VERSION "eCMP INFO-DIV vehicle review 2026-11-03; 125000 bit/s; PSA-RE 67f7581e7622410efdbb29c7eda3b86982b9b450; Apache-2.0"

NS_ :

BS_:

BU_: AAS AMPLI AVP BCM BGP BSG BSI BTA BTEL BTT CDC CMB CRT DIAG_TOOL EDP_C EMF FMUX IC ICSV IDVR IVC_D MATT MDS OVIP PDS_C RAD RBG SDCM VTH WLC

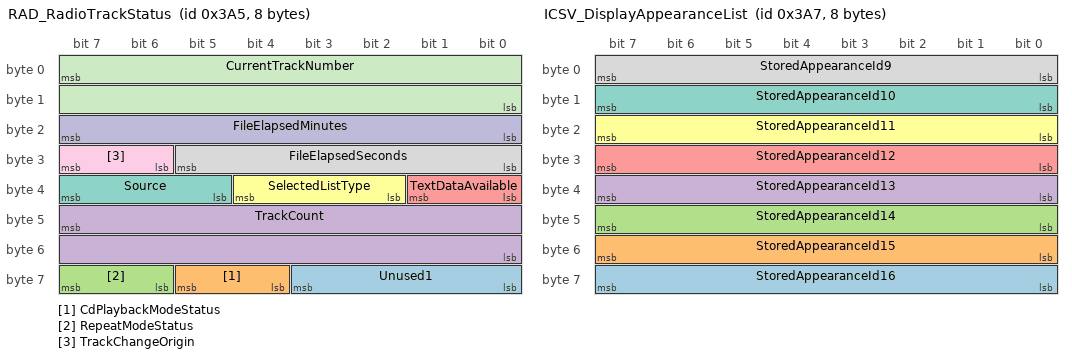
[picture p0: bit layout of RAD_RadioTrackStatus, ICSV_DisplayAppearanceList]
BO_ 933 RAD_RadioTrackStatus: 8 RAD
 SG_ Unused1 : 59|4@0+ (1,0) [0|15] ""  CRT,FMUX,EMF
 SG_ CdPlaybackModeStatus : 61|2@0+ (1,0) [0|3] ""  CRT,FMUX,EMF
 SG_ RepeatModeStatus : 63|2@0+ (1,0) [0|3] ""  CRT,FMUX,EMF
 SG_ TrackCount : 47|16@0+ (1,0) [0|65533] ""  CRT,FMUX,EMF
 SG_ TextDataAvailable : 33|2@0+ (1,0) [0|3] ""  CRT,FMUX,EMF
 SG_ SelectedListType : 36|3@0+ (1,0) [0|7] ""  CRT,FMUX,EMF
 SG_ Source : 39|3@0+ (1,0) [0|7] ""  CRT,FMUX,EMF
 SG_ FileElapsedSeconds : 29|6@0+ (1,0) [0|59] "s"  CRT,FMUX,EMF
 SG_ TrackChangeOrigin : 31|2@0+ (1,0) [0|3] ""  CRT,FMUX,EMF
 SG_ FileElapsedMinutes : 23|8@0+ (1,0) [0|253] "min"  CRT,FMUX,EMF
 SG_ CurrentTrackNumber : 7|16@0+ (1,0) [1|65533] ""  CRT,FMUX,EMF

BO_ 935 ICSV_DisplayAppearanceList: 8 ICSV
 SG_ StoredAppearanceId16 : 63|8@0+ (1,0) [0|255] ""  BTEL,OVIP
 SG_ StoredAppearanceId15 : 55|8@0+ (1,0) [0|255] ""  BTEL,OVIP
 SG_ StoredAppearanceId14 : 47|8@0+ (1,0) [0|255] ""  BTEL,OVIP
 SG_ StoredAppearanceId13 : 39|8@0+ (1,0) [0|255] ""  BTEL,OVIP
 SG_ StoredAppearanceId12 : 31|8@0+ (1,0) [0|255] ""  BTEL,OVIP
 SG_ StoredAppearanceId11 : 23|8@0+ (1,0) [0|255] ""  BTEL,OVIP
 SG_ StoredAppearanceId10 : 15|8@0+ (1,0) [0|255] ""  BTEL,OVIP
 SG_ StoredAppearanceId9 : 7|8@0+ (1,0) [0|255] ""  BTEL,OVIP

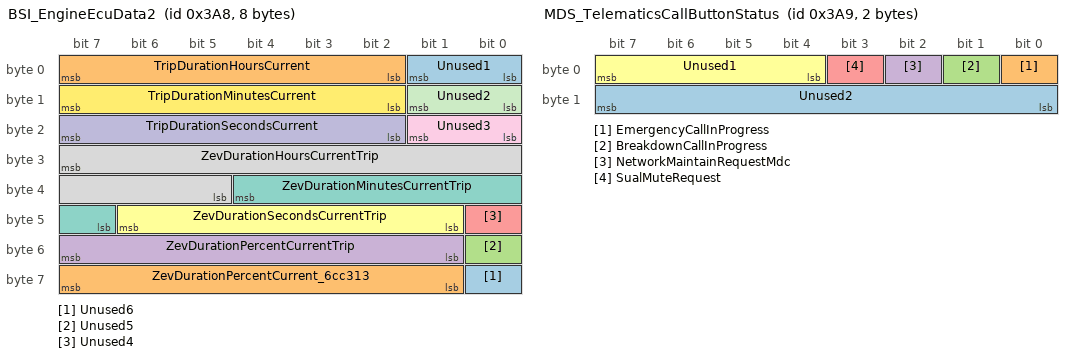
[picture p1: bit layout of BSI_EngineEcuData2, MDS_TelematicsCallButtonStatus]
BO_ 936 BSI_EngineEcuData2: 8 BSI
 SG_ Unused6 : 56|1@0+ (1,0) [0|1] ""  OVIP,RAD
 SG_ ZevDurationPercentCurrent_6cc313 : 63|7@0+ (1,0) [0|100] "%"  OVIP,RAD
 SG_ Unused5 : 48|1@0+ (1,0) [0|1] ""  OVIP,RAD
 SG_ ZevDurationPercentCurrentTrip : 55|7@0+ (1,0) [0|100] "%"  OVIP,RAD
 SG_ Unused4 : 40|1@0+ (1,0) [0|1] ""  OVIP,RAD
 SG_ ZevDurationSecondsCurrentTrip : 46|6@0+ (1,0) [0|59] "s"  OVIP,RAD
 SG_ ZevDurationMinutesCurrentTrip : 36|6@0+ (1,0) [0|59] "min"  OVIP,RAD
 SG_ ZevDurationHoursCurrentTrip : 31|11@0+ (1,0) [0|2000] "h"  OVIP,RAD
 SG_ Unused3 : 17|2@0+ (1,0) [0|3] ""  OVIP,RAD
 SG_ TripDurationSecondsCurrent : 23|6@0+ (1,0) [0|59] "s"  OVIP,RAD
 SG_ Unused2 : 9|2@0+ (1,0) [0|3] ""  OVIP,RAD
 SG_ TripDurationMinutesCurrent : 15|6@0+ (1,0) [0|59] "min"  OVIP,RAD
 SG_ Unused1 : 1|2@0+ (1,0) [0|3] ""  OVIP,RAD
 SG_ TripDurationHoursCurrent : 7|6@0+ (1,0) [0|62] "h"  OVIP,RAD

BO_ 937 MDS_TelematicsCallButtonStatus: 2 MDS
 SG_ Unused2 : 15|8@0+ (1,0) [0|255] ""  OVIP,BTEL,BSI,RAD
 SG_ EmergencyCallInProgress : 0|1@0+ (1,0) [0|1] ""  OVIP,BTEL,BSI,RAD
 SG_ BreakdownCallInProgress : 1|1@0+ (1,0) [0|1] ""  OVIP,BTEL,BSI,RAD
 SG_ NetworkMaintainRequestMdc : 2|1@0+ (1,0) [0|1] ""  OVIP,BTEL,BSI,RAD
 SG_ SualMuteRequest : 3|1@0+ (1,0) [0|1] ""  OVIP,BTEL,BSI,RAD
 SG_ Unused1 : 7|4@0+ (1,0) [0|15] ""  OVIP,BTEL,BSI,RAD

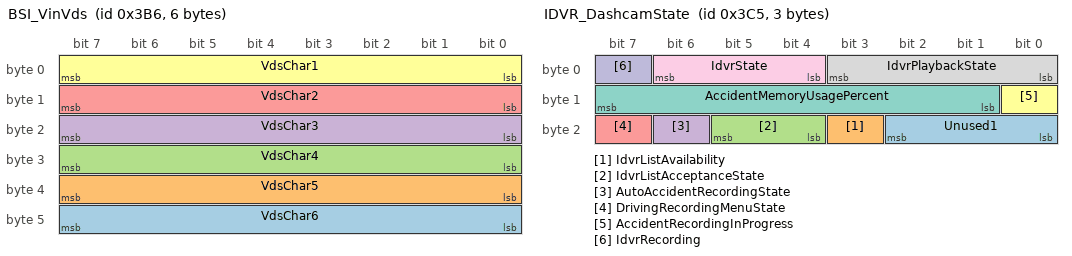
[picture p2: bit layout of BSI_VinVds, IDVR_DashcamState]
BO_ 950 BSI_VinVds: 6 BSI
 SG_ VdsChar6 : 47|8@0+ (1,0) [0|255] "raw"  OVIP,EMF,CDC,RAD,MDS,BGP,BTEL
 SG_ VdsChar5 : 39|8@0+ (1,0) [0|255] "raw"  OVIP,EMF,CDC,RAD,MDS,BGP,BTEL
 SG_ VdsChar4 : 31|8@0+ (1,0) [0|255] "raw"  OVIP,EMF,CDC,RAD,MDS,BGP,BTEL
 SG_ VdsChar3 : 23|8@0+ (1,0) [0|255] "raw"  OVIP,EMF,CDC,RAD,MDS,BGP,BTEL
 SG_ VdsChar2 : 15|8@0+ (1,0) [0|255] "raw"  OVIP,EMF,CDC,RAD,MDS,BGP,BTEL
 SG_ VdsChar1 : 7|8@0+ (1,0) [0|255] "raw"  OVIP,EMF,CDC,RAD,MDS,BGP,BTEL

BO_ 961 SDCM_WirelessChargerRxFlo_ebe318: 8 SDCM
 SG_ FlowPadding5 m3 : 63|8@0+ (1,0) [0|255] "raw"  WLC
 SG_ FirstData6 m1 : 63|8@0+ (1,0) [0|255] "raw"  WLC
 SG_ UnknownData7 m4 : 63|8@0+ (1,0) [0|255] "raw"  WLC
 SG_ ConsecutiveData7 m2 : 63|8@0+ (1,0) [0|255] "raw"  WLC
 SG_ SingleData7 m0 : 63|8@0+ (1,0) [0|255] "raw"  WLC
 SG_ FlowPadding4 m3 : 55|8@0+ (1,0) [0|255] "raw"  WLC
 SG_ FirstData5 m1 : 55|8@0+ (1,0) [0|255] "raw"  WLC
 SG_ UnknownData6 m4 : 55|8@0+ (1,0) [0|255] "raw"  WLC
 SG_ ConsecutiveData6 m2 : 55|8@0+ (1,0) [0|255] "raw"  WLC
 SG_ SingleData6 m0 : 55|8@0+ (1,0) [0|255] "raw"  WLC
 SG_ FlowPadding3 m3 : 47|8@0+ (1,0) [0|255] "raw"  WLC
 SG_ FirstData4 m1 : 47|8@0+ (1,0) [0|255] "raw"  WLC
 SG_ UnknownData5 m4 : 47|8@0+ (1,0) [0|255] "raw"  WLC
 SG_ ConsecutiveData5 m2 : 47|8@0+ (1,0) [0|255] "raw"  WLC
 SG_ SingleData5 m0 : 47|8@0+ (1,0) [0|255] "raw"  WLC
 SG_ FlowPadding2 m3 : 39|8@0+ (1,0) [0|255] "raw"  WLC
 SG_ FirstData3 m1 : 39|8@0+ (1,0) [0|255] "raw"  WLC
 SG_ UnknownData4 m4 : 39|8@0+ (1,0) [0|255] "raw"  WLC
 SG_ ConsecutiveData4 m2 : 39|8@0+ (1,0) [0|255] "raw"  WLC
 SG_ SingleData4 m0 : 39|8@0+ (1,0) [0|255] "raw"  WLC
 SG_ FlowPadding1 m3 : 31|8@0+ (1,0) [0|255] "raw"  WLC
 SG_ FirstData2 m1 : 31|8@0+ (1,0) [0|255] "raw"  WLC
 SG_ UnknownData3 m4 : 31|8@0+ (1,0) [0|255] "raw"  WLC
 SG_ ConsecutiveData3 m2 : 31|8@0+ (1,0) [0|255] "raw"  WLC
 SG_ SingleData3 m0 : 31|8@0+ (1,0) [0|255] "raw"  WLC
 SG_ FirstData1 m1 : 23|8@0+ (1,0) [0|255] "raw"  WLC
 SG_ UnknownData2 m4 : 23|8@0+ (1,0) [0|255] "raw"  WLC
 SG_ ConsecutiveData2 m2 : 23|8@0+ (1,0) [0|255] "raw"  WLC
 SG_ SingleData2 m0 : 23|8@0+ (1,0) [0|255] "raw"  WLC
 SG_ SeparationTimeRaw m3 : 23|8@0+ (1,0) [0|255] "raw"  WLC
 SG_ UnknownData1 m4 : 15|8@0+ (1,0) [0|255] "raw"  WLC
 SG_ ConsecutiveData1 m2 : 15|8@0+ (1,0) [0|255] "raw"  WLC
 SG_ SingleData1 m0 : 15|8@0+ (1,0) [0|255] "raw"  WLC
 SG_ BlockSize m3 : 15|8@0+ (1,0) [0|255] "raw"  WLC
 SG_ UnknownPciLow m4 : 3|4@0+ (1,0) [0|15] "raw"  WLC
 SG_ FlowStatus m3 : 3|4@0+ (1,0) [0|15] "raw"  WLC
 SG_ ConsecutiveSequence m2 : 3|4@0+ (1,0) [0|15] "raw"  WLC
 SG_ FirstFrameLength m1 : 3|12@0+ (1,0) [0|4095] "raw"  WLC
 SG_ SingleFrameLength m0 : 3|4@0+ (1,0) [0|15] "raw"  WLC
 SG_ IsoTpFrameType M : 7|4@0+ (1,0) [0|15] ""  WLC

BO_ 965 IDVR_DashcamState: 3 IDVR
 SG_ Unused1 : 18|3@0+ (1,0) [0|7] ""  BTEL,OVIP
 SG_ IdvrListAvailability : 19|1@0+ (1,0) [0|1] ""  BTEL,OVIP
 SG_ IdvrListAcceptanceState : 21|2@0+ (1,0) [0|3] ""  BTEL,OVIP
 SG_ AutoAccidentRecordingState : 22|1@0+ (1,0) [0|1] ""  BTEL,OVIP
 SG_ DrivingRecordingMenuState : 23|1@0+ (1,0) [0|1] ""  BTEL,OVIP
 SG_ AccidentRecordingInProgress : 8|1@0+ (1,0) [0|1] ""  BTEL,OVIP
 SG_ AccidentMemoryUsagePercent : 15|7@0+ (1,0) [0|100] "%"  BTEL,OVIP
 SG_ IdvrPlaybackState : 3|4@0+ (1,0) [0|15] ""  BTEL,OVIP
 SG_ IdvrState : 6|3@0+ (1,0) [0|7] ""  BTEL,OVIP
 SG_ IdvrRecording : 7|1@0+ (1,0) [0|1] ""  BTEL,OVIP

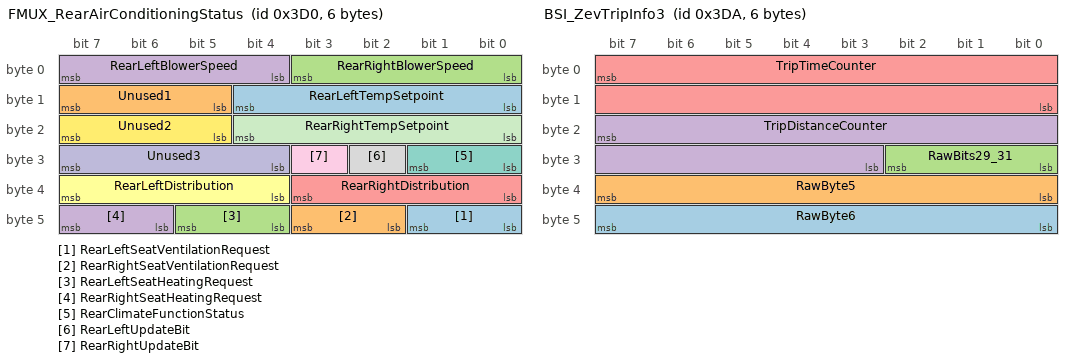
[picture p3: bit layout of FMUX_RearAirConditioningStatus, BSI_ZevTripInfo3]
BO_ 976 FMUX_RearAirConditioningStatus: 6 FMUX
 SG_ RearLeftSeatVentilationRequest : 41|2@0+ (1,0) [0|3] ""  ICSV,BTEL,CMB,BSI,OVIP,RAD
 SG_ RearRightSeatVentilationRequest : 43|2@0+ (1,0) [0|3] ""  ICSV,BTEL,CMB,BSI,OVIP,RAD
 SG_ RearLeftSeatHeatingRequest : 45|2@0+ (1,0) [0|3] ""  ICSV,BTEL,CMB,BSI,OVIP,RAD
 SG_ RearRightSeatHeatingRequest : 47|2@0+ (1,0) [0|3] ""  ICSV,BTEL,CMB,BSI,OVIP,RAD
 SG_ RearRightDistribution : 35|4@0+ (1,0) [0|15] ""  ICSV,BTEL,CMB,BSI,OVIP,RAD
 SG_ RearLeftDistribution : 39|4@0+ (1,0) [0|15] ""  ICSV,BTEL,CMB,BSI,OVIP,RAD
 SG_ RearClimateFunctionStatus : 25|2@0+ (1,0) [0|3] ""  ICSV,BTEL,CMB,BSI,OVIP,RAD
 SG_ RearLeftUpdateBit : 26|1@0+ (1,0) [0|1] ""  ICSV,BTEL,CMB,BSI,OVIP,RAD
 SG_ RearRightUpdateBit : 27|1@0+ (1,0) [0|1] ""  ICSV,BTEL,CMB,BSI,OVIP,RAD
 SG_ Unused3 : 31|4@0+ (1,0) [0|15] ""  ICSV,BTEL,CMB,BSI,OVIP,RAD
 SG_ RearRightTempSetpoint : 20|5@0+ (1,0) [0|31] ""  ICSV,BTEL,CMB,BSI,OVIP,RAD
 SG_ Unused2 : 23|3@0+ (1,0) [0|7] ""  ICSV,BTEL,CMB,BSI,OVIP,RAD
 SG_ RearLeftTempSetpoint : 12|5@0+ (1,0) [0|31] ""  ICSV,BTEL,CMB,BSI,OVIP,RAD
 SG_ Unused1 : 15|3@0+ (1,0) [0|7] ""  ICSV,BTEL,CMB,BSI,OVIP,RAD
 SG_ RearRightBlowerSpeed : 3|4@0+ (1,0) [0|15] ""  ICSV,BTEL,CMB,BSI,OVIP,RAD
 SG_ RearLeftBlowerSpeed : 7|4@0+ (1,0) [0|15] ""  ICSV,BTEL,CMB,BSI,OVIP,RAD

BO_ 982 MDS_TelediagnosisRequest: 1 MDS
 SG_ Unused1 : 5|6@0+ (1,0) [0|63] ""  BSI
 SG_ TldiagFunctionRequest : 7|2@0+ (1,0) [0|3] ""  BSI

BO_ 986 BSI_ZevTripInfo3: 6 BSI
 SG_ RawByte6 : 47|8@0+ (1,0) [0|255] "raw" Vector__XXX
 SG_ RawByte5 : 39|8@0+ (1,0) [0|255] "raw" Vector__XXX
 SG_ RawBits29_31 : 26|3@0+ (1,0) [0|7] "raw" Vector__XXX
 SG_ TripDistanceCounter : 23|13@0+ (1,0) [0|5000] "km"  BTEL,CMB,MDS,OVIP
 SG_ TripTimeCounter : 7|16@0+ (1,0) [0|65535] "s"  BTEL,CMB,MDS,OVIP

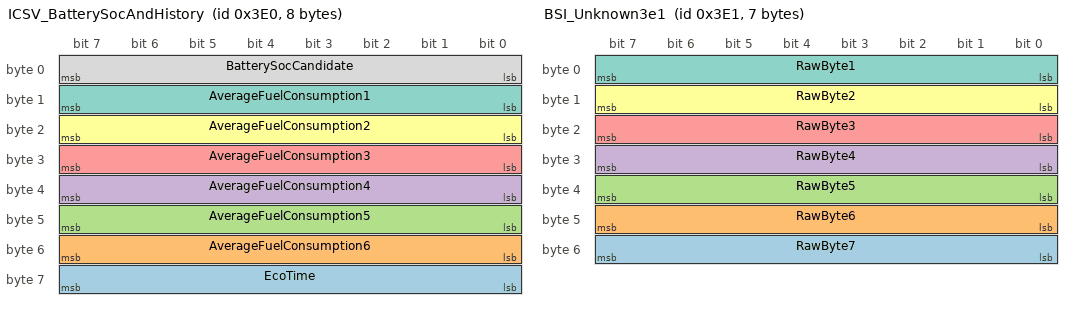
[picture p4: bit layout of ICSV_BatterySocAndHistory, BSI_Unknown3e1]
BO_ 992 ICSV_BatterySocAndHistory: 8 ICSV
 SG_ EcoTime : 63|8@0+ (1,0) [0|100] "%"  CMB,MATT,BTEL,OVIP,RAD
 SG_ AverageFuelConsumption6 : 55|8@0+ (0.1,0) [0|25] "L/100km"  CMB,MATT,BTEL,OVIP,RAD
 SG_ AverageFuelConsumption5 : 47|8@0+ (0.1,0) [0|25] "L/100km"  CMB,MATT,BTEL,OVIP,RAD
 SG_ AverageFuelConsumption4 : 39|8@0+ (0.1,0) [0|25] "L/100km"  CMB,MATT,BTEL,OVIP,RAD
 SG_ AverageFuelConsumption3 : 31|8@0+ (0.1,0) [0|25] "L/100km"  CMB,MATT,BTEL,OVIP,RAD
 SG_ AverageFuelConsumption2 : 23|8@0+ (0.1,0) [0|25] "L/100km"  CMB,MATT,BTEL,OVIP,RAD
 SG_ AverageFuelConsumption1 : 15|8@0+ (0.1,0) [0|25] "L/100km"  CMB,MATT,BTEL,OVIP,RAD
 SG_ BatterySocCandidate : 7|8@0+ (1,0) [0|100] "%"  CMB,MATT,BTEL,OVIP,RAD

BO_ 993 BSI_Unknown3e1: 7 BSI
 SG_ RawByte7 : 55|8@0+ (1,0) [0|255] "raw" Vector__XXX
 SG_ RawByte6 : 47|8@0+ (1,0) [0|255] "raw" Vector__XXX
 SG_ RawByte5 : 39|8@0+ (1,0) [0|255] "raw" Vector__XXX
 SG_ RawByte4 : 31|8@0+ (1,0) [0|255] "raw" Vector__XXX
 SG_ RawByte3 : 23|8@0+ (1,0) [0|255] "raw" Vector__XXX
 SG_ RawByte2 : 15|8@0+ (1,0) [0|255] "raw" Vector__XXX
 SG_ RawByte1 : 7|8@0+ (1,0) [0|255] "raw" Vector__XXX

BO_ 994 AMPLI_AmplifierStatus: 2 AMPLI
 SG_ Unused1 : 5|14@0+ (1,0) [0|16383] ""  OVIP,BSI,RAD
 SG_ AudioDynamicModeStatus : 7|2@0+ (1,0) [0|3] ""  OVIP,BSI,RAD

BO_ 995 RAD_PhoneStatusAck: 1 RAD
 SG_ SegmentationAckStream : 7|8@0+ (1,0) [0|255] ""  EMF

BO_ 996 RAD_UsbUpdateStatus: 8 RAD
 SG_ FlowPadding5 m3 : 63|8@0+ (1,0) [0|255] "raw"  CRT,FMUX,EMF
 SG_ FirstData6 m1 : 63|8@0+ (1,0) [0|255] "raw"  CRT,FMUX,EMF
 SG_ UnknownData7 m4 : 63|8@0+ (1,0) [0|255] "raw"  CRT,FMUX,EMF
 SG_ ConsecutiveData7 m2 : 63|8@0+ (1,0) [0|255] "raw"  CRT,FMUX,EMF
 SG_ SingleData7 m0 : 63|8@0+ (1,0) [0|255] "raw"  CRT,FMUX,EMF
 SG_ FlowPadding4 m3 : 55|8@0+ (1,0) [0|255] "raw"  CRT,FMUX,EMF
 SG_ FirstData5 m1 : 55|8@0+ (1,0) [0|255] "raw"  CRT,FMUX,EMF
 SG_ UnknownData6 m4 : 55|8@0+ (1,0) [0|255] "raw"  CRT,FMUX,EMF
 SG_ ConsecutiveData6 m2 : 55|8@0+ (1,0) [0|255] "raw"  CRT,FMUX,EMF
 SG_ SingleData6 m0 : 55|8@0+ (1,0) [0|255] "raw"  CRT,FMUX,EMF
 SG_ FlowPadding3 m3 : 47|8@0+ (1,0) [0|255] "raw"  CRT,FMUX,EMF
 SG_ FirstData4 m1 : 47|8@0+ (1,0) [0|255] "raw"  CRT,FMUX,EMF
 SG_ UnknownData5 m4 : 47|8@0+ (1,0) [0|255] "raw"  CRT,FMUX,EMF
 SG_ ConsecutiveData5 m2 : 47|8@0+ (1,0) [0|255] "raw"  CRT,FMUX,EMF
 SG_ SingleData5 m0 : 47|8@0+ (1,0) [0|255] "raw"  CRT,FMUX,EMF
 SG_ FlowPadding2 m3 : 39|8@0+ (1,0) [0|255] "raw"  CRT,FMUX,EMF
 SG_ FirstData3 m1 : 39|8@0+ (1,0) [0|255] "raw"  CRT,FMUX,EMF
 SG_ UnknownData4 m4 : 39|8@0+ (1,0) [0|255] "raw"  CRT,FMUX,EMF
 SG_ ConsecutiveData4 m2 : 39|8@0+ (1,0) [0|255] "raw"  CRT,FMUX,EMF
 SG_ SingleData4 m0 : 39|8@0+ (1,0) [0|255] "raw"  CRT,FMUX,EMF
 SG_ FlowPadding1 m3 : 31|8@0+ (1,0) [0|255] "raw"  CRT,FMUX,EMF
 SG_ FirstData2 m1 : 31|8@0+ (1,0) [0|255] "raw"  CRT,FMUX,EMF
 SG_ UnknownData3 m4 : 31|8@0+ (1,0) [0|255] "raw"  CRT,FMUX,EMF
 SG_ ConsecutiveData3 m2 : 31|8@0+ (1,0) [0|255] "raw"  CRT,FMUX,EMF
 SG_ SingleData3 m0 : 31|8@0+ (1,0) [0|255] "raw"  CRT,FMUX,EMF
 SG_ FirstData1 m1 : 23|8@0+ (1,0) [0|255] "raw"  CRT,FMUX,EMF
 SG_ UnknownData2 m4 : 23|8@0+ (1,0) [0|255] "raw"  CRT,FMUX,EMF
 SG_ ConsecutiveData2 m2 : 23|8@0+ (1,0) [0|255] "raw"  CRT,FMUX,EMF
 SG_ SingleData2 m0 : 23|8@0+ (1,0) [0|255] "raw"  CRT,FMUX,EMF
 SG_ SeparationTimeRaw m3 : 23|8@0+ (1,0) [0|255] "raw"  CRT,FMUX,EMF
 SG_ UnknownData1 m4 : 15|8@0+ (1,0) [0|255] "raw"  CRT,FMUX,EMF
 SG_ ConsecutiveData1 m2 : 15|8@0+ (1,0) [0|255] "raw"  CRT,FMUX,EMF
 SG_ SingleData1 m0 : 15|8@0+ (1,0) [0|255] "raw"  CRT,FMUX,EMF
 SG_ BlockSize m3 : 15|8@0+ (1,0) [0|255] "raw"  CRT,FMUX,EMF
 SG_ UnknownPciLow m4 : 3|4@0+ (1,0) [0|15] "raw"  CRT,FMUX,EMF
 SG_ FlowStatus m3 : 3|4@0+ (1,0) [0|15] "raw"  CRT,FMUX,EMF
 SG_ ConsecutiveSequence m2 : 3|4@0+ (1,0) [0|15] "raw"  CRT,FMUX,EMF
 SG_ FirstFrameLength m1 : 3|12@0+ (1,0) [0|4095] "raw"  CRT,FMUX,EMF
 SG_ SingleFrameLength m0 : 3|4@0+ (1,0) [0|15] "raw"  CRT,FMUX,EMF
 SG_ IsoTpFrameType M : 7|4@0+ (1,0) [0|15] ""  CRT,FMUX,EMF

BO_ 997 ICSV_RadioStatusPanel: 3 ICSV
 SG_ Knob2StepCounter : 23|8@0+ (1,0) [0|255] ""  EMF
 SG_ Knob2SyncRequest : 8|1@0+ (1,0) [0|1] ""  EMF
 SG_ Unused1 : 9|1@0+ (1,0) [0|1] ""  EMF
 SG_ ListOpenRequest : 10|1@0+ (1,0) [0|1] ""  EMF
 SG_ List : 11|1@0+ (1,0) [0|1] ""  EMF
 SG_ Dark : 12|1@0+ (1,0) [0|1] ""  EMF
 SG_ PhoneMenuOpenRequest : 13|1@0+ (1,0) [0|1] ""  EMF
 SG_ Escape : 14|1@0+ (1,0) [0|1] ""  EMF
 SG_ Ok : 15|1@0+ (1,0) [0|1] ""  EMF
 SG_ Left : 0|1@0+ (1,0) [0|1] ""  EMF
 SG_ Right : 1|1@0+ (1,0) [0|1] ""  EMF
 SG_ Down : 2|1@0+ (1,0) [0|1] ""  EMF
 SG_ Up : 3|1@0+ (1,0) [0|1] ""  EMF
 SG_ ModeDark : 4|1@0+ (1,0) [0|1] ""  EMF
 SG_ Mode : 5|1@0+ (1,0) [0|1] ""  EMF
 SG_ Menu : 6|1@0+ (1,0) [0|1] ""  EMF
 SG_ NewsMenuOpenRequest : 7|1@0+ (1,0) [0|1] ""  EMF

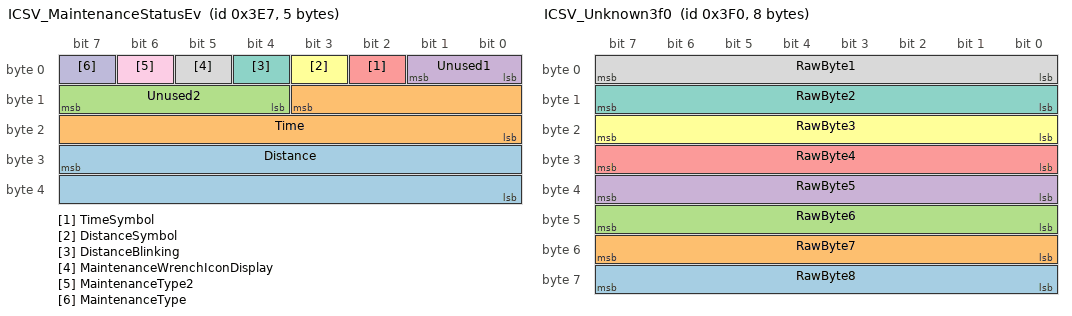
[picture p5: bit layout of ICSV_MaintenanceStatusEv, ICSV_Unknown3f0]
BO_ 999 ICSV_MaintenanceStatusEv: 5 ICSV
 SG_ Distance : 31|16@0+ (20,0) [0|140000] "km"  CMB,MATT,BGP,MDS,BTEL,OVIP,RAD
 SG_ Time : 11|12@0+ (1,0) [0|730] "day"  CMB,MATT,BGP,MDS,BTEL,OVIP,RAD
 SG_ Unused2 : 15|4@0+ (1,0) [0|15] ""  CMB,MATT,BGP,MDS,BTEL,OVIP,RAD
 SG_ Unused1 : 1|2@0+ (1,0) [0|3] ""  CMB,MATT,BGP,MDS,BTEL,OVIP,RAD
 SG_ TimeSymbol : 2|1@0+ (1,0) [0|1] ""  CMB,MATT,BGP,MDS,BTEL,OVIP,RAD
 SG_ DistanceSymbol : 3|1@0+ (1,0) [0|1] ""  CMB,MATT,BGP,MDS,BTEL,OVIP,RAD
 SG_ DistanceBlinking : 4|1@0+ (1,0) [0|1] ""  CMB,MATT,BGP,MDS,BTEL,OVIP,RAD
 SG_ MaintenanceWrenchIconDisplay : 5|1@0+ (1,0) [0|1] ""  CMB,MATT,BGP,MDS,BTEL,OVIP,RAD
 SG_ MaintenanceType2 : 6|1@0+ (1,0) [0|1] ""  CMB,MATT,BGP,MDS,BTEL,OVIP,RAD
 SG_ MaintenanceType : 7|1@0+ (1,0) [0|1] ""  CMB,MATT,BGP,MDS,BTEL,OVIP,RAD

BO_ 1000 BSI_EngineAdinControl3: 8 BSI
 SG_ ZevDistanceTrip2 : 55|16@0+ (1,0) [0|50000] "km"  BTEL,OVIP,RAD
 SG_ ZevDistanceTrip1 : 39|16@0+ (1,0) [0|50000] "km"  BTEL,OVIP,RAD
 SG_ ZevDistanceCurrentTrip : 23|16@0+ (0.1,0) [0|5000] "km"  BTEL,OVIP,RAD
 SG_ TripDistanceCurrent : 7|16@0+ (0.1,0) [0|5000] "km"  BTEL,OVIP,RAD

BO_ 1001 CMB_GearboxData: 1 CMB
 SG_ SegmentationAckStream : 7|8@0+ (1,0) [0|255] ""  BTEL,OVIP

BO_ 1008 ICSV_Unknown3f0: 8 ICSV
 SG_ RawByte8 : 63|8@0+ (1,0) [0|255] "raw" Vector__XXX
 SG_ RawByte7 : 55|8@0+ (1,0) [0|255] "raw" Vector__XXX
 SG_ RawByte6 : 47|8@0+ (1,0) [0|255] "raw" Vector__XXX
 SG_ RawByte5 : 39|8@0+ (1,0) [0|255] "raw" Vector__XXX
 SG_ RawByte4 : 31|8@0+ (1,0) [0|255] "raw" Vector__XXX
 SG_ RawByte3 : 23|8@0+ (1,0) [0|255] "raw" Vector__XXX
 SG_ RawByte2 : 15|8@0+ (1,0) [0|255] "raw" Vector__XXX
 SG_ RawByte1 : 7|8@0+ (1,0) [0|255] "raw" Vector__XXX

BO_ 1009 ICSV_CdChangerStatusAck: 1 ICSV
 SG_ SegmentationAckStream : 7|8@0+ (1,0) [0|255] ""  CDC

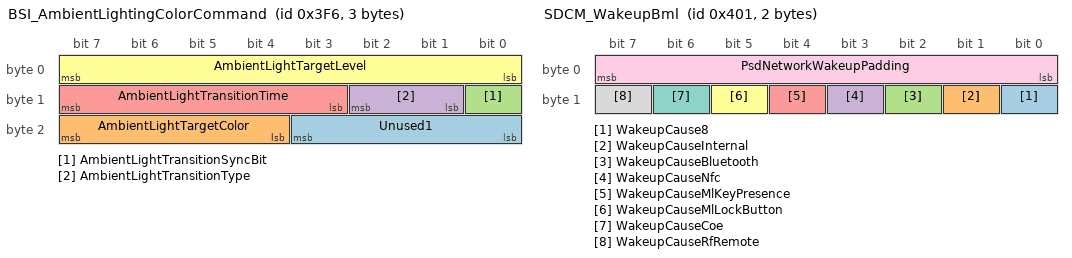
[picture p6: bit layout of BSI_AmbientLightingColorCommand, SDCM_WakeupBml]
BO_ 1014 BSI_AmbientLightingColorCommand: 3 BSI
 SG_ Unused1 : 19|4@0+ (1,0) [0|15] ""  CMB
 SG_ AmbientLightTargetColor : 23|4@0+ (1,0) [0|15] ""  CMB
 SG_ AmbientLightTransitionSyncBit : 8|1@0+ (1,0) [0|1] ""  CMB
 SG_ AmbientLightTransitionType : 10|2@0+ (1,0) [0|3] ""  CMB
 SG_ AmbientLightTransitionTime : 15|5@0+ (1,0) [0|31] ""  CMB
 SG_ AmbientLightTargetLevel : 7|8@0+ (1,0) [0|255] ""  CMB

BO_ 1025 SDCM_WakeupBml: 2 SDCM
 SG_ WakeupCause8 : 8|1@0+ (1,0) [0|1] ""  BSI
 SG_ WakeupCauseInternal : 9|1@0+ (1,0) [0|1] ""  BSI
 SG_ WakeupCauseBluetooth : 10|1@0+ (1,0) [0|1] ""  BSI
 SG_ WakeupCauseNfc : 11|1@0+ (1,0) [0|1] ""  BSI
 SG_ WakeupCauseMlKeyPresence : 12|1@0+ (1,0) [0|1] ""  BSI
 SG_ WakeupCauseMlLockButton : 13|1@0+ (1,0) [0|1] ""  BSI
 SG_ WakeupCauseCoe : 14|1@0+ (1,0) [0|1] ""  BSI
 SG_ WakeupCauseRfRemote : 15|1@0+ (1,0) [0|1] ""  BSI
 SG_ PsdNetworkWakeupPadding : 7|8@0+ (1,0) [0|255] ""  BSI

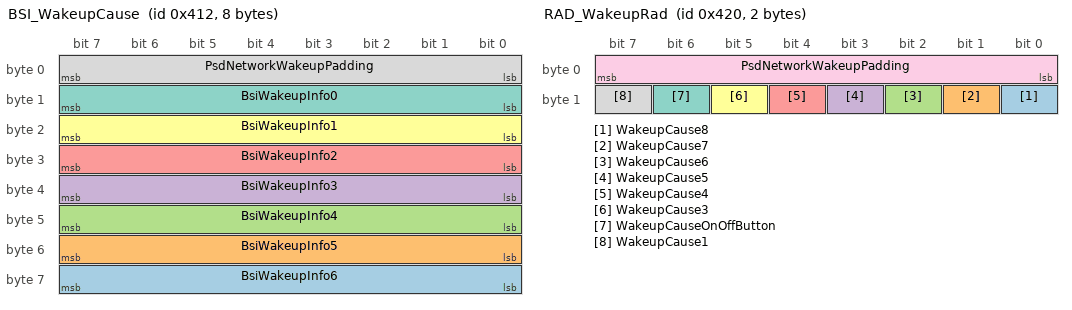
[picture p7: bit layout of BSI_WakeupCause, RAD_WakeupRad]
BO_ 1042 BSI_WakeupCause: 8 BSI
 SG_ BsiWakeupInfo6 : 63|8@0+ (1,0) [0|255] "" Vector__XXX
 SG_ BsiWakeupInfo5 : 55|8@0+ (1,0) [0|255] "" Vector__XXX
 SG_ BsiWakeupInfo4 : 47|8@0+ (1,0) [0|255] "" Vector__XXX
 SG_ BsiWakeupInfo3 : 39|8@0+ (1,0) [0|255] "" Vector__XXX
 SG_ BsiWakeupInfo2 : 31|8@0+ (1,0) [0|255] "" Vector__XXX
 SG_ BsiWakeupInfo1 : 23|8@0+ (1,0) [0|255] "" Vector__XXX
 SG_ BsiWakeupInfo0 : 15|8@0+ (1,0) [0|255] "" Vector__XXX
 SG_ PsdNetworkWakeupPadding : 7|8@0+ (1,0) [0|255] "" Vector__XXX

BO_ 1056 RAD_WakeupRad: 2 RAD
 SG_ WakeupCause8 : 8|1@0+ (1,0) [0|1] ""  BSI
 SG_ WakeupCause7 : 9|1@0+ (1,0) [0|1] ""  BSI
 SG_ WakeupCause6 : 10|1@0+ (1,0) [0|1] ""  BSI
 SG_ WakeupCause5 : 11|1@0+ (1,0) [0|1] ""  BSI
 SG_ WakeupCause4 : 12|1@0+ (1,0) [0|1] ""  BSI
 SG_ WakeupCause3 : 13|1@0+ (1,0) [0|1] ""  BSI
 SG_ WakeupCauseOnOffButton : 14|1@0+ (1,0) [0|1] ""  BSI
 SG_ WakeupCause1 : 15|1@0+ (1,0) [0|1] ""  BSI
 SG_ PsdNetworkWakeupPadding : 7|8@0+ (1,0) [0|255] ""  BSI

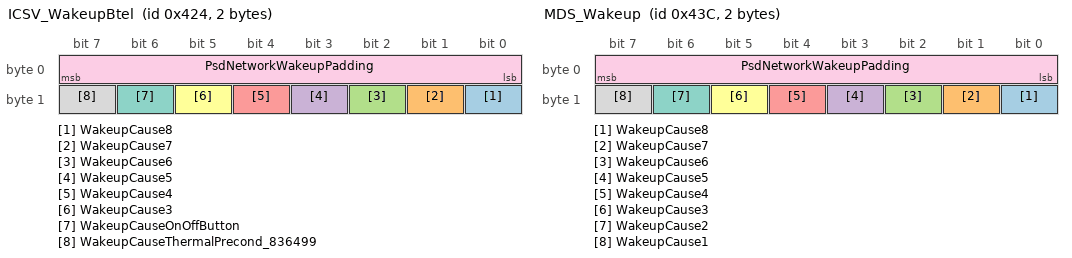
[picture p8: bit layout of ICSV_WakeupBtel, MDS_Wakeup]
BO_ 1060 ICSV_WakeupBtel: 2 ICSV
 SG_ WakeupCause8 : 8|1@0+ (1,0) [0|1] ""  BSI
 SG_ WakeupCause7 : 9|1@0+ (1,0) [0|1] ""  BSI
 SG_ WakeupCause6 : 10|1@0+ (1,0) [0|1] ""  BSI
 SG_ WakeupCause5 : 11|1@0+ (1,0) [0|1] ""  BSI
 SG_ WakeupCause4 : 12|1@0+ (1,0) [0|1] ""  BSI
 SG_ WakeupCause3 : 13|1@0+ (1,0) [0|1] ""  BSI
 SG_ WakeupCauseOnOffButton : 14|1@0+ (1,0) [0|1] ""  BSI
 SG_ WakeupCauseThermalPrecond_836499 : 15|1@0+ (1,0) [0|1] ""  BSI
 SG_ PsdNetworkWakeupPadding : 7|8@0+ (1,0) [0|255] ""  BSI

BO_ 1084 MDS_Wakeup: 2 MDS
 SG_ WakeupCause8 : 8|1@0+ (1,0) [0|1] ""  BSI
 SG_ WakeupCause7 : 9|1@0+ (1,0) [0|1] ""  BSI
 SG_ WakeupCause6 : 10|1@0+ (1,0) [0|1] ""  BSI
 SG_ WakeupCause5 : 11|1@0+ (1,0) [0|1] ""  BSI
 SG_ WakeupCause4 : 12|1@0+ (1,0) [0|1] ""  BSI
 SG_ WakeupCause3 : 13|1@0+ (1,0) [0|1] ""  BSI
 SG_ WakeupCause2 : 14|1@0+ (1,0) [0|1] ""  BSI
 SG_ WakeupCause1 : 15|1@0+ (1,0) [0|1] ""  BSI
 SG_ PsdNetworkWakeupPadding : 7|8@0+ (1,0) [0|255] ""  BSI

BO_ 1142 BSI_EventAck: 1 BSI
 SG_ UceDiagnosticResponse : 7|8@0+ (1,0) [0|255] ""  CRT,OVIP,CDC,CMB,FMUX,RAD,VTH,MATT,EMF,AAS,AVP,BTEL,SDCM,IVC_D

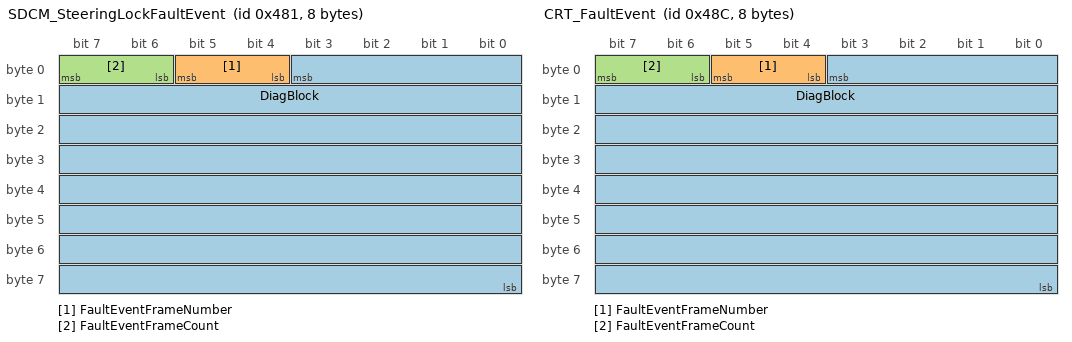
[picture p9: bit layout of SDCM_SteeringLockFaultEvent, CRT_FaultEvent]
BO_ 1153 SDCM_SteeringLockFaultEvent: 8 SDCM
 SG_ DiagBlock : 3|60@0+ (1,0) [0|1152921504606846975] ""  BSI
 SG_ FaultEventFrameNumber : 5|2@0+ (1,0) [0|3] ""  BSI
 SG_ FaultEventFrameCount : 7|2@0+ (1,0) [0|3] ""  BSI

BO_ 1164 CRT_FaultEvent: 8 CRT
 SG_ DiagBlock : 3|60@0+ (1,0) [0|1152921504606846975] ""  BSI
 SG_ FaultEventFrameNumber : 5|2@0+ (1,0) [0|3] ""  BSI
 SG_ FaultEventFrameCount : 7|2@0+ (1,0) [0|3] ""  BSI

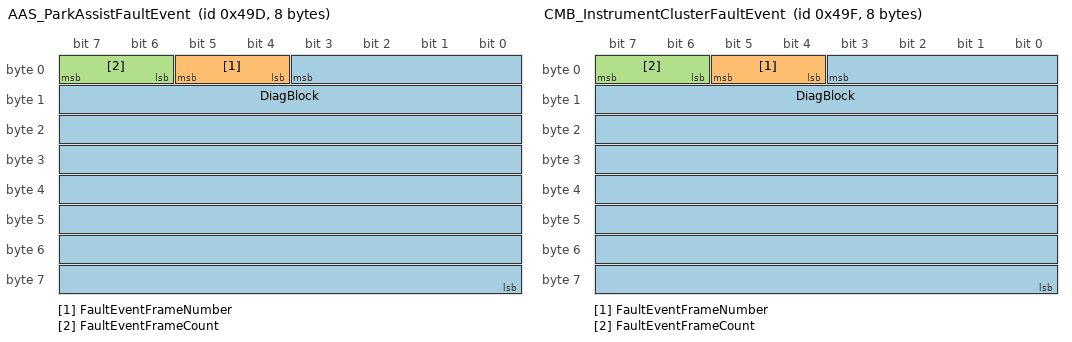
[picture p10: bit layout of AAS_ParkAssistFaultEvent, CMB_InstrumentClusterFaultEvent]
BO_ 1181 AAS_ParkAssistFaultEvent: 8 AAS
 SG_ DiagBlock : 3|60@0+ (1,0) [0|1152921504606846975] ""  BSI
 SG_ FaultEventFrameNumber : 5|2@0+ (1,0) [0|3] ""  BSI
 SG_ FaultEventFrameCount : 7|2@0+ (1,0) [0|3] ""  BSI

BO_ 1183 CMB_InstrumentClusterFaultEvent: 8 CMB
 SG_ DiagBlock : 3|60@0+ (1,0) [0|1152921504606846975] ""  BSI
 SG_ FaultEventFrameNumber : 5|2@0+ (1,0) [0|3] ""  BSI
 SG_ FaultEventFrameCount : 7|2@0+ (1,0) [0|3] ""  BSI

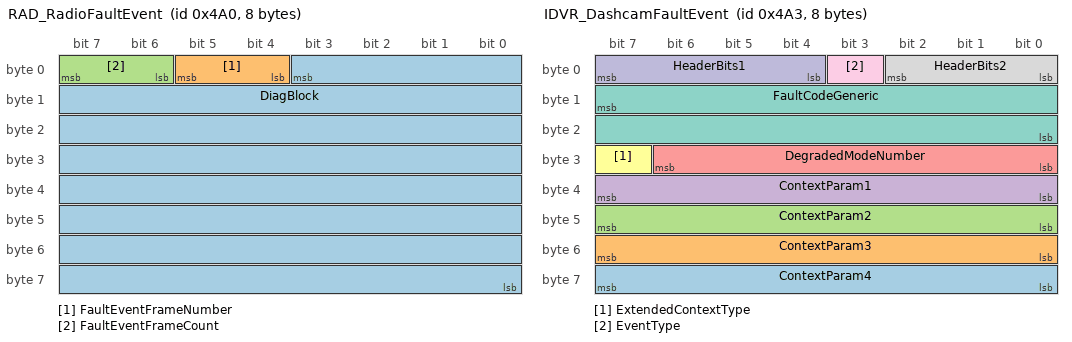
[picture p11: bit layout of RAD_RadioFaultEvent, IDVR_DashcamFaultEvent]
BO_ 1184 RAD_RadioFaultEvent: 8 RAD
 SG_ DiagBlock : 3|60@0+ (1,0) [0|1152921504606846975] ""  BSI
 SG_ FaultEventFrameNumber : 5|2@0+ (1,0) [0|3] ""  BSI
 SG_ FaultEventFrameCount : 7|2@0+ (1,0) [0|3] ""  BSI

BO_ 1187 IDVR_DashcamFaultEvent: 8 IDVR
 SG_ ContextParam4 : 63|8@0+ (1,0) [0|255] ""  BSI
 SG_ ContextParam3 : 55|8@0+ (1,0) [0|255] ""  BSI
 SG_ ContextParam2 : 47|8@0+ (1,0) [0|255] ""  BSI
 SG_ ContextParam1 : 39|8@0+ (1,0) [0|255] ""  BSI
 SG_ DegradedModeNumber : 30|7@0+ (1,0) [0|126] ""  BSI
 SG_ ExtendedContextType : 31|1@0+ (1,0) [0|1] ""  BSI
 SG_ FaultCodeGeneric : 15|16@0+ (1,0) [0|65535] ""  BSI
 SG_ HeaderBits2 : 2|3@0+ (1,0) [0|7] ""  BSI
 SG_ EventType : 3|1@0+ (1,0) [0|1] ""  BSI
 SG_ HeaderBits1 : 7|4@0+ (1,0) [0|15] ""  BSI

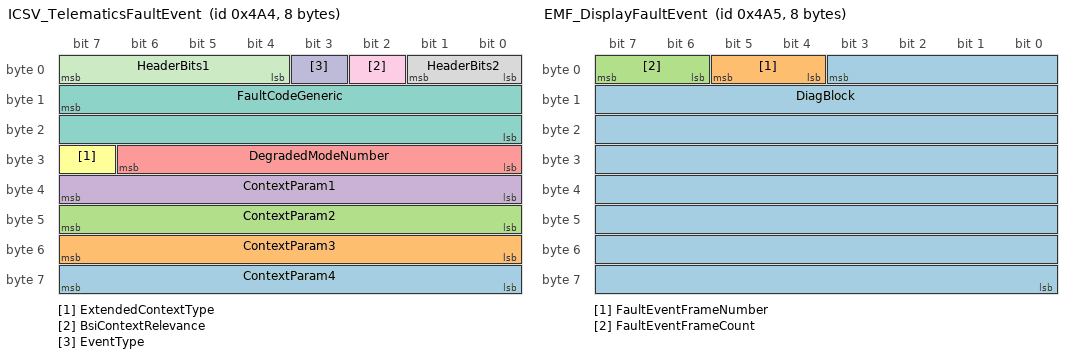
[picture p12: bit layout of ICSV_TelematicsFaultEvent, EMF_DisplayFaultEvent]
BO_ 1188 ICSV_TelematicsFaultEvent: 8 ICSV
 SG_ ContextParam4 : 63|8@0+ (1,0) [0|255] ""  BSI
 SG_ ContextParam3 : 55|8@0+ (1,0) [0|255] ""  BSI
 SG_ ContextParam2 : 47|8@0+ (1,0) [0|255] ""  BSI
 SG_ ContextParam1 : 39|8@0+ (1,0) [0|255] ""  BSI
 SG_ DegradedModeNumber : 30|7@0+ (1,0) [0|126] ""  BSI
 SG_ ExtendedContextType : 31|1@0+ (1,0) [0|1] ""  BSI
 SG_ FaultCodeGeneric : 15|16@0+ (1,0) [0|65535] ""  BSI
 SG_ HeaderBits2 : 1|2@0+ (1,0) [0|3] ""  BSI
 SG_ BsiContextRelevance : 2|1@0+ (1,0) [0|1] ""  BSI
 SG_ EventType : 3|1@0+ (1,0) [0|1] ""  BSI
 SG_ HeaderBits1 : 7|4@0+ (1,0) [0|15] ""  BSI

BO_ 1189 EMF_DisplayFaultEvent: 8 EMF
 SG_ DiagBlock : 3|60@0+ (1,0) [0|1152921504606846975] ""  BSI
 SG_ FaultEventFrameNumber : 5|2@0+ (1,0) [0|3] ""  BSI
 SG_ FaultEventFrameCount : 7|2@0+ (1,0) [0|3] ""  BSI

BO_ 1190 WLC_WirelessChargerFaultEvent: 8 WLC
 SG_ DiagBlock : 3|60@0+ (1,0) [0|1152921504606846975] ""  BSI
 SG_ FaultEventFrameNumber : 5|2@0+ (1,0) [0|3] ""  BSI
 SG_ FaultEventFrameCount : 7|2@0+ (1,0) [0|3] ""  BSI

BO_ 1200 VTH_FaultEvent: 8 VTH
 SG_ DiagBlock : 3|60@0+ (1,0) [0|1152921504606846975] ""  BSI
 SG_ FaultEventFrameNumber : 5|2@0+ (1,0) [0|3] ""  BSI
 SG_ FaultEventFrameCount : 7|2@0+ (1,0) [0|3] ""  BSI

BO_ 1201 CDC_FaultEventCdc: 8 CDC
 SG_ DiagBlock : 3|60@0+ (1,0) [0|1152921504606846975] ""  BSI
 SG_ FaultEventFrameNumber : 5|2@0+ (1,0) [0|3] ""  BSI
 SG_ FaultEventFrameCount : 7|2@0+ (1,0) [0|3] ""  BSI

BO_ 1202 MATT_VinVisData: 8 MATT
 SG_ DiagBlock : 3|60@0+ (1,0) [0|1152921504606846975] ""  BSI
 SG_ FaultEventFrameNumber : 5|2@0+ (1,0) [0|3] ""  BSI
 SG_ FaultEventFrameCount : 7|2@0+ (1,0) [0|3] ""  BSI

BO_ 1203 AVP_FrontParkSensorFaultEvent: 8 AVP
 SG_ DiagBlock : 3|60@0+ (1,0) [0|1152921504606846975] ""  BSI
 SG_ FaultEventFrameNumber : 5|2@0+ (1,0) [0|3] ""  BSI
 SG_ FaultEventFrameCount : 7|2@0+ (1,0) [0|3] ""  BSI

BO_ 1206 BSG_BttFaultEvent: 8 BSG
 SG_ DiagBlock : 3|60@0+ (1,0) [0|1152921504606846975] ""  BSI
 SG_ FaultEventFrameNumber : 5|2@0+ (1,0) [0|3] ""  BSI
 SG_ FaultEventFrameCount : 7|2@0+ (1,0) [0|3] ""  BSI

BO_ 1211 FMUX_MultiplexerFaultEvent: 8 FMUX
 SG_ DiagBlock : 3|60@0+ (1,0) [0|1152921504606846975] ""  BSI
 SG_ FaultEventFrameNumber : 5|2@0+ (1,0) [0|3] ""  BSI
 SG_ FaultEventFrameCount : 7|2@0+ (1,0) [0|3] ""  BSI

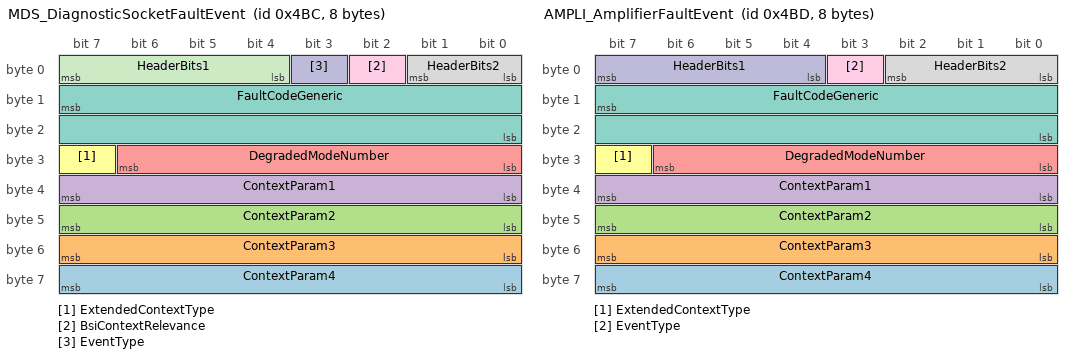
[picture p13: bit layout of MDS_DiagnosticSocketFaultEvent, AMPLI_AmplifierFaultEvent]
BO_ 1212 MDS_DiagnosticSocketFaultEvent: 8 MDS
 SG_ ContextParam4 : 63|8@0+ (1,0) [0|255] ""  BSI
 SG_ ContextParam3 : 55|8@0+ (1,0) [0|255] ""  BSI
 SG_ ContextParam2 : 47|8@0+ (1,0) [0|255] ""  BSI
 SG_ ContextParam1 : 39|8@0+ (1,0) [0|255] ""  BSI
 SG_ DegradedModeNumber : 30|7@0+ (1,0) [0|126] ""  BSI
 SG_ ExtendedContextType : 31|1@0+ (1,0) [0|1] ""  BSI
 SG_ FaultCodeGeneric : 15|16@0+ (1,0) [0|65535] ""  BSI
 SG_ HeaderBits2 : 1|2@0+ (1,0) [0|3] ""  BSI
 SG_ BsiContextRelevance : 2|1@0+ (1,0) [0|1] ""  BSI
 SG_ EventType : 3|1@0+ (1,0) [0|1] ""  BSI
 SG_ HeaderBits1 : 7|4@0+ (1,0) [0|15] ""  BSI

BO_ 1213 AMPLI_AmplifierFaultEvent: 8 AMPLI
 SG_ ContextParam4 : 63|8@0+ (1,0) [0|255] ""  BSI
 SG_ ContextParam3 : 55|8@0+ (1,0) [0|255] ""  BSI
 SG_ ContextParam2 : 47|8@0+ (1,0) [0|255] ""  BSI
 SG_ ContextParam1 : 39|8@0+ (1,0) [0|255] ""  BSI
 SG_ DegradedModeNumber : 30|7@0+ (1,0) [0|126] ""  BSI
 SG_ ExtendedContextType : 31|1@0+ (1,0) [0|1] ""  BSI
 SG_ FaultCodeGeneric : 15|16@0+ (1,0) [0|65535] ""  BSI
 SG_ HeaderBits2 : 2|3@0+ (1,0) [0|7] ""  BSI
 SG_ EventType : 3|1@0+ (1,0) [0|1] ""  BSI
 SG_ HeaderBits1 : 7|4@0+ (1,0) [0|15] ""  BSI

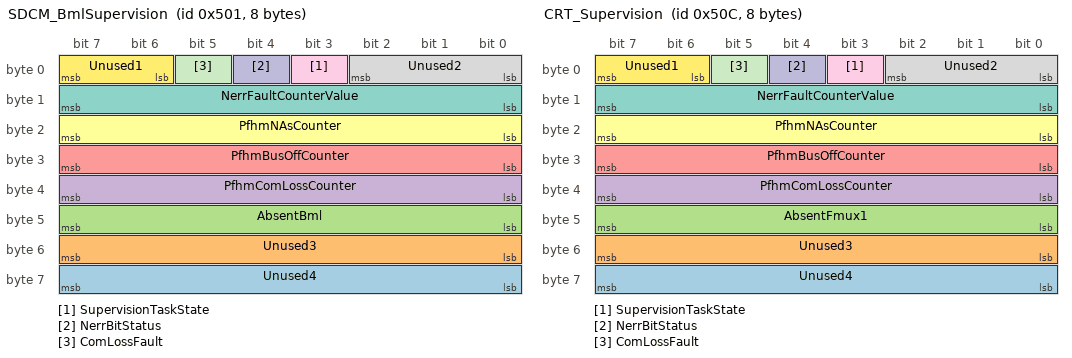
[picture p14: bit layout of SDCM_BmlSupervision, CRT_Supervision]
BO_ 1281 SDCM_BmlSupervision: 8 SDCM
 SG_ Unused4 : 63|8@0+ (1,0) [0|255] "" Vector__XXX
 SG_ Unused3 : 55|8@0+ (1,0) [0|255] "" Vector__XXX
 SG_ AbsentBml : 47|8@0+ (1,0) [0|255] "" Vector__XXX
 SG_ PfhmComLossCounter : 39|8@0+ (1,0) [0|255] "" Vector__XXX
 SG_ PfhmBusOffCounter : 31|8@0+ (1,0) [0|255] "" Vector__XXX
 SG_ PfhmNAsCounter : 23|8@0+ (1,0) [0|255] "" Vector__XXX
 SG_ NerrFaultCounterValue : 15|8@0+ (1,0) [0|255] "" Vector__XXX
 SG_ Unused2 : 2|3@0+ (1,0) [0|7] "" Vector__XXX
 SG_ SupervisionTaskState : 3|1@0+ (1,0) [0|1] "" Vector__XXX
 SG_ NerrBitStatus : 4|1@0+ (1,0) [0|1] "" Vector__XXX
 SG_ ComLossFault : 5|1@0+ (1,0) [0|1] "" Vector__XXX
 SG_ Unused1 : 7|2@0+ (1,0) [0|3] "" Vector__XXX

BO_ 1292 CRT_Supervision: 8 CRT
 SG_ Unused4 : 63|8@0+ (1,0) [0|255] "" Vector__XXX
 SG_ Unused3 : 55|8@0+ (1,0) [0|255] "" Vector__XXX
 SG_ AbsentFmux1 : 47|8@0+ (1,0) [0|255] "" Vector__XXX
 SG_ PfhmComLossCounter : 39|8@0+ (1,0) [0|255] "" Vector__XXX
 SG_ PfhmBusOffCounter : 31|8@0+ (1,0) [0|255] "" Vector__XXX
 SG_ PfhmNAsCounter : 23|8@0+ (1,0) [0|255] "" Vector__XXX
 SG_ NerrFaultCounterValue : 15|8@0+ (1,0) [0|255] "" Vector__XXX
 SG_ Unused2 : 2|3@0+ (1,0) [0|7] "" Vector__XXX
 SG_ SupervisionTaskState : 3|1@0+ (1,0) [0|1] "" Vector__XXX
 SG_ NerrBitStatus : 4|1@0+ (1,0) [0|1] "" Vector__XXX
 SG_ ComLossFault : 5|1@0+ (1,0) [0|1] "" Vector__XXX
 SG_ Unused1 : 7|2@0+ (1,0) [0|3] "" Vector__XXX

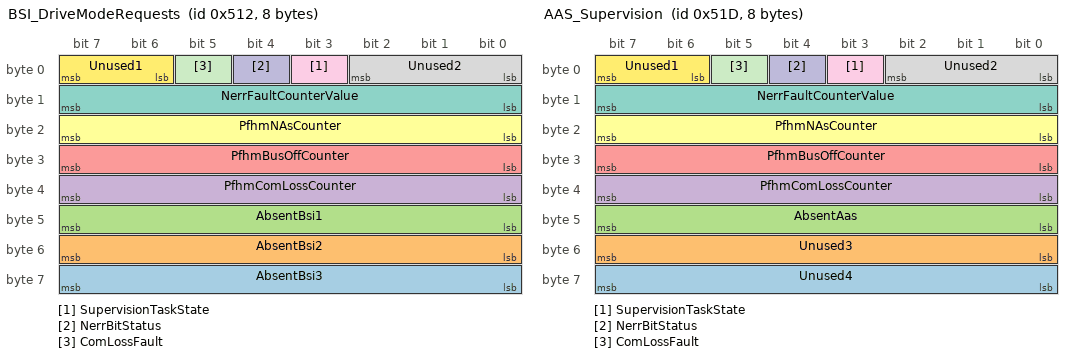
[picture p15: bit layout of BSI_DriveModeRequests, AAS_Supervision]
BO_ 1298 BSI_DriveModeRequests: 8 BSI
 SG_ AbsentBsi3 : 63|8@0+ (1,0) [0|255] "" Vector__XXX
 SG_ AbsentBsi2 : 55|8@0+ (1,0) [0|255] "" Vector__XXX
 SG_ AbsentBsi1 : 47|8@0+ (1,0) [0|255] "" Vector__XXX
 SG_ PfhmComLossCounter : 39|8@0+ (1,0) [0|255] "" Vector__XXX
 SG_ PfhmBusOffCounter : 31|8@0+ (1,0) [0|255] "" Vector__XXX
 SG_ PfhmNAsCounter : 23|8@0+ (1,0) [0|255] "" Vector__XXX
 SG_ NerrFaultCounterValue : 15|8@0+ (1,0) [0|255] "" Vector__XXX
 SG_ Unused2 : 2|3@0+ (1,0) [0|7] "" Vector__XXX
 SG_ SupervisionTaskState : 3|1@0+ (1,0) [0|1] "" Vector__XXX
 SG_ NerrBitStatus : 4|1@0+ (1,0) [0|1] "" Vector__XXX
 SG_ ComLossFault : 5|1@0+ (1,0) [0|1] "" Vector__XXX
 SG_ Unused1 : 7|2@0+ (1,0) [0|3] "" Vector__XXX

BO_ 1309 AAS_Supervision: 8 AAS
 SG_ Unused4 : 63|8@0+ (1,0) [0|255] "" Vector__XXX
 SG_ Unused3 : 55|8@0+ (1,0) [0|255] "" Vector__XXX
 SG_ AbsentAas : 47|8@0+ (1,0) [0|255] "" Vector__XXX
 SG_ PfhmComLossCounter : 39|8@0+ (1,0) [0|255] "" Vector__XXX
 SG_ PfhmBusOffCounter : 31|8@0+ (1,0) [0|255] "" Vector__XXX
 SG_ PfhmNAsCounter : 23|8@0+ (1,0) [0|255] "" Vector__XXX
 SG_ NerrFaultCounterValue : 15|8@0+ (1,0) [0|255] "" Vector__XXX
 SG_ Unused2 : 2|3@0+ (1,0) [0|7] "" Vector__XXX
 SG_ SupervisionTaskState : 3|1@0+ (1,0) [0|1] "" Vector__XXX
 SG_ NerrBitStatus : 4|1@0+ (1,0) [0|1] "" Vector__XXX
 SG_ ComLossFault : 5|1@0+ (1,0) [0|1] "" Vector__XXX
 SG_ Unused1 : 7|2@0+ (1,0) [0|3] "" Vector__XXX

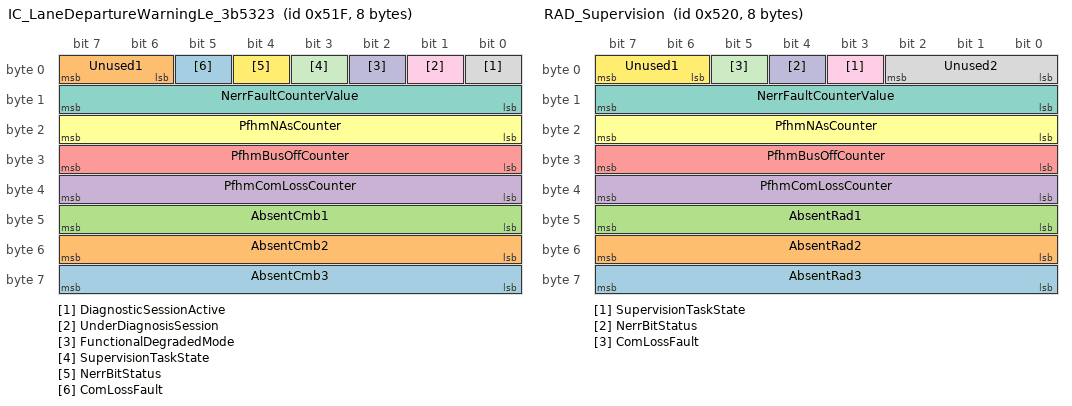
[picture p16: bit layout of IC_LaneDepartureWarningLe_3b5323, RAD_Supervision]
BO_ 1311 IC_LaneDepartureWarningLe_3b5323: 8 IC
 SG_ AbsentCmb3 : 63|8@0+ (1,0) [0|255] "" Vector__XXX
 SG_ AbsentCmb2 : 55|8@0+ (1,0) [0|255] "" Vector__XXX
 SG_ AbsentCmb1 : 47|8@0+ (1,0) [0|255] "" Vector__XXX
 SG_ PfhmComLossCounter : 39|8@0+ (1,0) [0|255] "" Vector__XXX
 SG_ PfhmBusOffCounter : 31|8@0+ (1,0) [0|255] "" Vector__XXX
 SG_ PfhmNAsCounter : 23|8@0+ (1,0) [0|255] "" Vector__XXX
 SG_ NerrFaultCounterValue : 15|8@0+ (1,0) [0|255] "" Vector__XXX
 SG_ DiagnosticSessionActive : 0|1@0+ (1,0) [0|1] "" Vector__XXX
 SG_ UnderDiagnosisSession : 1|1@0+ (1,0) [0|1] "" Vector__XXX
 SG_ FunctionalDegradedMode : 2|1@0+ (1,0) [0|1] "" Vector__XXX
 SG_ SupervisionTaskState : 3|1@0+ (1,0) [0|1] "" Vector__XXX
 SG_ NerrBitStatus : 4|1@0+ (1,0) [0|1] "" Vector__XXX
 SG_ ComLossFault : 5|1@0+ (1,0) [0|1] "" Vector__XXX
 SG_ Unused1 : 7|2@0+ (1,0) [0|3] "" Vector__XXX

BO_ 1312 RAD_Supervision: 8 RAD
 SG_ AbsentRad3 : 63|8@0+ (1,0) [0|255] "" Vector__XXX
 SG_ AbsentRad2 : 55|8@0+ (1,0) [0|255] "" Vector__XXX
 SG_ AbsentRad1 : 47|8@0+ (1,0) [0|255] "" Vector__XXX
 SG_ PfhmComLossCounter : 39|8@0+ (1,0) [0|255] "" Vector__XXX
 SG_ PfhmBusOffCounter : 31|8@0+ (1,0) [0|255] "" Vector__XXX
 SG_ PfhmNAsCounter : 23|8@0+ (1,0) [0|255] "" Vector__XXX
 SG_ NerrFaultCounterValue : 15|8@0+ (1,0) [0|255] "" Vector__XXX
 SG_ Unused2 : 2|3@0+ (1,0) [0|7] "" Vector__XXX
 SG_ SupervisionTaskState : 3|1@0+ (1,0) [0|1] "" Vector__XXX
 SG_ NerrBitStatus : 4|1@0+ (1,0) [0|1] "" Vector__XXX
 SG_ ComLossFault : 5|1@0+ (1,0) [0|1] "" Vector__XXX
 SG_ Unused1 : 7|2@0+ (1,0) [0|3] "" Vector__XXX

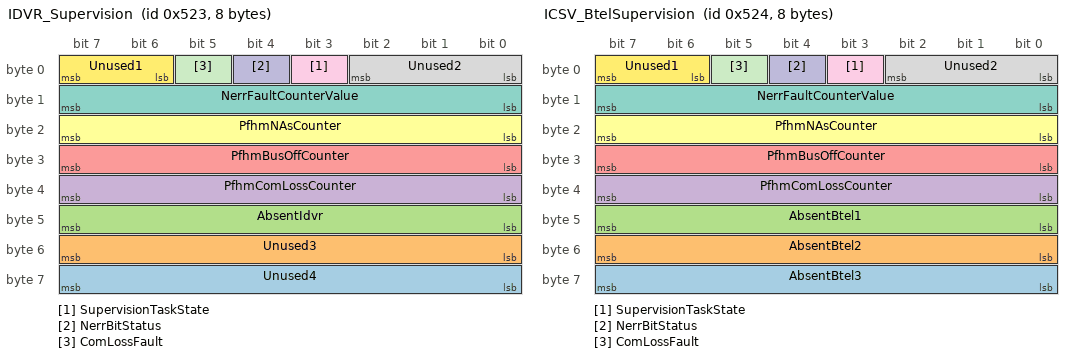
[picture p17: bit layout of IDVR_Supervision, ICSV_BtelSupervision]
BO_ 1315 IDVR_Supervision: 8 IDVR
 SG_ Unused4 : 63|8@0+ (1,0) [0|255] "" Vector__XXX
 SG_ Unused3 : 55|8@0+ (1,0) [0|255] "" Vector__XXX
 SG_ AbsentIdvr : 47|8@0+ (1,0) [0|255] "" Vector__XXX
 SG_ PfhmComLossCounter : 39|8@0+ (1,0) [0|255] "" Vector__XXX
 SG_ PfhmBusOffCounter : 31|8@0+ (1,0) [0|255] "" Vector__XXX
 SG_ PfhmNAsCounter : 23|8@0+ (1,0) [0|255] "" Vector__XXX
 SG_ NerrFaultCounterValue : 15|8@0+ (1,0) [0|255] "" Vector__XXX
 SG_ Unused2 : 2|3@0+ (1,0) [0|7] "" Vector__XXX
 SG_ SupervisionTaskState : 3|1@0+ (1,0) [0|1] "" Vector__XXX
 SG_ NerrBitStatus : 4|1@0+ (1,0) [0|1] "" Vector__XXX
 SG_ ComLossFault : 5|1@0+ (1,0) [0|1] "" Vector__XXX
 SG_ Unused1 : 7|2@0+ (1,0) [0|3] "" Vector__XXX

BO_ 1316 ICSV_BtelSupervision: 8 ICSV
 SG_ AbsentBtel3 : 63|8@0+ (1,0) [0|255] ""  BSI
 SG_ AbsentBtel2 : 55|8@0+ (1,0) [0|255] ""  BSI
 SG_ AbsentBtel1 : 47|8@0+ (1,0) [0|255] ""  BSI
 SG_ PfhmComLossCounter : 39|8@0+ (1,0) [0|255] ""  BSI
 SG_ PfhmBusOffCounter : 31|8@0+ (1,0) [0|255] ""  BSI
 SG_ PfhmNAsCounter : 23|8@0+ (1,0) [0|255] ""  BSI
 SG_ NerrFaultCounterValue : 15|8@0+ (1,0) [0|255] ""  BSI
 SG_ Unused2 : 2|3@0+ (1,0) [0|7] ""  BSI
 SG_ SupervisionTaskState : 3|1@0+ (1,0) [0|1] ""  BSI
 SG_ NerrBitStatus : 4|1@0+ (1,0) [0|1] ""  BSI
 SG_ ComLossFault : 5|1@0+ (1,0) [0|1] ""  BSI
 SG_ Unused1 : 7|2@0+ (1,0) [0|3] ""  BSI

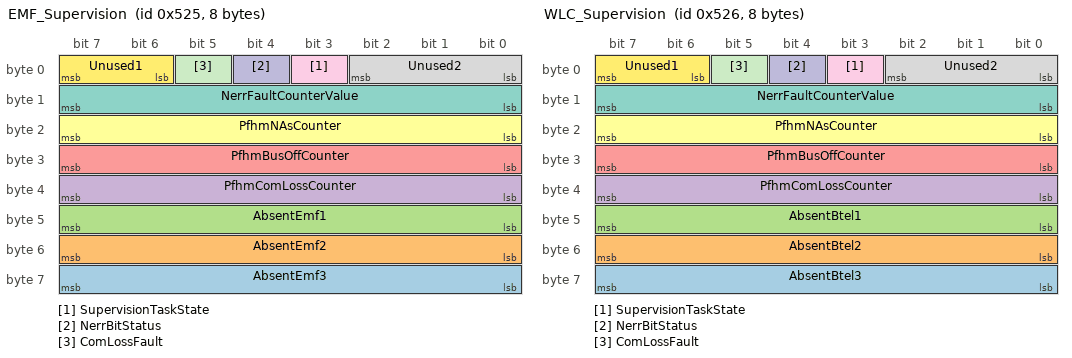
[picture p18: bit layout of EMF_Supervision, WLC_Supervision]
BO_ 1317 EMF_Supervision: 8 EMF
 SG_ AbsentEmf3 : 63|8@0+ (1,0) [0|255] "" Vector__XXX
 SG_ AbsentEmf2 : 55|8@0+ (1,0) [0|255] "" Vector__XXX
 SG_ AbsentEmf1 : 47|8@0+ (1,0) [0|255] "" Vector__XXX
 SG_ PfhmComLossCounter : 39|8@0+ (1,0) [0|255] "" Vector__XXX
 SG_ PfhmBusOffCounter : 31|8@0+ (1,0) [0|255] "" Vector__XXX
 SG_ PfhmNAsCounter : 23|8@0+ (1,0) [0|255] "" Vector__XXX
 SG_ NerrFaultCounterValue : 15|8@0+ (1,0) [0|255] "" Vector__XXX
 SG_ Unused2 : 2|3@0+ (1,0) [0|7] "" Vector__XXX
 SG_ SupervisionTaskState : 3|1@0+ (1,0) [0|1] "" Vector__XXX
 SG_ NerrBitStatus : 4|1@0+ (1,0) [0|1] "" Vector__XXX
 SG_ ComLossFault : 5|1@0+ (1,0) [0|1] "" Vector__XXX
 SG_ Unused1 : 7|2@0+ (1,0) [0|3] "" Vector__XXX

BO_ 1318 WLC_Supervision: 8 WLC
 SG_ AbsentBtel3 : 63|8@0+ (1,0) [0|255] "" Vector__XXX
 SG_ AbsentBtel2 : 55|8@0+ (1,0) [0|255] "" Vector__XXX
 SG_ AbsentBtel1 : 47|8@0+ (1,0) [0|255] "" Vector__XXX
 SG_ PfhmComLossCounter : 39|8@0+ (1,0) [0|255] "" Vector__XXX
 SG_ PfhmBusOffCounter : 31|8@0+ (1,0) [0|255] "" Vector__XXX
 SG_ PfhmNAsCounter : 23|8@0+ (1,0) [0|255] "" Vector__XXX
 SG_ NerrFaultCounterValue : 15|8@0+ (1,0) [0|255] "" Vector__XXX
 SG_ Unused2 : 2|3@0+ (1,0) [0|7] "" Vector__XXX
 SG_ SupervisionTaskState : 3|1@0+ (1,0) [0|1] "" Vector__XXX
 SG_ NerrBitStatus : 4|1@0+ (1,0) [0|1] "" Vector__XXX
 SG_ ComLossFault : 5|1@0+ (1,0) [0|1] "" Vector__XXX
 SG_ Unused1 : 7|2@0+ (1,0) [0|3] "" Vector__XXX

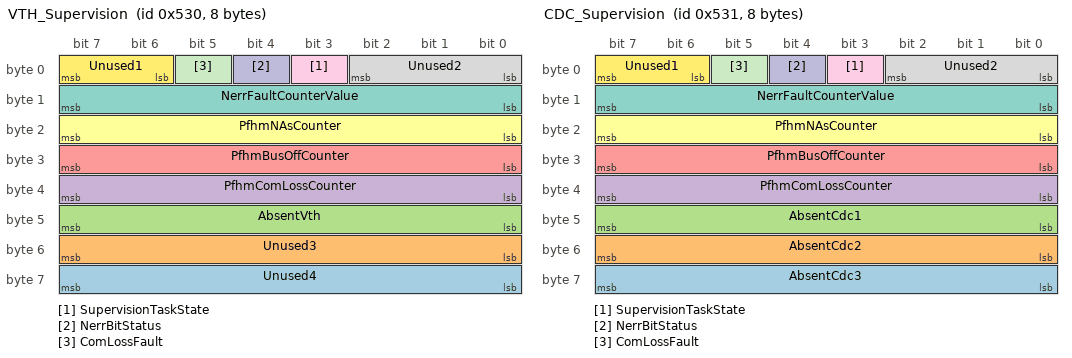
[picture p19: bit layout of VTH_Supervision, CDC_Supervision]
BO_ 1328 VTH_Supervision: 8 VTH
 SG_ Unused4 : 63|8@0+ (1,0) [0|255] "" Vector__XXX
 SG_ Unused3 : 55|8@0+ (1,0) [0|255] "" Vector__XXX
 SG_ AbsentVth : 47|8@0+ (1,0) [0|255] "" Vector__XXX
 SG_ PfhmComLossCounter : 39|8@0+ (1,0) [0|255] "" Vector__XXX
 SG_ PfhmBusOffCounter : 31|8@0+ (1,0) [0|255] "" Vector__XXX
 SG_ PfhmNAsCounter : 23|8@0+ (1,0) [0|255] "" Vector__XXX
 SG_ NerrFaultCounterValue : 15|8@0+ (1,0) [0|255] "" Vector__XXX
 SG_ Unused2 : 2|3@0+ (1,0) [0|7] "" Vector__XXX
 SG_ SupervisionTaskState : 3|1@0+ (1,0) [0|1] "" Vector__XXX
 SG_ NerrBitStatus : 4|1@0+ (1,0) [0|1] "" Vector__XXX
 SG_ ComLossFault : 5|1@0+ (1,0) [0|1] "" Vector__XXX
 SG_ Unused1 : 7|2@0+ (1,0) [0|3] "" Vector__XXX

BO_ 1329 CDC_Supervision: 8 CDC
 SG_ AbsentCdc3 : 63|8@0+ (1,0) [0|255] "" Vector__XXX
 SG_ AbsentCdc2 : 55|8@0+ (1,0) [0|255] "" Vector__XXX
 SG_ AbsentCdc1 : 47|8@0+ (1,0) [0|255] "" Vector__XXX
 SG_ PfhmComLossCounter : 39|8@0+ (1,0) [0|255] "" Vector__XXX
 SG_ PfhmBusOffCounter : 31|8@0+ (1,0) [0|255] "" Vector__XXX
 SG_ PfhmNAsCounter : 23|8@0+ (1,0) [0|255] "" Vector__XXX
 SG_ NerrFaultCounterValue : 15|8@0+ (1,0) [0|255] "" Vector__XXX
 SG_ Unused2 : 2|3@0+ (1,0) [0|7] "" Vector__XXX
 SG_ SupervisionTaskState : 3|1@0+ (1,0) [0|1] "" Vector__XXX
 SG_ NerrBitStatus : 4|1@0+ (1,0) [0|1] "" Vector__XXX
 SG_ ComLossFault : 5|1@0+ (1,0) [0|1] "" Vector__XXX
 SG_ Unused1 : 7|2@0+ (1,0) [0|3] "" Vector__XXX

BO_TX_BU_ 933 : RAD,ICSV;
BO_TX_BU_ 935 : ICSV,CMB;
BO_TX_BU_ 937 : MDS,ICSV;
BO_TX_BU_ 950 : BSI,ICSV;
BO_TX_BU_ 992 : ICSV,BSI;
BO_TX_BU_ 995 : RAD,ICSV;
BO_TX_BU_ 996 : RAD,ICSV;
BO_TX_BU_ 997 : ICSV,RAD;
BO_TX_BU_ 999 : ICSV,BSI;
BO_TX_BU_ 1001 : CMB,ICSV,MATT;
BO_TX_BU_ 1008 : ICSV,BSI;
BO_TX_BU_ 1009 : ICSV,BTEL,OVIP;
BO_TX_BU_ 1056 : RAD,ICSV;
BO_TX_BU_ 1060 : ICSV,BTEL,OVIP;
BO_TX_BU_ 1142 : BSI,ICSV;
BO_TX_BU_ 1184 : RAD,ICSV,BTEL;
BO_TX_BU_ 1188 : ICSV,BTEL,OVIP,CMB;
BO_TX_BU_ 1312 : RAD,ICSV,BTEL;
BO_TX_BU_ 1316 : ICSV,BTEL,OVIP;
CM_ BO_ 933 "DATABASE_CANDIDATE: physical interpretation unverified; capture/layout evidence reported separately. INFO-DIV CAN, 125000 bit/s; CAN ID 0x3A5. PSA-RE title: RADIO_TRACK_STATUS. Radio current track status: shuffle and repeat modes, text data availability, elapsed time, track number/total, change origin and source. Source: https://github.com/prototux/PSA-RE/blob/67f7581e7622410efdbb29c7eda3b86982b9b450/buses/AEE2010.full/LS.INFO-DIV/3A5.yml. Source sender alternatives: RAD,ICSV; physical TX/gateway forwarding not verified. ";
CM_ SG_ 933 Unused1 "DATABASE_CANDIDATE: physical interpretation unverified; capture/layout evidence reported separately. PSA-RE bits 8.3-8.0. ";
CM_ SG_ 933 CdPlaybackModeStatus "DATABASE_CANDIDATE: physical interpretation unverified; capture/layout evidence reported separately. PSA-RE bits 8.5-8.4. State of the mode of reading of CD (car radio) Upstream default raw=0 (not necessarily valid data).";
CM_ SG_ 933 RepeatModeStatus "DATABASE_CANDIDATE: physical interpretation unverified; capture/layout evidence reported separately. PSA-RE bits 8.7-8.6. Repetition soundtrack / compact disk (car audio) state Upstream default raw=0 (not necessarily valid data).";
CM_ SG_ 933 TrackCount "DATABASE_CANDIDATE: physical interpretation unverified; capture/layout evidence reported separately. PSA-RE bits 6.7-7.0. Number of tracks Raw invalid=65535; numeric DBC decoders may still scale it: check raw before use. Upstream default raw=65535 (not necessarily valid data).";
CM_ SG_ 933 TextDataAvailable "DATABASE_CANDIDATE: physical interpretation unverified; capture/layout evidence reported separately. PSA-RE bits 5.1-5.0. Text data available Upstream default raw=0 (not necessarily valid data).";
CM_ SG_ 933 SelectedListType "DATABASE_CANDIDATE: physical interpretation unverified; capture/layout evidence reported separately. PSA-RE bits 5.4-5.2. Type of the list currently played Upstream default raw=7 (not necessarily valid data).";
CM_ SG_ 933 Source "DATABASE_CANDIDATE: physical interpretation unverified; capture/layout evidence reported separately. PSA-RE bits 5.7-5.5. Source Upstream default raw=0 (not necessarily valid data).";
CM_ SG_ 933 FileElapsedSeconds "DATABASE_CANDIDATE: physical interpretation unverified; capture/layout evidence reported separately. PSA-RE bits 4.5-4.0. Seconds elapsed since the start of the file Raw invalid=63; numeric DBC decoders may still scale it: check raw before use. Upstream default raw=63 (not necessarily valid data).";
CM_ SG_ 933 TrackChangeOrigin "DATABASE_CANDIDATE: physical interpretation unverified; capture/layout evidence reported separately. PSA-RE bits 4.7-4.6. Origin of the change of track on audio CD Upstream default raw=0 (not necessarily valid data).";
CM_ SG_ 933 FileElapsedMinutes "DATABASE_CANDIDATE: physical interpretation unverified; capture/layout evidence reported separately. PSA-RE bits 3.7-3.0. Minutes elapsed since the start of the file Raw invalid=255; numeric DBC decoders may still scale it: check raw before use. Upstream default raw=255 (not necessarily valid data).";
CM_ SG_ 933 CurrentTrackNumber "DATABASE_CANDIDATE: physical interpretation unverified; capture/layout evidence reported separately. PSA-RE bits 1.7-2.0. Number of the track listened Raw invalid=65535; numeric DBC decoders may still scale it: check raw before use. Upstream default raw=65535 (not necessarily valid data).";
CM_ BO_ 935 "DATABASE_CANDIDATE: physical interpretation unverified; capture/layout evidence reported separately. INFO-DIV CAN, 125000 bit/s; CAN ID 0x3A7. PSA-RE title: DISPLAY_APPEARANCE_LIST. Display appearance/skin list data (part 2), relayed between the infotainment sources and the instrument cluster. Source: https://github.com/prototux/PSA-RE/blob/67f7581e7622410efdbb29c7eda3b86982b9b450/buses/AEE2010.full/LS.INFO-DIV/3A7.yml. Source sender alternatives: ICSV,CMB; physical TX/gateway forwarding not verified. ";
CM_ SG_ 935 StoredAppearanceId16 "DATABASE_CANDIDATE: physical interpretation unverified; capture/layout evidence reported separately. PSA-RE bits 8.7-8.0. Universal number of the stored appearance 16 Raw invalid=0; numeric DBC decoders may still scale it: check raw before use.";
CM_ SG_ 935 StoredAppearanceId15 "DATABASE_CANDIDATE: physical interpretation unverified; capture/layout evidence reported separately. PSA-RE bits 7.7-7.0. Universal number of the stored appearance 15 Raw invalid=0; numeric DBC decoders may still scale it: check raw before use.";
CM_ SG_ 935 StoredAppearanceId14 "DATABASE_CANDIDATE: physical interpretation unverified; capture/layout evidence reported separately. PSA-RE bits 6.7-6.0. Universal number of the stored appearance 14 Raw invalid=0; numeric DBC decoders may still scale it: check raw before use.";
CM_ SG_ 935 StoredAppearanceId13 "DATABASE_CANDIDATE: physical interpretation unverified; capture/layout evidence reported separately. PSA-RE bits 5.7-5.0. Universal number of the stored appearance 13 Raw invalid=0; numeric DBC decoders may still scale it: check raw before use.";
CM_ SG_ 935 StoredAppearanceId12 "DATABASE_CANDIDATE: physical interpretation unverified; capture/layout evidence reported separately. PSA-RE bits 4.7-4.0. Universal number of the stored appearance 12 Raw invalid=0; numeric DBC decoders may still scale it: check raw before use.";
CM_ SG_ 935 StoredAppearanceId11 "DATABASE_CANDIDATE: physical interpretation unverified; capture/layout evidence reported separately. PSA-RE bits 3.7-3.0. Universal number of the stored appearance 11 Raw invalid=0; numeric DBC decoders may still scale it: check raw before use.";
CM_ SG_ 935 StoredAppearanceId10 "DATABASE_CANDIDATE: physical interpretation unverified; capture/layout evidence reported separately. PSA-RE bits 2.7-2.0. Universal number of the stored appearance 10 Raw invalid=0; numeric DBC decoders may still scale it: check raw before use.";
CM_ SG_ 935 StoredAppearanceId9 "DATABASE_CANDIDATE: physical interpretation unverified; capture/layout evidence reported separately. PSA-RE bits 1.7-1.0. Universal number of the stored appearance 9 Raw invalid=0; numeric DBC decoders may still scale it: check raw before use.";
CM_ BO_ 936 "DATABASE_CANDIDATE: physical interpretation unverified; capture/layout evidence reported separately. INFO-DIV CAN, 125000 bit/s; CAN ID 0x3A8. PSA-RE title: ENGINE_ECU_DATA_2. Elapsed and stopped time, and zero-emission time percentage, for the current trip. Source: https://github.com/prototux/PSA-RE/blob/67f7581e7622410efdbb29c7eda3b86982b9b450/buses/AEE2010.full/LS.INFO-DIV/3A8.yml. Source sender alternatives: BSI; physical TX/gateway forwarding not verified. Observed 588 frames in info_apka.csv,info_buzeni_obc.csv,info_charging.csv,info_standby.csv,info_start_jizda.csv,infocan.csv; DLCs [8]. Unresolved alternative source layouts preserved in source JSON. ";
CM_ SG_ 936 Unused6 "DATABASE_CANDIDATE: physical interpretation unverified; capture/layout evidence reported separately. PSA-RE bits 8.0. ";
CM_ SG_ 936 ZevDurationPercentCurrent_6cc313 "DATABASE_CANDIDATE: physical interpretation unverified; capture/layout evidence reported separately. PSA-RE bits 8.7-8.1. Adjusted percentage of time spent in ZEV mode for the current trip Raw invalid=127; numeric DBC decoders may still scale it: check raw before use. Upstream default raw=0 (not necessarily valid data).";
CM_ SG_ 936 Unused5 "DATABASE_CANDIDATE: physical interpretation unverified; capture/layout evidence reported separately. PSA-RE bits 7.0. ";
CM_ SG_ 936 ZevDurationPercentCurrentTrip "DATABASE_CANDIDATE: physical interpretation unverified; capture/layout evidence reported separately. PSA-RE bits 7.7-7.1. Percentage of time spent in ZEV mode relative to total time of the current trip Raw invalid=127; numeric DBC decoders may still scale it: check raw before use. Upstream default raw=0 (not necessarily valid data).";
CM_ SG_ 936 Unused4 "DATABASE_CANDIDATE: physical interpretation unverified; capture/layout evidence reported separately. PSA-RE bits 6.0. ";
CM_ SG_ 936 ZevDurationSecondsCurrentTrip "DATABASE_CANDIDATE: physical interpretation unverified; capture/layout evidence reported separately. PSA-RE bits 6.6-6.1. Seconds component of the ZEV (engine-off) duration for the current trip Raw invalid=63; numeric DBC decoders may still scale it: check raw before use. Upstream default raw=0 (not necessarily valid data).";
CM_ SG_ 936 ZevDurationMinutesCurrentTrip "DATABASE_CANDIDATE: physical interpretation unverified; capture/layout evidence reported separately. PSA-RE bits 5.4-6.7. Minutes component of the ZEV (engine-off) duration for the current trip Raw invalid=63; numeric DBC decoders may still scale it: check raw before use. Upstream default raw=0 (not necessarily valid data).";
CM_ SG_ 936 ZevDurationHoursCurrentTrip "DATABASE_CANDIDATE: physical interpretation unverified; capture/layout evidence reported separately. PSA-RE bits 4.7-5.5. Hours component of the ZEV (engine-off) duration for the current trip Raw invalid=2047; numeric DBC decoders may still scale it: check raw before use. Upstream default raw=0 (not necessarily valid data).";
CM_ SG_ 936 Unused3 "DATABASE_CANDIDATE: physical interpretation unverified; capture/layout evidence reported separately. PSA-RE bits 3.1-3.0. ";
CM_ SG_ 936 TripDurationSecondsCurrent "DATABASE_CANDIDATE: physical interpretation unverified; capture/layout evidence reported separately. PSA-RE bits 3.7-3.2. Seconds component of the current trip duration Raw invalid=63; numeric DBC decoders may still scale it: check raw before use. Upstream default raw=0 (not necessarily valid data).";
CM_ SG_ 936 Unused2 "DATABASE_CANDIDATE: physical interpretation unverified; capture/layout evidence reported separately. PSA-RE bits 2.1-2.0. ";
CM_ SG_ 936 TripDurationMinutesCurrent "DATABASE_CANDIDATE: physical interpretation unverified; capture/layout evidence reported separately. PSA-RE bits 2.7-2.2. Minutes component of the current trip duration Raw invalid=63; numeric DBC decoders may still scale it: check raw before use. Upstream default raw=0 (not necessarily valid data).";
CM_ SG_ 936 Unused1 "DATABASE_CANDIDATE: physical interpretation unverified; capture/layout evidence reported separately. PSA-RE bits 1.1-1.0. ";
CM_ SG_ 936 TripDurationHoursCurrent "DATABASE_CANDIDATE: physical interpretation unverified; capture/layout evidence reported separately. PSA-RE bits 1.7-1.2. Hours component of the current trip duration Raw invalid=63; numeric DBC decoders may still scale it: check raw before use. Upstream default raw=0 (not necessarily valid data).";
CM_ BO_ 937 "DATABASE_CANDIDATE: physical interpretation unverified; capture/layout evidence reported separately. INFO-DIV CAN, 125000 bit/s; CAN ID 0x3A9. PSA-RE title: TELEMATICS_CALL_BUTTON_STATUS. Telematics unit status: breakdown/emergency call buttons, mute and hold state. Source: https://github.com/prototux/PSA-RE/blob/67f7581e7622410efdbb29c7eda3b86982b9b450/buses/AEE2010.full/LS.INFO-DIV/3A9.yml. Source sender alternatives: MDS,ICSV; physical TX/gateway forwarding not verified. Observed 2934 frames in info_apka.csv,info_buzeni_obc.csv,info_charging.csv,info_standby.csv,info_start_jizda.csv,infocan.csv; DLCs [2]. Unresolved alternative source layouts preserved in source JSON. ";
CM_ SG_ 937 Unused2 "DATABASE_CANDIDATE: physical interpretation unverified; capture/layout evidence reported separately. PSA-RE bits 2.7-2.0. ";
CM_ SG_ 937 EmergencyCallInProgress "DATABASE_CANDIDATE: physical interpretation unverified; capture/layout evidence reported separately. PSA-RE bits 1.0. Emergency call in progress Upstream default raw=0 (not necessarily valid data).";
CM_ SG_ 937 BreakdownCallInProgress "DATABASE_CANDIDATE: physical interpretation unverified; capture/layout evidence reported separately. PSA-RE bits 1.1. Breakdown assistance call in progress Upstream default raw=0 (not necessarily valid data).";
CM_ SG_ 937 NetworkMaintainRequestMdc "DATABASE_CANDIDATE: physical interpretation unverified; capture/layout evidence reported separately. PSA-RE bits 1.2. Network maintain request from the emergency call module (MDC) Upstream default raw=0 (not necessarily valid data).";
CM_ SG_ 937 SualMuteRequest "DATABASE_CANDIDATE: physical interpretation unverified; capture/layout evidence reported separately. PSA-RE bits 1.3. Mute request for the SUAL module Upstream default raw=0 (not necessarily valid data).";
CM_ SG_ 937 Unused1 "DATABASE_CANDIDATE: physical interpretation unverified; capture/layout evidence reported separately. PSA-RE bits 1.7-1.4. ";
CM_ BO_ 950 "DATABASE_CANDIDATE: physical interpretation unverified; capture/layout evidence reported separately. INFO-DIV CAN, 125000 bit/s; CAN ID 0x3B6. PSA-RE title: VIN_VDS. VIN = Vehicle Identification Number. VDS = Vehicle Description Section, VIN field describing the general characteristics of the vehicle. Source: https://github.com/prototux/PSA-RE/blob/67f7581e7622410efdbb29c7eda3b86982b9b450/buses/AEE2010.full/LS.INFO-DIV/3B6.yml. Source sender alternatives: BSI,ICSV; physical TX/gateway forwarding not verified. Observed 587 frames in info_apka.csv,info_buzeni_obc.csv,info_charging.csv,info_standby.csv,info_start_jizda.csv,infocan.csv; DLCs [6]. Unresolved alternative source layouts preserved in source JSON. ";
CM_ SG_ 950 VdsChar6 "DATABASE_CANDIDATE: physical interpretation unverified; capture/layout evidence reported separately. PSA-RE bits 6.7-6.0. Sixth VDS character. Source text/byte field exposed as raw integer; no string decoding. Upstream default raw=0 (not necessarily valid data).";
CM_ SG_ 950 VdsChar5 "DATABASE_CANDIDATE: physical interpretation unverified; capture/layout evidence reported separately. PSA-RE bits 5.7-5.0. Fifth VDS character. Source text/byte field exposed as raw integer; no string decoding. Upstream default raw=0 (not necessarily valid data).";
CM_ SG_ 950 VdsChar4 "DATABASE_CANDIDATE: physical interpretation unverified; capture/layout evidence reported separately. PSA-RE bits 4.7-4.0. Fourth VDS character. Source text/byte field exposed as raw integer; no string decoding. Upstream default raw=0 (not necessarily valid data).";
CM_ SG_ 950 VdsChar3 "DATABASE_CANDIDATE: physical interpretation unverified; capture/layout evidence reported separately. PSA-RE bits 3.7-3.0. Third VDS character. Source text/byte field exposed as raw integer; no string decoding. Upstream default raw=0 (not necessarily valid data).";
CM_ SG_ 950 VdsChar2 "DATABASE_CANDIDATE: physical interpretation unverified; capture/layout evidence reported separately. PSA-RE bits 2.7-2.0. Second VDS character. Source text/byte field exposed as raw integer; no string decoding. Upstream default raw=0 (not necessarily valid data).";
CM_ SG_ 950 VdsChar1 "DATABASE_CANDIDATE: physical interpretation unverified; capture/layout evidence reported separately. PSA-RE bits 1.7-1.0. First VDS character. Source text/byte field exposed as raw integer; no string decoding. Upstream default raw=0 (not necessarily valid data).";
CM_ BO_ 961 "DATABASE_CANDIDATE: physical interpretation unverified; capture/layout evidence reported separately. INFO-DIV CAN, 125000 bit/s; CAN ID 0x3C1. PSA-RE title: WIRELESS_CHARGER_RX_FLOW_CONTROL. ISO-TP flow control frame for the wireless charger's multi-frame transfer. Source: https://github.com/prototux/PSA-RE/blob/67f7581e7622410efdbb29c7eda3b86982b9b450/buses/AEE2010.full/LS.INFO-DIV/3C1.yml. Source sender alternatives: SDCM; physical TX/gateway forwarding not verified. WIRE ISO-TP ONLY: normal addressing candidate, maximum Classical CAN DLC 8; actual DLC may be shorter. Data includes padding. No reassembly, text, DID or application-layer decoding. Original application layouts are preserved in source JSON; do not decode them at wire offsets. ";
CM_ SG_ 961 FlowPadding5 "TRANSPORT_CANDIDATE: normal-addressing ISO-TP. PSA-RE bits 8.7-8.0. ";
CM_ SG_ 961 FirstData6 "TRANSPORT_CANDIDATE: normal-addressing ISO-TP. PSA-RE bits 8.7-8.0. ";
CM_ SG_ 961 UnknownData7 "TRANSPORT_CANDIDATE: normal-addressing ISO-TP. PSA-RE bits 8.7-8.0. ";
CM_ SG_ 961 ConsecutiveData7 "TRANSPORT_CANDIDATE: normal-addressing ISO-TP. PSA-RE bits 8.7-8.0. ";
CM_ SG_ 961 SingleData7 "TRANSPORT_CANDIDATE: normal-addressing ISO-TP. PSA-RE bits 8.7-8.0. ";
CM_ SG_ 961 FlowPadding4 "TRANSPORT_CANDIDATE: normal-addressing ISO-TP. PSA-RE bits 7.7-7.0. ";
CM_ SG_ 961 FirstData5 "TRANSPORT_CANDIDATE: normal-addressing ISO-TP. PSA-RE bits 7.7-7.0. ";
CM_ SG_ 961 UnknownData6 "TRANSPORT_CANDIDATE: normal-addressing ISO-TP. PSA-RE bits 7.7-7.0. ";
CM_ SG_ 961 ConsecutiveData6 "TRANSPORT_CANDIDATE: normal-addressing ISO-TP. PSA-RE bits 7.7-7.0. ";
CM_ SG_ 961 SingleData6 "TRANSPORT_CANDIDATE: normal-addressing ISO-TP. PSA-RE bits 7.7-7.0. ";
CM_ SG_ 961 FlowPadding3 "TRANSPORT_CANDIDATE: normal-addressing ISO-TP. PSA-RE bits 6.7-6.0. ";
CM_ SG_ 961 FirstData4 "TRANSPORT_CANDIDATE: normal-addressing ISO-TP. PSA-RE bits 6.7-6.0. ";
CM_ SG_ 961 UnknownData5 "TRANSPORT_CANDIDATE: normal-addressing ISO-TP. PSA-RE bits 6.7-6.0. ";
CM_ SG_ 961 ConsecutiveData5 "TRANSPORT_CANDIDATE: normal-addressing ISO-TP. PSA-RE bits 6.7-6.0. ";
CM_ SG_ 961 SingleData5 "TRANSPORT_CANDIDATE: normal-addressing ISO-TP. PSA-RE bits 6.7-6.0. ";
CM_ SG_ 961 FlowPadding2 "TRANSPORT_CANDIDATE: normal-addressing ISO-TP. PSA-RE bits 5.7-5.0. ";
CM_ SG_ 961 FirstData3 "TRANSPORT_CANDIDATE: normal-addressing ISO-TP. PSA-RE bits 5.7-5.0. ";
CM_ SG_ 961 UnknownData4 "TRANSPORT_CANDIDATE: normal-addressing ISO-TP. PSA-RE bits 5.7-5.0. ";
CM_ SG_ 961 ConsecutiveData4 "TRANSPORT_CANDIDATE: normal-addressing ISO-TP. PSA-RE bits 5.7-5.0. ";
CM_ SG_ 961 SingleData4 "TRANSPORT_CANDIDATE: normal-addressing ISO-TP. PSA-RE bits 5.7-5.0. ";
CM_ SG_ 961 FlowPadding1 "TRANSPORT_CANDIDATE: normal-addressing ISO-TP. PSA-RE bits 4.7-4.0. ";
CM_ SG_ 961 FirstData2 "TRANSPORT_CANDIDATE: normal-addressing ISO-TP. PSA-RE bits 4.7-4.0. ";
CM_ SG_ 961 UnknownData3 "TRANSPORT_CANDIDATE: normal-addressing ISO-TP. PSA-RE bits 4.7-4.0. ";
CM_ SG_ 961 ConsecutiveData3 "TRANSPORT_CANDIDATE: normal-addressing ISO-TP. PSA-RE bits 4.7-4.0. ";
CM_ SG_ 961 SingleData3 "TRANSPORT_CANDIDATE: normal-addressing ISO-TP. PSA-RE bits 4.7-4.0. ";
CM_ SG_ 961 FirstData1 "TRANSPORT_CANDIDATE: normal-addressing ISO-TP. PSA-RE bits 3.7-3.0. ";
CM_ SG_ 961 UnknownData2 "TRANSPORT_CANDIDATE: normal-addressing ISO-TP. PSA-RE bits 3.7-3.0. ";
CM_ SG_ 961 ConsecutiveData2 "TRANSPORT_CANDIDATE: normal-addressing ISO-TP. PSA-RE bits 3.7-3.0. ";
CM_ SG_ 961 SingleData2 "TRANSPORT_CANDIDATE: normal-addressing ISO-TP. PSA-RE bits 3.7-3.0. ";
CM_ SG_ 961 SeparationTimeRaw "TRANSPORT_CANDIDATE: normal-addressing ISO-TP. PSA-RE bits 3.7-3.0. Raw STmin code; 0xF1..0xF9 are not milliseconds.";
CM_ SG_ 961 UnknownData1 "TRANSPORT_CANDIDATE: normal-addressing ISO-TP. PSA-RE bits 2.7-2.0. ";
CM_ SG_ 961 ConsecutiveData1 "TRANSPORT_CANDIDATE: normal-addressing ISO-TP. PSA-RE bits 2.7-2.0. ";
CM_ SG_ 961 SingleData1 "TRANSPORT_CANDIDATE: normal-addressing ISO-TP. PSA-RE bits 2.7-2.0. ";
CM_ SG_ 961 BlockSize "TRANSPORT_CANDIDATE: normal-addressing ISO-TP. PSA-RE bits 2.7-2.0. ";
CM_ SG_ 961 UnknownPciLow "TRANSPORT_CANDIDATE: normal-addressing ISO-TP. PSA-RE bits 1.3-1.0. ";
CM_ SG_ 961 FlowStatus "TRANSPORT_CANDIDATE: normal-addressing ISO-TP. PSA-RE bits 1.3-1.0. ";
CM_ SG_ 961 ConsecutiveSequence "TRANSPORT_CANDIDATE: normal-addressing ISO-TP. PSA-RE bits 1.3-1.0. ";
CM_ SG_ 961 FirstFrameLength "TRANSPORT_CANDIDATE: normal-addressing ISO-TP. PSA-RE bits 1.3-2.0. 12-bit declared PDU length; not a reassembled value.";
CM_ SG_ 961 SingleFrameLength "TRANSPORT_CANDIDATE: normal-addressing ISO-TP. PSA-RE bits 1.3-1.0. Declared data length; not a validity check.";
CM_ SG_ 961 IsoTpFrameType "TRANSPORT_CANDIDATE: normal-addressing ISO-TP. PSA-RE bits 1.7-1.4. PCI high nibble; normal addressing candidate.";
CM_ BO_ 965 "DATABASE_CANDIDATE: physical interpretation unverified; capture/layout evidence reported separately. INFO-DIV CAN, 125000 bit/s; CAN ID 0x3C5. PSA-RE title: DASHCAM_STATE. Dashcam operating state: recording in progress, list available, playback state and memory usage. Source: https://github.com/prototux/PSA-RE/blob/67f7581e7622410efdbb29c7eda3b86982b9b450/buses/AEE2010.full/LS.INFO-DIV/3C5.yml. Source sender alternatives: IDVR; physical TX/gateway forwarding not verified. ";
CM_ SG_ 965 Unused1 "DATABASE_CANDIDATE: physical interpretation unverified; capture/layout evidence reported separately. PSA-RE bits 3.2-3.0. ";
CM_ SG_ 965 IdvrListAvailability "DATABASE_CANDIDATE: physical interpretation unverified; capture/layout evidence reported separately. PSA-RE bits 3.3. Availability state of the list Upstream default raw=0 (not necessarily valid data).";
CM_ SG_ 965 IdvrListAcceptanceState "DATABASE_CANDIDATE: physical interpretation unverified; capture/layout evidence reported separately. PSA-RE bits 3.5-3.4. State of list acceptance Upstream default raw=0 (not necessarily valid data).";
CM_ SG_ 965 AutoAccidentRecordingState "DATABASE_CANDIDATE: physical interpretation unverified; capture/layout evidence reported separately. PSA-RE bits 3.6. State of the automatic accident recording Upstream default raw=0 (not necessarily valid data).";
CM_ SG_ 965 DrivingRecordingMenuState "DATABASE_CANDIDATE: physical interpretation unverified; capture/layout evidence reported separately. PSA-RE bits 3.7. State of the driving recording in the settings menu Upstream default raw=0 (not necessarily valid data).";
CM_ SG_ 965 AccidentRecordingInProgress "DATABASE_CANDIDATE: physical interpretation unverified; capture/layout evidence reported separately. PSA-RE bits 2.0. Accident video recording in progress Upstream default raw=0 (not necessarily valid data).";
CM_ SG_ 965 AccidentMemoryUsagePercent "DATABASE_CANDIDATE: physical interpretation unverified; capture/layout evidence reported separately. PSA-RE bits 2.7-2.1. Percentage of memory used by accident video Raw invalid=127; numeric DBC decoders may still scale it: check raw before use. Upstream default raw=0 (not necessarily valid data).";
CM_ SG_ 965 IdvrPlaybackState "DATABASE_CANDIDATE: physical interpretation unverified; capture/layout evidence reported separately. PSA-RE bits 1.3-1.0. State of the playing video Upstream default raw=0 (not necessarily valid data).";
CM_ SG_ 965 IdvrState "DATABASE_CANDIDATE: physical interpretation unverified; capture/layout evidence reported separately. PSA-RE bits 1.6-1.4. State of the IDVR Upstream default raw=0 (not necessarily valid data).";
CM_ SG_ 965 IdvrRecording "DATABASE_CANDIDATE: physical interpretation unverified; capture/layout evidence reported separately. PSA-RE bits 1.7. IDVR is recording video Upstream default raw=0 (not necessarily valid data).";
CM_ BO_ 976 "DATABASE_CANDIDATE: physical interpretation unverified; capture/layout evidence reported separately. INFO-DIV CAN, 125000 bit/s; CAN ID 0x3D0. PSA-RE title: REAR_AIR_CONDITIONING_STATUS. Rear air conditioning display status: fault, air distribution, off mode and blower speed. Source: https://github.com/prototux/PSA-RE/blob/67f7581e7622410efdbb29c7eda3b86982b9b450/buses/AEE2010.full/LS.INFO-DIV/3D0.yml. Source sender alternatives: FMUX; physical TX/gateway forwarding not verified. ";
CM_ SG_ 976 RearLeftSeatVentilationRequest "DATABASE_CANDIDATE: physical interpretation unverified; capture/layout evidence reported separately. PSA-RE bits 6.1-6.0. Rear left seat ventilation level requested by the user Upstream default raw=0 (not necessarily valid data).";
CM_ SG_ 976 RearRightSeatVentilationRequest "DATABASE_CANDIDATE: physical interpretation unverified; capture/layout evidence reported separately. PSA-RE bits 6.3-6.2. Rear right seat ventilation level requested by the user Upstream default raw=0 (not necessarily valid data).";
CM_ SG_ 976 RearLeftSeatHeatingRequest "DATABASE_CANDIDATE: physical interpretation unverified; capture/layout evidence reported separately. PSA-RE bits 6.5-6.4. Rear left seat heating level requested by the user Upstream default raw=0 (not necessarily valid data).";
CM_ SG_ 976 RearRightSeatHeatingRequest "DATABASE_CANDIDATE: physical interpretation unverified; capture/layout evidence reported separately. PSA-RE bits 6.7-6.6. Rear right seat heating level requested by the user Upstream default raw=0 (not necessarily valid data).";
CM_ SG_ 976 RearRightDistribution "DATABASE_CANDIDATE: physical interpretation unverified; capture/layout evidence reported separately. PSA-RE bits 5.3-5.0. Rear right air distribution mode Upstream default raw=2 (not necessarily valid data).";
CM_ SG_ 976 RearLeftDistribution "DATABASE_CANDIDATE: physical interpretation unverified; capture/layout evidence reported separately. PSA-RE bits 5.7-5.4. Rear left air distribution mode Upstream default raw=2 (not necessarily valid data).";
CM_ SG_ 976 RearClimateFunctionStatus "DATABASE_CANDIDATE: physical interpretation unverified; capture/layout evidence reported separately. PSA-RE bits 4.1-4.0. Rear climate function status (on, auto locked, off, invalid) Upstream default raw=0 (not necessarily valid data).";
CM_ SG_ 976 RearLeftUpdateBit "DATABASE_CANDIDATE: physical interpretation unverified; capture/layout evidence reported separately. PSA-RE bits 4.2. Update flag for the rear left seat climate setpoints Upstream default raw=0 (not necessarily valid data).";
CM_ SG_ 976 RearRightUpdateBit "DATABASE_CANDIDATE: physical interpretation unverified; capture/layout evidence reported separately. PSA-RE bits 4.3. Update flag for the rear right seat climate setpoints Upstream default raw=0 (not necessarily valid data).";
CM_ SG_ 976 Unused3 "DATABASE_CANDIDATE: physical interpretation unverified; capture/layout evidence reported separately. PSA-RE bits 4.7-4.4. ";
CM_ SG_ 976 RearRightTempSetpoint "DATABASE_CANDIDATE: physical interpretation unverified; capture/layout evidence reported separately. PSA-RE bits 3.4-3.0. Rear right temperature setpoint value Upstream default raw=11 (not necessarily valid data).";
CM_ SG_ 976 Unused2 "DATABASE_CANDIDATE: physical interpretation unverified; capture/layout evidence reported separately. PSA-RE bits 3.7-3.5. ";
CM_ SG_ 976 RearLeftTempSetpoint "DATABASE_CANDIDATE: physical interpretation unverified; capture/layout evidence reported separately. PSA-RE bits 2.4-2.0. Rear left temperature setpoint value Upstream default raw=11 (not necessarily valid data).";
CM_ SG_ 976 Unused1 "DATABASE_CANDIDATE: physical interpretation unverified; capture/layout evidence reported separately. PSA-RE bits 2.7-2.5. ";
CM_ SG_ 976 RearRightBlowerSpeed "DATABASE_CANDIDATE: physical interpretation unverified; capture/layout evidence reported separately. PSA-RE bits 1.3-1.0. Display status: rear right blower manual speed Upstream default raw=1 (not necessarily valid data).";
CM_ SG_ 976 RearLeftBlowerSpeed "DATABASE_CANDIDATE: physical interpretation unverified; capture/layout evidence reported separately. PSA-RE bits 1.7-1.4. Display status: rear left blower manual speed Upstream default raw=1 (not necessarily valid data).";
CM_ BO_ 982 "DATABASE_CANDIDATE: physical interpretation unverified; capture/layout evidence reported separately. INFO-DIV CAN, 125000 bit/s; CAN ID 0x3D6. PSA-RE title: TELEDIAGNOSIS_REQUEST. Remote-diagnosis function request. Source: https://github.com/prototux/PSA-RE/blob/67f7581e7622410efdbb29c7eda3b86982b9b450/buses/AEE2010.full/LS.INFO-DIV/3D6.yml. Source sender alternatives: MDS; physical TX/gateway forwarding not verified. Observed 586 frames in info_apka.csv,info_buzeni_obc.csv,info_charging.csv,info_standby.csv,info_start_jizda.csv,infocan.csv; DLCs [1]. Unresolved alternative source layouts preserved in source JSON. ";
CM_ SG_ 982 Unused1 "DATABASE_CANDIDATE: physical interpretation unverified; capture/layout evidence reported separately. PSA-RE bits 1.5-1.0. ";
CM_ SG_ 982 TldiagFunctionRequest "DATABASE_CANDIDATE: physical interpretation unverified; capture/layout evidence reported separately. PSA-RE bits 1.7-1.6. TLDIAG (remote diagnosis) function request Upstream default raw=0 (not necessarily valid data).";
CM_ BO_ 986 "DATABASE_CANDIDATE: physical interpretation unverified; capture/layout evidence reported separately. INFO-DIV CAN, 125000 bit/s; CAN ID 0x3DA. PSA-RE title: ZEV_TRIP_INFO_3. Trip distance and duration for zero-emission driving, plus extended remaining charge time. Source: https://github.com/prototux/PSA-RE/blob/67f7581e7622410efdbb29c7eda3b86982b9b450/buses/AEE2010.full/LS.INFO-DIV/3DA.yml. Source sender alternatives: BSI; physical TX/gateway forwarding not verified. Observed 587 frames in info_apka.csv,info_buzeni_obc.csv,info_charging.csv,info_standby.csv,info_start_jizda.csv,infocan.csv; DLCs [6]. SOURCE_DLC_MISMATCH: source 4, observed/exported 6. Fitting fields retained; additional bytes raw. ";
CM_ SG_ 986 RawByte6 "RAW. PSA-RE bits 6.7-6.0. Unmapped/padding bits, no physical interpretation.";
CM_ SG_ 986 RawByte5 "RAW. PSA-RE bits 5.7-5.0. Unmapped/padding bits, no physical interpretation.";
CM_ SG_ 986 RawBits29_31 "RAW. PSA-RE bits 4.2-4.0. Unmapped/padding bits, no physical interpretation.";
CM_ SG_ 986 TripDistanceCounter "DATABASE_CANDIDATE: physical interpretation unverified; capture/layout evidence reported separately. PSA-RE bits 3.7-4.3. Distance counter for the trip Raw invalid=8191; numeric DBC decoders may still scale it: check raw before use.";
CM_ SG_ 986 TripTimeCounter "DATABASE_CANDIDATE: physical interpretation unverified; capture/layout evidence reported separately. PSA-RE bits 1.7-2.0. Time counter of the trip";
CM_ BO_ 992 "DATABASE_CANDIDATE: physical interpretation unverified; capture/layout evidence reported separately. INFO-DIV CAN, 125000 bit/s; CAN ID 0x3E0. PSA-RE title: HYBRID_INFO. Hybrid battery state of charge and cumulative electric-driving time counters. Source: https://github.com/prototux/PSA-RE/blob/67f7581e7622410efdbb29c7eda3b86982b9b450/buses/AEE2010.full/LS.INFO-DIV/3E0.yml. Source sender alternatives: ICSV,BSI; physical TX/gateway forwarding not verified. Observed 587 frames in info_apka.csv,info_buzeni_obc.csv,info_charging.csv,info_standby.csv,info_start_jizda.csv,infocan.csv; DLCs [8]. ";
CM_ SG_ 992 EcoTime "DATABASE_CANDIDATE: physical interpretation unverified; capture/layout evidence reported separately. PSA-RE bits 8.7-8.0. ECO time Raw invalid=127; numeric DBC decoders may still scale it: check raw before use. Upstream default raw=0 (not necessarily valid data).";
CM_ SG_ 992 AverageFuelConsumption6 "DATABASE_CANDIDATE: physical interpretation unverified; capture/layout evidence reported separately. PSA-RE bits 7.7-7.0. Average fuel consumption, memory 6 Raw invalid=255; numeric DBC decoders may still scale it: check raw before use. Upstream default raw=0 (not necessarily valid data). Unresolved source alternatives: [{\"note\": \"Also observed with another scaling (factor 1)\", \"factor\": 1}]";
CM_ SG_ 992 AverageFuelConsumption5 "DATABASE_CANDIDATE: physical interpretation unverified; capture/layout evidence reported separately. PSA-RE bits 6.7-6.0. Average fuel consumption, memory 5 Raw invalid=255; numeric DBC decoders may still scale it: check raw before use. Upstream default raw=0 (not necessarily valid data). Unresolved source alternatives: [{\"note\": \"Also observed with another scaling (factor 1)\", \"factor\": 1}]";
CM_ SG_ 992 AverageFuelConsumption4 "DATABASE_CANDIDATE: physical interpretation unverified; capture/layout evidence reported separately. PSA-RE bits 5.7-5.0. Average fuel consumption, memory 4 Raw invalid=255; numeric DBC decoders may still scale it: check raw before use. Upstream default raw=0 (not necessarily valid data). Unresolved source alternatives: [{\"note\": \"Also observed with another scaling (factor 1)\", \"factor\": 1}]";
CM_ SG_ 992 AverageFuelConsumption3 "DATABASE_CANDIDATE: physical interpretation unverified; capture/layout evidence reported separately. PSA-RE bits 4.7-4.0. Average fuel consumption, memory 3 Raw invalid=255; numeric DBC decoders may still scale it: check raw before use. Upstream default raw=0 (not necessarily valid data). Unresolved source alternatives: [{\"note\": \"Also observed with another scaling (factor 1)\", \"factor\": 1}]";
CM_ SG_ 992 AverageFuelConsumption2 "DATABASE_CANDIDATE: physical interpretation unverified; capture/layout evidence reported separately. PSA-RE bits 3.7-3.0. Average fuel consumption, memory 2 Raw invalid=255; numeric DBC decoders may still scale it: check raw before use. Upstream default raw=0 (not necessarily valid data). Unresolved source alternatives: [{\"note\": \"Also observed with another scaling (factor 1)\", \"factor\": 1}]";
CM_ SG_ 992 AverageFuelConsumption1 "DATABASE_CANDIDATE: physical interpretation unverified; capture/layout evidence reported separately. PSA-RE bits 2.7-2.0. Average fuel consumption, memory 1 Raw invalid=255; numeric DBC decoders may still scale it: check raw before use. Upstream default raw=0 (not necessarily valid data). Unresolved source alternatives: [{\"note\": \"Also observed with another scaling (factor 1)\", \"factor\": 1}]";
CM_ SG_ 992 BatterySocCandidate "DATABASE_CANDIDATE: physical interpretation unverified; capture/layout evidence reported separately. PSA-RE bits 1.7-1.0. Battery state of charge Raw invalid=127; numeric DBC decoders may still scale it: check raw before use. Upstream default raw=0 (not necessarily valid data). Candidate direct percent in byte 0; see per-capture values and research notes. A constant operating point alone does not validate rounding, freshness or the full scale.";
CM_ BO_ 993 "VEHICLE_LAYOUT_UNKNOWN: No validated Corsa-e charging interpretation: all376 samples in info_charging.csv are 00 00 00 80 00 00 00 while the owner confirms continuous AC charging before the final delayed-mode request. Upstream CHARGE_STATUS stays0; it cannot be used to report external charging. Preserve raw bytes until an EV layout is established. Raw bytes only; original interpretation retained in source JSON. INFO-DIV CAN, 125000 bit/s; CAN ID 0x3E1. PSA-RE title: HYBRID_START_STOP_INFO. Hybrid stop&start information: elapsed stop time, zero-emission request, engine/electric-machine state and recharge status. Source: https://github.com/prototux/PSA-RE/blob/67f7581e7622410efdbb29c7eda3b86982b9b450/buses/AEE2010.full/LS.INFO-DIV/3E1.yml. Source sender alternatives: BSI; physical TX/gateway forwarding not verified. Observed 749 frames in info_apka.csv,info_buzeni_obc.csv,info_charging.csv,info_standby.csv,info_start_jizda.csv,infocan.csv; DLCs [7]. ";
CM_ SG_ 993 RawByte7 "RAW. PSA-RE bits 7.7-7.0. Unmapped/padding bits, no physical interpretation.";
CM_ SG_ 993 RawByte6 "RAW. PSA-RE bits 6.7-6.0. Unmapped/padding bits, no physical interpretation.";
CM_ SG_ 993 RawByte5 "RAW. PSA-RE bits 5.7-5.0. Unmapped/padding bits, no physical interpretation.";
CM_ SG_ 993 RawByte4 "RAW. PSA-RE bits 4.7-4.0. Unmapped/padding bits, no physical interpretation.";
CM_ SG_ 993 RawByte3 "RAW. PSA-RE bits 3.7-3.0. Unmapped/padding bits, no physical interpretation.";
CM_ SG_ 993 RawByte2 "RAW. PSA-RE bits 2.7-2.0. Unmapped/padding bits, no physical interpretation.";
CM_ SG_ 993 RawByte1 "RAW. PSA-RE bits 1.7-1.0. Unmapped/padding bits, no physical interpretation.";
CM_ BO_ 994 "DATABASE_CANDIDATE: physical interpretation unverified; capture/layout evidence reported separately. INFO-DIV CAN, 125000 bit/s; CAN ID 0x3E2. PSA-RE title: AMPLIFIER_STATUS. Amplifier status: dynamic audio mode. Source: https://github.com/prototux/PSA-RE/blob/67f7581e7622410efdbb29c7eda3b86982b9b450/buses/AEE2010.full/LS.INFO-DIV/3E2.yml. Source sender alternatives: AMPLI; physical TX/gateway forwarding not verified. Unresolved alternative source layouts preserved in source JSON. ";
CM_ SG_ 994 Unused1 "DATABASE_CANDIDATE: physical interpretation unverified; capture/layout evidence reported separately. PSA-RE bits 1.5-2.0. ";
CM_ SG_ 994 AudioDynamicModeStatus "DATABASE_CANDIDATE: physical interpretation unverified; capture/layout evidence reported separately. PSA-RE bits 1.7-1.6. Audio state for engine sound enhancement activation Upstream default raw=3 (not necessarily valid data).";
CM_ BO_ 995 "DATABASE_CANDIDATE: physical interpretation unverified; capture/layout evidence reported separately. INFO-DIV CAN, 125000 bit/s; CAN ID 0x3E3. PSA-RE title: PHONE_STATUS_ACK. Acknowledgement of a multi-frame telephone status message sent to the display. Source: https://github.com/prototux/PSA-RE/blob/67f7581e7622410efdbb29c7eda3b86982b9b450/buses/AEE2010.full/LS.INFO-DIV/3E3.yml. Source sender alternatives: RAD,ICSV; physical TX/gateway forwarding not verified. ";
CM_ SG_ 995 SegmentationAckStream "DATABASE_CANDIDATE: physical interpretation unverified; capture/layout evidence reported separately. PSA-RE bits 1.7-1.0. Segmentation acknowledgment stream";
CM_ BO_ 996 "DATABASE_CANDIDATE: physical interpretation unverified; capture/layout evidence reported separately. INFO-DIV CAN, 125000 bit/s; CAN ID 0x3E4. PSA-RE title: USB_UPDATE_STATUS. USB firmware update status: update state, version number and progress. Source: https://github.com/prototux/PSA-RE/blob/67f7581e7622410efdbb29c7eda3b86982b9b450/buses/AEE2010.full/LS.INFO-DIV/3E4.yml. Source sender alternatives: RAD,ICSV; physical TX/gateway forwarding not verified. WIRE ISO-TP ONLY: normal addressing candidate, maximum Classical CAN DLC 8; actual DLC may be shorter. Data includes padding. No reassembly, text, DID or application-layer decoding. Original application layouts are preserved in source JSON; do not decode them at wire offsets. ";
CM_ SG_ 996 FlowPadding5 "TRANSPORT_CANDIDATE: normal-addressing ISO-TP. PSA-RE bits 8.7-8.0. ";
CM_ SG_ 996 FirstData6 "TRANSPORT_CANDIDATE: normal-addressing ISO-TP. PSA-RE bits 8.7-8.0. ";
CM_ SG_ 996 UnknownData7 "TRANSPORT_CANDIDATE: normal-addressing ISO-TP. PSA-RE bits 8.7-8.0. ";
CM_ SG_ 996 ConsecutiveData7 "TRANSPORT_CANDIDATE: normal-addressing ISO-TP. PSA-RE bits 8.7-8.0. ";
CM_ SG_ 996 SingleData7 "TRANSPORT_CANDIDATE: normal-addressing ISO-TP. PSA-RE bits 8.7-8.0. ";
CM_ SG_ 996 FlowPadding4 "TRANSPORT_CANDIDATE: normal-addressing ISO-TP. PSA-RE bits 7.7-7.0. ";
CM_ SG_ 996 FirstData5 "TRANSPORT_CANDIDATE: normal-addressing ISO-TP. PSA-RE bits 7.7-7.0. ";
CM_ SG_ 996 UnknownData6 "TRANSPORT_CANDIDATE: normal-addressing ISO-TP. PSA-RE bits 7.7-7.0. ";
CM_ SG_ 996 ConsecutiveData6 "TRANSPORT_CANDIDATE: normal-addressing ISO-TP. PSA-RE bits 7.7-7.0. ";
CM_ SG_ 996 SingleData6 "TRANSPORT_CANDIDATE: normal-addressing ISO-TP. PSA-RE bits 7.7-7.0. ";
CM_ SG_ 996 FlowPadding3 "TRANSPORT_CANDIDATE: normal-addressing ISO-TP. PSA-RE bits 6.7-6.0. ";
CM_ SG_ 996 FirstData4 "TRANSPORT_CANDIDATE: normal-addressing ISO-TP. PSA-RE bits 6.7-6.0. ";
CM_ SG_ 996 UnknownData5 "TRANSPORT_CANDIDATE: normal-addressing ISO-TP. PSA-RE bits 6.7-6.0. ";
CM_ SG_ 996 ConsecutiveData5 "TRANSPORT_CANDIDATE: normal-addressing ISO-TP. PSA-RE bits 6.7-6.0. ";
CM_ SG_ 996 SingleData5 "TRANSPORT_CANDIDATE: normal-addressing ISO-TP. PSA-RE bits 6.7-6.0. ";
CM_ SG_ 996 FlowPadding2 "TRANSPORT_CANDIDATE: normal-addressing ISO-TP. PSA-RE bits 5.7-5.0. ";
CM_ SG_ 996 FirstData3 "TRANSPORT_CANDIDATE: normal-addressing ISO-TP. PSA-RE bits 5.7-5.0. ";
CM_ SG_ 996 UnknownData4 "TRANSPORT_CANDIDATE: normal-addressing ISO-TP. PSA-RE bits 5.7-5.0. ";
CM_ SG_ 996 ConsecutiveData4 "TRANSPORT_CANDIDATE: normal-addressing ISO-TP. PSA-RE bits 5.7-5.0. ";
CM_ SG_ 996 SingleData4 "TRANSPORT_CANDIDATE: normal-addressing ISO-TP. PSA-RE bits 5.7-5.0. ";
CM_ SG_ 996 FlowPadding1 "TRANSPORT_CANDIDATE: normal-addressing ISO-TP. PSA-RE bits 4.7-4.0. ";
CM_ SG_ 996 FirstData2 "TRANSPORT_CANDIDATE: normal-addressing ISO-TP. PSA-RE bits 4.7-4.0. ";
CM_ SG_ 996 UnknownData3 "TRANSPORT_CANDIDATE: normal-addressing ISO-TP. PSA-RE bits 4.7-4.0. ";
CM_ SG_ 996 ConsecutiveData3 "TRANSPORT_CANDIDATE: normal-addressing ISO-TP. PSA-RE bits 4.7-4.0. ";
CM_ SG_ 996 SingleData3 "TRANSPORT_CANDIDATE: normal-addressing ISO-TP. PSA-RE bits 4.7-4.0. ";
CM_ SG_ 996 FirstData1 "TRANSPORT_CANDIDATE: normal-addressing ISO-TP. PSA-RE bits 3.7-3.0. ";
CM_ SG_ 996 UnknownData2 "TRANSPORT_CANDIDATE: normal-addressing ISO-TP. PSA-RE bits 3.7-3.0. ";
CM_ SG_ 996 ConsecutiveData2 "TRANSPORT_CANDIDATE: normal-addressing ISO-TP. PSA-RE bits 3.7-3.0. ";
CM_ SG_ 996 SingleData2 "TRANSPORT_CANDIDATE: normal-addressing ISO-TP. PSA-RE bits 3.7-3.0. ";
CM_ SG_ 996 SeparationTimeRaw "TRANSPORT_CANDIDATE: normal-addressing ISO-TP. PSA-RE bits 3.7-3.0. Raw STmin code; 0xF1..0xF9 are not milliseconds.";
CM_ SG_ 996 UnknownData1 "TRANSPORT_CANDIDATE: normal-addressing ISO-TP. PSA-RE bits 2.7-2.0. ";
CM_ SG_ 996 ConsecutiveData1 "TRANSPORT_CANDIDATE: normal-addressing ISO-TP. PSA-RE bits 2.7-2.0. ";
CM_ SG_ 996 SingleData1 "TRANSPORT_CANDIDATE: normal-addressing ISO-TP. PSA-RE bits 2.7-2.0. ";
CM_ SG_ 996 BlockSize "TRANSPORT_CANDIDATE: normal-addressing ISO-TP. PSA-RE bits 2.7-2.0. ";
CM_ SG_ 996 UnknownPciLow "TRANSPORT_CANDIDATE: normal-addressing ISO-TP. PSA-RE bits 1.3-1.0. ";
CM_ SG_ 996 FlowStatus "TRANSPORT_CANDIDATE: normal-addressing ISO-TP. PSA-RE bits 1.3-1.0. ";
CM_ SG_ 996 ConsecutiveSequence "TRANSPORT_CANDIDATE: normal-addressing ISO-TP. PSA-RE bits 1.3-1.0. ";
CM_ SG_ 996 FirstFrameLength "TRANSPORT_CANDIDATE: normal-addressing ISO-TP. PSA-RE bits 1.3-2.0. 12-bit declared PDU length; not a reassembled value.";
CM_ SG_ 996 SingleFrameLength "TRANSPORT_CANDIDATE: normal-addressing ISO-TP. PSA-RE bits 1.3-1.0. Declared data length; not a validity check.";
CM_ SG_ 996 IsoTpFrameType "TRANSPORT_CANDIDATE: normal-addressing ISO-TP. PSA-RE bits 1.7-1.4. PCI high nibble; normal addressing candidate.";
CM_ BO_ 997 "DATABASE_CANDIDATE: physical interpretation unverified; capture/layout evidence reported separately. INFO-DIV CAN, 125000 bit/s; CAN ID 0x3E5. PSA-RE title: RADIO_STATUS_PANEL. Remote control panel status: navigation buttons (up/down/left/right/escape/main), scroll wheel and audio/climate access. Source: https://github.com/prototux/PSA-RE/blob/67f7581e7622410efdbb29c7eda3b86982b9b450/buses/AEE2010.full/LS.INFO-DIV/3E5.yml. Source sender alternatives: ICSV,RAD; physical TX/gateway forwarding not verified. ";
CM_ SG_ 997 Knob2StepCounter "DATABASE_CANDIDATE: physical interpretation unverified; capture/layout evidence reported separately. PSA-RE bits 3.7-3.0. Knob 2 step counter Upstream default raw=0 (not necessarily valid data).";
CM_ SG_ 997 Knob2SyncRequest "DATABASE_CANDIDATE: physical interpretation unverified; capture/layout evidence reported separately. PSA-RE bits 2.0. Synchronization request for knob 2 on the multiplexed front panel Upstream default raw=0 (not necessarily valid data).";
CM_ SG_ 997 Unused1 "DATABASE_CANDIDATE: physical interpretation unverified; capture/layout evidence reported separately. PSA-RE bits 2.1. ";
CM_ SG_ 997 ListOpenRequest "DATABASE_CANDIDATE: physical interpretation unverified; capture/layout evidence reported separately. PSA-RE bits 2.2. Request to open a list from the MAUD (audio/multimedia unit) Upstream default raw=0 (not necessarily valid data).";
CM_ SG_ 997 List "DATABASE_CANDIDATE: physical interpretation unverified; capture/layout evidence reported separately. PSA-RE bits 2.3. \"LIST\" button of the CDT Upstream default raw=0 (not necessarily valid data).";
CM_ SG_ 997 Dark "DATABASE_CANDIDATE: physical interpretation unverified; capture/layout evidence reported separately. PSA-RE bits 2.4. \"Dark\" button of the CDT Upstream default raw=0 (not necessarily valid data).";
CM_ SG_ 997 PhoneMenuOpenRequest "DATABASE_CANDIDATE: physical interpretation unverified; capture/layout evidence reported separately. PSA-RE bits 2.5. Request to open the phone contextual menu Upstream default raw=0 (not necessarily valid data).";
CM_ SG_ 997 Escape "DATABASE_CANDIDATE: physical interpretation unverified; capture/layout evidence reported separately. PSA-RE bits 2.6. \"Escape\" button of the CDT Upstream default raw=0 (not necessarily valid data).";
CM_ SG_ 997 Ok "DATABASE_CANDIDATE: physical interpretation unverified; capture/layout evidence reported separately. PSA-RE bits 2.7. \"Validate\" button of the CDT Upstream default raw=0 (not necessarily valid data).";
CM_ SG_ 997 Left "DATABASE_CANDIDATE: physical interpretation unverified; capture/layout evidence reported separately. PSA-RE bits 1.0. Left arrow button pressed Upstream default raw=0 (not necessarily valid data).";
CM_ SG_ 997 Right "DATABASE_CANDIDATE: physical interpretation unverified; capture/layout evidence reported separately. PSA-RE bits 1.1. Right arrow button pressed Upstream default raw=0 (not necessarily valid data).";
CM_ SG_ 997 Down "DATABASE_CANDIDATE: physical interpretation unverified; capture/layout evidence reported separately. PSA-RE bits 1.2. Pressing the down arrow Upstream default raw=0 (not necessarily valid data).";
CM_ SG_ 997 Up "DATABASE_CANDIDATE: physical interpretation unverified; capture/layout evidence reported separately. PSA-RE bits 1.3. Up arrow button pressed Upstream default raw=0 (not necessarily valid data).";
CM_ SG_ 997 ModeDark "DATABASE_CANDIDATE: physical interpretation unverified; capture/layout evidence reported separately. PSA-RE bits 1.4. \"MODE/Dark\" button of the CDT Upstream default raw=0 (not necessarily valid data).";
CM_ SG_ 997 Mode "DATABASE_CANDIDATE: physical interpretation unverified; capture/layout evidence reported separately. PSA-RE bits 1.5. \"Mode\" button pressed Upstream default raw=0 (not necessarily valid data).";
CM_ SG_ 997 Menu "DATABASE_CANDIDATE: physical interpretation unverified; capture/layout evidence reported separately. PSA-RE bits 1.6. \"Menu\" button of the CDT Upstream default raw=0 (not necessarily valid data).";
CM_ SG_ 997 NewsMenuOpenRequest "DATABASE_CANDIDATE: physical interpretation unverified; capture/layout evidence reported separately. PSA-RE bits 1.7. \"News\" menu button press Upstream default raw=0 (not necessarily valid data).";
CM_ BO_ 999 "OWNER_CONFIRMED_FIELDS: MaintenanceType, MaintenanceType2, MaintenanceWrenchIconDisplay, DistanceBlinking, DistanceSymbol, TimeSymbol, Time, Distance; other fields remain candidates. INFO-DIV CAN, 125000 bit/s; CAN ID 0x3E7. PSA-RE title: MAINTENANCE_STATUS_EV. Service reminder status for electric/hybrid vehicles: remaining days, mileage sign and maintenance type pictograms. Source: https://github.com/prototux/PSA-RE/blob/67f7581e7622410efdbb29c7eda3b86982b9b450/buses/AEE2010.full/LS.INFO-DIV/3E7.yml. Source sender alternatives: ICSV,BSI; physical TX/gateway forwarding not verified. Observed 1164 frames in info_apka.csv,info_buzeni_obc.csv,info_charging.csv,info_standby.csv,info_start_jizda.csv,infocan.csv; DLCs [5]. Unresolved alternative source layouts preserved in source JSON. ";
CM_ SG_ 999 Distance "OWNER_CONFIRMED: owner Opel Corsa-e, 2026-10-31; Owner confirms ICSV_MaintenanceStatusEv data matches the vehicle. Scope: Service reminder interpretation at observed values; exhaustive flag combinations, limits and unavailable codes have not been tested.. PSA-RE bits 4.7-5.0. Mileage before maintenance Raw invalid=65535; numeric DBC decoders may still scale it: check raw before use.";
CM_ SG_ 999 Time "OWNER_CONFIRMED: owner Opel Corsa-e, 2026-10-31; Owner confirms ICSV_MaintenanceStatusEv data matches the vehicle. Scope: Service reminder interpretation at observed values; exhaustive flag combinations, limits and unavailable codes have not been tested.. PSA-RE bits 2.3-3.0. Number of days before/after the maintenance due date Raw invalid=4095; numeric DBC decoders may still scale it: check raw before use.";
CM_ SG_ 999 Unused2 "DATABASE_CANDIDATE: physical interpretation unverified; capture/layout evidence reported separately. PSA-RE bits 2.7-2.4. ";
CM_ SG_ 999 Unused1 "DATABASE_CANDIDATE: physical interpretation unverified; capture/layout evidence reported separately. PSA-RE bits 1.1-1.0. ";
CM_ SG_ 999 TimeSymbol "OWNER_CONFIRMED: owner Opel Corsa-e, 2026-10-31; Owner confirms ICSV_MaintenanceStatusEv data matches the vehicle. Scope: Service reminder interpretation at observed values; exhaustive flag combinations, limits and unavailable codes have not been tested.. PSA-RE bits 1.2. Sign of the time-based deadline";
CM_ SG_ 999 DistanceSymbol "OWNER_CONFIRMED: owner Opel Corsa-e, 2026-10-31; Owner confirms ICSV_MaintenanceStatusEv data matches the vehicle. Scope: Service reminder interpretation at observed values; exhaustive flag combinations, limits and unavailable codes have not been tested.. PSA-RE bits 1.3. Sign of the mileage before maintenance";
CM_ SG_ 999 DistanceBlinking "OWNER_CONFIRMED: owner Opel Corsa-e, 2026-10-31; Owner confirms ICSV_MaintenanceStatusEv data matches the vehicle. Scope: Service reminder interpretation at observed values; exhaustive flag combinations, limits and unavailable codes have not been tested.. PSA-RE bits 1.4. Display of the mileage and its sign";
CM_ SG_ 999 MaintenanceWrenchIconDisplay "OWNER_CONFIRMED: owner Opel Corsa-e, 2026-10-31; Owner confirms ICSV_MaintenanceStatusEv data matches the vehicle. Scope: Service reminder interpretation at observed values; exhaustive flag combinations, limits and unavailable codes have not been tested.. PSA-RE bits 1.5. Maintenance wrench icon display mode (fixed/blinking) Upstream default raw=0 (not necessarily valid data).";
CM_ SG_ 999 MaintenanceType2 "OWNER_CONFIRMED: owner Opel Corsa-e, 2026-10-31; Owner confirms ICSV_MaintenanceStatusEv data matches the vehicle. Scope: Service reminder interpretation at observed values; exhaustive flag combinations, limits and unavailable codes have not been tested.. PSA-RE bits 1.6. Maintenance schedule type (mileage-based or mileage + time-based) Upstream default raw=0 (not necessarily valid data).";
CM_ SG_ 999 MaintenanceType "OWNER_CONFIRMED: owner Opel Corsa-e, 2026-10-31; Owner confirms ICSV_MaintenanceStatusEv data matches the vehicle. Scope: Service reminder interpretation at observed values; exhaustive flag combinations, limits and unavailable codes have not been tested.. PSA-RE bits 1.7. Maintenance type";
CM_ BO_ 1000 "DATABASE_CANDIDATE: physical interpretation unverified; capture/layout evidence reported separately. INFO-DIV CAN, 125000 bit/s; CAN ID 0x3E8. PSA-RE title: ENGINE_ADIN_CONTROL_3. Cumulative distance driven in zero-emission (electric-only) mode for the current and previous two trips. Source: https://github.com/prototux/PSA-RE/blob/67f7581e7622410efdbb29c7eda3b86982b9b450/buses/AEE2010.full/LS.INFO-DIV/3E8.yml. Source sender alternatives: BSI; physical TX/gateway forwarding not verified. Observed 586 frames in info_apka.csv,info_buzeni_obc.csv,info_charging.csv,info_standby.csv,info_start_jizda.csv,infocan.csv; DLCs [8]. Unresolved alternative source layouts preserved in source JSON. ";
CM_ SG_ 1000 ZevDistanceTrip2 "DATABASE_CANDIDATE: physical interpretation unverified; capture/layout evidence reported separately. PSA-RE bits 7.7-8.0. Total distance of trip 2 covered in ZEV mode Raw invalid=65535; numeric DBC decoders may still scale it: check raw before use. Upstream default raw=65535 (not necessarily valid data).";
CM_ SG_ 1000 ZevDistanceTrip1 "DATABASE_CANDIDATE: physical interpretation unverified; capture/layout evidence reported separately. PSA-RE bits 5.7-6.0. Total distance of trip 1 covered in ZEV mode Raw invalid=65535; numeric DBC decoders may still scale it: check raw before use. Upstream default raw=65535 (not necessarily valid data).";
CM_ SG_ 1000 ZevDistanceCurrentTrip "DATABASE_CANDIDATE: physical interpretation unverified; capture/layout evidence reported separately. PSA-RE bits 3.7-4.0. Total distance of the current trip covered in ZEV mode Raw invalid=65535; numeric DBC decoders may still scale it: check raw before use. Upstream default raw=65535 (not necessarily valid data).";
CM_ SG_ 1000 TripDistanceCurrent "DATABASE_CANDIDATE: physical interpretation unverified; capture/layout evidence reported separately. PSA-RE bits 1.7-2.0. Total distance of the current trip Raw invalid=65535; numeric DBC decoders may still scale it: check raw before use. Upstream default raw=0 (not necessarily valid data).";
CM_ BO_ 1001 "DATABASE_CANDIDATE: physical interpretation unverified; capture/layout evidence reported separately. INFO-DIV CAN, 125000 bit/s; CAN ID 0x3E9. PSA-RE title: GEARBOX_DATA. Acknowledgement of a multi-frame navigation export status message. Source: https://github.com/prototux/PSA-RE/blob/67f7581e7622410efdbb29c7eda3b86982b9b450/buses/AEE2010.full/LS.INFO-DIV/3E9.yml. Source sender alternatives: CMB,ICSV,MATT; physical TX/gateway forwarding not verified. ";
CM_ SG_ 1001 SegmentationAckStream "DATABASE_CANDIDATE: physical interpretation unverified; capture/layout evidence reported separately. PSA-RE bits 1.7-1.0. Segmentation acknowledgment stream";
CM_ BO_ 1008 "VEHICLE_LAYOUT_UNKNOWN: Upstream ActualTorque conflicts with capture evidence: byte2 low nibble advances +5 modulo16 in all3528 adjacent pairs, and all3532 payloads have total nibble sum5 modulo16. Counter/checksum interpretation is a hypothesis; no torque scale is supported. Raw bytes only; original interpretation retained in source JSON. INFO-DIV CAN, 125000 bit/s; CAN ID 0x3F0. PSA-RE title: ENGINE_HYBRID_DYNAMIC_DATA_18. Engine dynamic data for hybrid variants: hybrid motor torque, resistant torque, pre-processed driver torque request, engine-restart and particulate-filter regeneration requests, raw powertrain state. Source: https://github.com/prototux/PSA-RE/blob/67f7581e7622410efdbb29c7eda3b86982b9b450/buses/AEE2010.full/LS.INFO-DIV/3F0.yml. Source sender alternatives: ICSV,BSI; physical TX/gateway forwarding not verified. Observed 5557 frames in info_apka.csv,info_buzeni_obc.csv,info_charging.csv,info_standby.csv,info_start_jizda.csv,infocan.csv; DLCs [8]. ";
CM_ SG_ 1008 RawByte8 "RAW. PSA-RE bits 8.7-8.0. Unmapped/padding bits, no physical interpretation.";
CM_ SG_ 1008 RawByte7 "RAW. PSA-RE bits 7.7-7.0. Unmapped/padding bits, no physical interpretation.";
CM_ SG_ 1008 RawByte6 "RAW. PSA-RE bits 6.7-6.0. Unmapped/padding bits, no physical interpretation.";
CM_ SG_ 1008 RawByte5 "RAW. PSA-RE bits 5.7-5.0. Unmapped/padding bits, no physical interpretation.";
CM_ SG_ 1008 RawByte4 "RAW. PSA-RE bits 4.7-4.0. Unmapped/padding bits, no physical interpretation.";
CM_ SG_ 1008 RawByte3 "RAW. PSA-RE bits 3.7-3.0. Unmapped/padding bits, no physical interpretation.";
CM_ SG_ 1008 RawByte2 "RAW. PSA-RE bits 2.7-2.0. Unmapped/padding bits, no physical interpretation.";
CM_ SG_ 1008 RawByte1 "RAW. PSA-RE bits 1.7-1.0. Unmapped/padding bits, no physical interpretation.";
CM_ BO_ 1009 "DATABASE_CANDIDATE: physical interpretation unverified; capture/layout evidence reported separately. INFO-DIV CAN, 125000 bit/s; CAN ID 0x3F1. PSA-RE title: CD_CHANGER_STATUS_ACK. Acknowledgement of a multi-frame CD changer status message. Source: https://github.com/prototux/PSA-RE/blob/67f7581e7622410efdbb29c7eda3b86982b9b450/buses/AEE2010.full/LS.INFO-DIV/3F1.yml. Source sender alternatives: ICSV,BTEL,OVIP; physical TX/gateway forwarding not verified. ";
CM_ SG_ 1009 SegmentationAckStream "DATABASE_CANDIDATE: physical interpretation unverified; capture/layout evidence reported separately. PSA-RE bits 1.7-1.0. Segmentation acknowledgment stream";
CM_ BO_ 1014 "DATABASE_CANDIDATE: physical interpretation unverified; capture/layout evidence reported separately. INFO-DIV CAN, 125000 bit/s; CAN ID 0x3F6. PSA-RE title: AMBIENT_LIGHTING_COLOR_COMMAND. Target colour, brightness level and transition time/type for the instrument cluster ambient lighting. Source: https://github.com/prototux/PSA-RE/blob/67f7581e7622410efdbb29c7eda3b86982b9b450/buses/AEE2010.full/LS.INFO-DIV/3F6.yml. Source sender alternatives: BSI; physical TX/gateway forwarding not verified. ";
CM_ SG_ 1014 Unused1 "DATABASE_CANDIDATE: physical interpretation unverified; capture/layout evidence reported separately. PSA-RE bits 3.3-3.0. ";
CM_ SG_ 1014 AmbientLightTargetColor "DATABASE_CANDIDATE: physical interpretation unverified; capture/layout evidence reported separately. PSA-RE bits 3.7-3.4. Target color for polychrome ambient lighting Upstream default raw=0 (not necessarily valid data).";
CM_ SG_ 1014 AmbientLightTransitionSyncBit "DATABASE_CANDIDATE: physical interpretation unverified; capture/layout evidence reported separately. PSA-RE bits 2.0. Ambient lighting transition synchronization bit Upstream default raw=0 (not necessarily valid data).";
CM_ SG_ 1014 AmbientLightTransitionType "DATABASE_CANDIDATE: physical interpretation unverified; capture/layout evidence reported separately. PSA-RE bits 2.2-2.1. Transition curve type for polychrome ambient lighting (linear/sine/log/exponential) Upstream default raw=0 (not necessarily valid data).";
CM_ SG_ 1014 AmbientLightTransitionTime "DATABASE_CANDIDATE: physical interpretation unverified; capture/layout evidence reported separately. PSA-RE bits 2.7-2.3. Requested transition duration for polychrome ambient lighting Upstream default raw=0 (not necessarily valid data).";
CM_ SG_ 1014 AmbientLightTargetLevel "DATABASE_CANDIDATE: physical interpretation unverified; capture/layout evidence reported separately. PSA-RE bits 1.7-1.0. Target output level for polychrome ambient lighting Upstream default raw=0 (not necessarily valid data).";
CM_ BO_ 1025 "DATABASE_CANDIDATE: physical interpretation unverified; capture/layout evidence reported separately. INFO-DIV CAN, 125000 bit/s; CAN ID 0x401. PSA-RE title: WAKEUP_BML. Sent by a node waking up the network; indicates the cause of the wake-up Source: https://github.com/prototux/PSA-RE/blob/67f7581e7622410efdbb29c7eda3b86982b9b450/buses/AEE2010.full/LS.INFO-DIV/401.yml. Source sender alternatives: SDCM; physical TX/gateway forwarding not verified. ";
CM_ SG_ 1025 WakeupCause8 "DATABASE_CANDIDATE: physical interpretation unverified; capture/layout evidence reported separately. PSA-RE bits 2.0. Wake-up cause 8";
CM_ SG_ 1025 WakeupCauseInternal "DATABASE_CANDIDATE: physical interpretation unverified; capture/layout evidence reported separately. PSA-RE bits 2.1. Wake-up for an internal reason (e.g. refreshing vehicle status after a reset)";
CM_ SG_ 1025 WakeupCauseBluetooth "DATABASE_CANDIDATE: physical interpretation unverified; capture/layout evidence reported separately. PSA-RE bits 2.2. Wake-up following communication between the smart device module (SDCM) and an authorized Bluetooth device (smart device)";
CM_ SG_ 1025 WakeupCauseNfc "DATABASE_CANDIDATE: physical interpretation unverified; capture/layout evidence reported separately. PSA-RE bits 2.3. Wake-up following communication between the smart device module (SDCM) and an authorized NFC device (smart device or NFC card)";
CM_ SG_ 1025 WakeupCauseMlKeyPresence "DATABASE_CANDIDATE: physical interpretation unverified; capture/layout evidence reported separately. PSA-RE bits 2.4. Wake-up caused by the presence of a tailgate (ML) key identifier";
CM_ SG_ 1025 WakeupCauseMlLockButton "DATABASE_CANDIDATE: physical interpretation unverified; capture/layout evidence reported separately. PSA-RE bits 2.5. Wake-up caused by pressing the tailgate (ML) locking button";
CM_ SG_ 1025 WakeupCauseCoe "DATABASE_CANDIDATE: physical interpretation unverified; capture/layout evidence reported separately. PSA-RE bits 2.6. Wake-up caused by the fuel filler flap open (COE) event";
CM_ SG_ 1025 WakeupCauseRfRemote "DATABASE_CANDIDATE: physical interpretation unverified; capture/layout evidence reported separately. PSA-RE bits 2.7. Wake-up caused by the RF remote control";
CM_ SG_ 1025 PsdNetworkWakeupPadding "DATABASE_CANDIDATE: physical interpretation unverified; capture/layout evidence reported separately. PSA-RE bits 1.7-1.0. 8 zero bits used to wake up the network";
CM_ BO_ 1042 "DATABASE_CANDIDATE: physical interpretation unverified; capture/layout evidence reported separately. INFO-DIV CAN, 125000 bit/s; CAN ID 0x412. PSA-RE title: BSI_CABIN_DATA_4. Sent by a node waking up the network; indicates the cause of the wake-up Source: https://github.com/prototux/PSA-RE/blob/67f7581e7622410efdbb29c7eda3b86982b9b450/buses/AEE2010.full/LS.INFO-DIV/412.yml. Source sender alternatives: BSI; physical TX/gateway forwarding not verified. Observed 10 frames in info_buzeni_obc.csv,infocan.csv; DLCs [8]. ";
CM_ SG_ 1042 BsiWakeupInfo6 "DATABASE_CANDIDATE: physical interpretation unverified; capture/layout evidence reported separately. PSA-RE bits 8.7-8.0. BSI wake-up information 6";
CM_ SG_ 1042 BsiWakeupInfo5 "DATABASE_CANDIDATE: physical interpretation unverified; capture/layout evidence reported separately. PSA-RE bits 7.7-7.0. BSI wake-up information 5";
CM_ SG_ 1042 BsiWakeupInfo4 "DATABASE_CANDIDATE: physical interpretation unverified; capture/layout evidence reported separately. PSA-RE bits 6.7-6.0. BSI wake-up information 4";
CM_ SG_ 1042 BsiWakeupInfo3 "DATABASE_CANDIDATE: physical interpretation unverified; capture/layout evidence reported separately. PSA-RE bits 5.7-5.0. BSI wake-up information 3";
CM_ SG_ 1042 BsiWakeupInfo2 "DATABASE_CANDIDATE: physical interpretation unverified; capture/layout evidence reported separately. PSA-RE bits 4.7-4.0. BSI wake-up information 2";
CM_ SG_ 1042 BsiWakeupInfo1 "DATABASE_CANDIDATE: physical interpretation unverified; capture/layout evidence reported separately. PSA-RE bits 3.7-3.0. BSI wake-up information 1";
CM_ SG_ 1042 BsiWakeupInfo0 "DATABASE_CANDIDATE: physical interpretation unverified; capture/layout evidence reported separately. PSA-RE bits 2.7-2.0. BSI wake-up information 0 OWNER_EVENT_OBSERVED: Owner-labelled AC cable insertion capture logs/info_buzeni_obc.csv starts with five 412 frames 00 20 00 00 00 00 00 00. This labels the observed full-byte value, not an isolated verified cause bit or an observed OBC transmitter. Scope: Observed event correlation; original signal layout retained. Capture begins with BSI announcement; no preceding OBC request or transaction ACK is captured.";
CM_ SG_ 1042 PsdNetworkWakeupPadding "DATABASE_CANDIDATE: physical interpretation unverified; capture/layout evidence reported separately. PSA-RE bits 1.7-1.0. 8 zero bits used to wake up the network";
CM_ BO_ 1056 "DATABASE_CANDIDATE: physical interpretation unverified; capture/layout evidence reported separately. INFO-DIV CAN, 125000 bit/s; CAN ID 0x420. PSA-RE title: WAKEUP_RAD. Sent by a node waking up the network; indicates the cause of the wake-up Source: https://github.com/prototux/PSA-RE/blob/67f7581e7622410efdbb29c7eda3b86982b9b450/buses/AEE2010.full/LS.INFO-DIV/420.yml. Source sender alternatives: RAD,ICSV; physical TX/gateway forwarding not verified. ";
CM_ SG_ 1056 WakeupCause8 "DATABASE_CANDIDATE: physical interpretation unverified; capture/layout evidence reported separately. PSA-RE bits 2.0. Wake-up cause 8";
CM_ SG_ 1056 WakeupCause7 "DATABASE_CANDIDATE: physical interpretation unverified; capture/layout evidence reported separately. PSA-RE bits 2.1. Wake-up cause 7";
CM_ SG_ 1056 WakeupCause6 "DATABASE_CANDIDATE: physical interpretation unverified; capture/layout evidence reported separately. PSA-RE bits 2.2. Wake-up cause 6";
CM_ SG_ 1056 WakeupCause5 "DATABASE_CANDIDATE: physical interpretation unverified; capture/layout evidence reported separately. PSA-RE bits 2.3. Wake-up cause 5";
CM_ SG_ 1056 WakeupCause4 "DATABASE_CANDIDATE: physical interpretation unverified; capture/layout evidence reported separately. PSA-RE bits 2.4. Wake-up cause 4";
CM_ SG_ 1056 WakeupCause3 "DATABASE_CANDIDATE: physical interpretation unverified; capture/layout evidence reported separately. PSA-RE bits 2.5. Wake-up cause 3";
CM_ SG_ 1056 WakeupCauseOnOffButton "DATABASE_CANDIDATE: physical interpretation unverified; capture/layout evidence reported separately. PSA-RE bits 2.6. Wake-up caused by pressing the ON/OFF button";
CM_ SG_ 1056 WakeupCause1 "DATABASE_CANDIDATE: physical interpretation unverified; capture/layout evidence reported separately. PSA-RE bits 2.7. Wake-up cause 1";
CM_ SG_ 1056 PsdNetworkWakeupPadding "DATABASE_CANDIDATE: physical interpretation unverified; capture/layout evidence reported separately. PSA-RE bits 1.7-1.0. 8 zero bits used to wake up the network";
CM_ BO_ 1060 "DATABASE_CANDIDATE: physical interpretation unverified; capture/layout evidence reported separately. INFO-DIV CAN, 125000 bit/s; CAN ID 0x424. PSA-RE title: WAKEUP_BTEL. Sent by a node waking up the network; indicates the cause of the wake-up Source: https://github.com/prototux/PSA-RE/blob/67f7581e7622410efdbb29c7eda3b86982b9b450/buses/AEE2010.full/LS.INFO-DIV/424.yml. Source sender alternatives: ICSV,BTEL,OVIP; physical TX/gateway forwarding not verified. ";
CM_ SG_ 1060 WakeupCause8 "DATABASE_CANDIDATE: physical interpretation unverified; capture/layout evidence reported separately. PSA-RE bits 2.0. Wake-up cause 8";
CM_ SG_ 1060 WakeupCause7 "DATABASE_CANDIDATE: physical interpretation unverified; capture/layout evidence reported separately. PSA-RE bits 2.1. Wake-up cause 7";
CM_ SG_ 1060 WakeupCause6 "DATABASE_CANDIDATE: physical interpretation unverified; capture/layout evidence reported separately. PSA-RE bits 2.2. Wake-up cause 6";
CM_ SG_ 1060 WakeupCause5 "DATABASE_CANDIDATE: physical interpretation unverified; capture/layout evidence reported separately. PSA-RE bits 2.3. Wake-up cause 5";
CM_ SG_ 1060 WakeupCause4 "DATABASE_CANDIDATE: physical interpretation unverified; capture/layout evidence reported separately. PSA-RE bits 2.4. Wake-up cause 4";
CM_ SG_ 1060 WakeupCause3 "DATABASE_CANDIDATE: physical interpretation unverified; capture/layout evidence reported separately. PSA-RE bits 2.5. Wake-up cause 3";
CM_ SG_ 1060 WakeupCauseOnOffButton "DATABASE_CANDIDATE: physical interpretation unverified; capture/layout evidence reported separately. PSA-RE bits 2.6. Wake-up caused by pressing the ON/OFF button";
CM_ SG_ 1060 WakeupCauseThermalPrecond_836499 "DATABASE_CANDIDATE: physical interpretation unverified; capture/layout evidence reported separately. PSA-RE bits 2.7. Wake-up caused by thermal preconditioning";
CM_ SG_ 1060 PsdNetworkWakeupPadding "DATABASE_CANDIDATE: physical interpretation unverified; capture/layout evidence reported separately. PSA-RE bits 1.7-1.0. 8 zero bits used to wake up the network";
CM_ BO_ 1084 "DATABASE_CANDIDATE: physical interpretation unverified; capture/layout evidence reported separately. INFO-DIV CAN, 125000 bit/s; CAN ID 0x43C. PSA-RE title: WAKEUP_MDS. Sent by a node waking up the network; indicates the cause of the wake-up Source: https://github.com/prototux/PSA-RE/blob/67f7581e7622410efdbb29c7eda3b86982b9b450/buses/AEE2010.full/LS.INFO-DIV/43C.yml. Source sender alternatives: MDS; physical TX/gateway forwarding not verified. Observed 10 frames in info_apka.csv; DLCs [2]. ";
CM_ SG_ 1084 WakeupCause8 "DATABASE_CANDIDATE: physical interpretation unverified; capture/layout evidence reported separately. PSA-RE bits 2.0. Wake-up cause 8";
CM_ SG_ 1084 WakeupCause7 "DATABASE_CANDIDATE: physical interpretation unverified; capture/layout evidence reported separately. PSA-RE bits 2.1. Wake-up cause 7";
CM_ SG_ 1084 WakeupCause6 "DATABASE_CANDIDATE: physical interpretation unverified; capture/layout evidence reported separately. PSA-RE bits 2.2. Wake-up cause 6";
CM_ SG_ 1084 WakeupCause5 "DATABASE_CANDIDATE: physical interpretation unverified; capture/layout evidence reported separately. PSA-RE bits 2.3. Wake-up cause 5";
CM_ SG_ 1084 WakeupCause4 "DATABASE_CANDIDATE: physical interpretation unverified; capture/layout evidence reported separately. PSA-RE bits 2.4. Wake-up cause 4";
CM_ SG_ 1084 WakeupCause3 "DATABASE_CANDIDATE: physical interpretation unverified; capture/layout evidence reported separately. PSA-RE bits 2.5. Wake-up cause 3";
CM_ SG_ 1084 WakeupCause2 "DATABASE_CANDIDATE: physical interpretation unverified; capture/layout evidence reported separately. PSA-RE bits 2.6. Wake-up cause 2";
CM_ SG_ 1084 WakeupCause1 "DATABASE_CANDIDATE: physical interpretation unverified; capture/layout evidence reported separately. PSA-RE bits 2.7. Wake-up cause 1";
CM_ SG_ 1084 PsdNetworkWakeupPadding "DATABASE_CANDIDATE: physical interpretation unverified; capture/layout evidence reported separately. PSA-RE bits 1.7-1.0. 8 zero bits used to wake up the network";
CM_ BO_ 1142 "DATABASE_CANDIDATE: physical interpretation unverified; capture/layout evidence reported separately. INFO-DIV CAN, 125000 bit/s; CAN ID 0x476. PSA-RE title: EVENT_ACK. Acknowledgement reply from an ECU (UCE), sent by the BSI. Source: https://github.com/prototux/PSA-RE/blob/67f7581e7622410efdbb29c7eda3b86982b9b450/buses/AEE2010.full/LS.INFO-DIV/476.yml. Source sender alternatives: BSI,ICSV; physical TX/gateway forwarding not verified. ";
CM_ SG_ 1142 UceDiagnosticResponse "DATABASE_CANDIDATE: physical interpretation unverified; capture/layout evidence reported separately. PSA-RE bits 1.7-1.0. ECU diagnostic response (component-specific)";
CM_ BO_ 1153 "DATABASE_CANDIDATE: physical interpretation unverified; capture/layout evidence reported separately. INFO-DIV CAN, 125000 bit/s; CAN ID 0x481. PSA-RE title: STEERING_LOCK_FAULT_EVENT. Steering column lock actuator: fault event, logged in the BSI fault log. Source: https://github.com/prototux/PSA-RE/blob/67f7581e7622410efdbb29c7eda3b86982b9b450/buses/AEE2010.full/LS.INFO-DIV/481.yml. Source sender alternatives: SDCM; physical TX/gateway forwarding not verified. ";
CM_ SG_ 1153 DiagBlock "DATABASE_CANDIDATE: physical interpretation unverified; capture/layout evidence reported separately. PSA-RE bits 1.3-8.0. Diagnostic block (fault log)";
CM_ SG_ 1153 FaultEventFrameNumber "DATABASE_CANDIDATE: physical interpretation unverified; capture/layout evidence reported separately. PSA-RE bits 1.5-1.4. Number of the fault event frame currently being transmitted";
CM_ SG_ 1153 FaultEventFrameCount "DATABASE_CANDIDATE: physical interpretation unverified; capture/layout evidence reported separately. PSA-RE bits 1.7-1.6. Number of fault event frames";
CM_ BO_ 1164 "DATABASE_CANDIDATE: physical interpretation unverified; capture/layout evidence reported separately. INFO-DIV CAN, 125000 bit/s; CAN ID 0x48C. PSA-RE title: CRT_FAULT_EVENT. CRT module: fault event, logged in the BSI fault log. Source: https://github.com/prototux/PSA-RE/blob/67f7581e7622410efdbb29c7eda3b86982b9b450/buses/AEE2010.full/LS.INFO-DIV/48C.yml. Source sender alternatives: CRT; physical TX/gateway forwarding not verified. ";
CM_ SG_ 1164 DiagBlock "DATABASE_CANDIDATE: physical interpretation unverified; capture/layout evidence reported separately. PSA-RE bits 1.3-8.0. Diagnostic block (fault log)";
CM_ SG_ 1164 FaultEventFrameNumber "DATABASE_CANDIDATE: physical interpretation unverified; capture/layout evidence reported separately. PSA-RE bits 1.5-1.4. Number of the fault event frame currently being transmitted";
CM_ SG_ 1164 FaultEventFrameCount "DATABASE_CANDIDATE: physical interpretation unverified; capture/layout evidence reported separately. PSA-RE bits 1.7-1.6. Number of fault event frames";
CM_ BO_ 1181 "DATABASE_CANDIDATE: physical interpretation unverified; capture/layout evidence reported separately. INFO-DIV CAN, 125000 bit/s; CAN ID 0x49D. PSA-RE title: PARK_ASSIST_FAULT_EVENT. Automatic parking assist system: fault event, logged in the BSI fault log. Source: https://github.com/prototux/PSA-RE/blob/67f7581e7622410efdbb29c7eda3b86982b9b450/buses/AEE2010.full/LS.INFO-DIV/49D.yml. Source sender alternatives: AAS; physical TX/gateway forwarding not verified. ";
CM_ SG_ 1181 DiagBlock "DATABASE_CANDIDATE: physical interpretation unverified; capture/layout evidence reported separately. PSA-RE bits 1.3-8.0. Diagnostic block (fault log)";
CM_ SG_ 1181 FaultEventFrameNumber "DATABASE_CANDIDATE: physical interpretation unverified; capture/layout evidence reported separately. PSA-RE bits 1.5-1.4. Number of the fault event frame currently being transmitted";
CM_ SG_ 1181 FaultEventFrameCount "DATABASE_CANDIDATE: physical interpretation unverified; capture/layout evidence reported separately. PSA-RE bits 1.7-1.6. Number of fault event frames";
CM_ BO_ 1183 "DATABASE_CANDIDATE: physical interpretation unverified; capture/layout evidence reported separately. INFO-DIV CAN, 125000 bit/s; CAN ID 0x49F. PSA-RE title: INSTRUMENT_CLUSTER_FAULT_EVENT. Instrument cluster: fault event, logged in the BSI fault log. Source: https://github.com/prototux/PSA-RE/blob/67f7581e7622410efdbb29c7eda3b86982b9b450/buses/AEE2010.full/LS.INFO-DIV/49F.yml. Source sender alternatives: CMB; physical TX/gateway forwarding not verified. Unresolved alternative source layouts preserved in source JSON. ";
CM_ SG_ 1183 DiagBlock "DATABASE_CANDIDATE: physical interpretation unverified; capture/layout evidence reported separately. PSA-RE bits 1.3-8.0. Diagnostic block (fault log)";
CM_ SG_ 1183 FaultEventFrameNumber "DATABASE_CANDIDATE: physical interpretation unverified; capture/layout evidence reported separately. PSA-RE bits 1.5-1.4. Number of the fault event frame currently being transmitted";
CM_ SG_ 1183 FaultEventFrameCount "DATABASE_CANDIDATE: physical interpretation unverified; capture/layout evidence reported separately. PSA-RE bits 1.7-1.6. Number of fault event frames";
CM_ BO_ 1184 "DATABASE_CANDIDATE: physical interpretation unverified; capture/layout evidence reported separately. INFO-DIV CAN, 125000 bit/s; CAN ID 0x4A0. PSA-RE title: RADIO_FAULT_EVENT. Radio/head unit: fault event, logged in the BSI fault log. Source: https://github.com/prototux/PSA-RE/blob/67f7581e7622410efdbb29c7eda3b86982b9b450/buses/AEE2010.full/LS.INFO-DIV/4A0.yml. Source sender alternatives: RAD,ICSV,BTEL; physical TX/gateway forwarding not verified. Unresolved alternative source layouts preserved in source JSON. ";
CM_ SG_ 1184 DiagBlock "DATABASE_CANDIDATE: physical interpretation unverified; capture/layout evidence reported separately. PSA-RE bits 1.3-8.0. Diagnostic block (fault log)";
CM_ SG_ 1184 FaultEventFrameNumber "DATABASE_CANDIDATE: physical interpretation unverified; capture/layout evidence reported separately. PSA-RE bits 1.5-1.4. Number of the fault event frame currently being transmitted";
CM_ SG_ 1184 FaultEventFrameCount "DATABASE_CANDIDATE: physical interpretation unverified; capture/layout evidence reported separately. PSA-RE bits 1.7-1.6. Number of fault event frames";
CM_ BO_ 1187 "DATABASE_CANDIDATE: physical interpretation unverified; capture/layout evidence reported separately. INFO-DIV CAN, 125000 bit/s; CAN ID 0x4A3. PSA-RE title: DASHCAM_FAULT_EVENT. In-car event recorder (dashcam): fault event, logged in the BSI fault log. Source: https://github.com/prototux/PSA-RE/blob/67f7581e7622410efdbb29c7eda3b86982b9b450/buses/AEE2010.full/LS.INFO-DIV/4A3.yml. Source sender alternatives: IDVR; physical TX/gateway forwarding not verified. ";
CM_ SG_ 1187 ContextParam4 "DATABASE_CANDIDATE: physical interpretation unverified; capture/layout evidence reported separately. PSA-RE bits 8.7-8.0. Additional context parameter 4";
CM_ SG_ 1187 ContextParam3 "DATABASE_CANDIDATE: physical interpretation unverified; capture/layout evidence reported separately. PSA-RE bits 7.7-7.0. Additional context parameter 3";
CM_ SG_ 1187 ContextParam2 "DATABASE_CANDIDATE: physical interpretation unverified; capture/layout evidence reported separately. PSA-RE bits 6.7-6.0. Additional context parameter 2";
CM_ SG_ 1187 ContextParam1 "DATABASE_CANDIDATE: physical interpretation unverified; capture/layout evidence reported separately. PSA-RE bits 5.7-5.0. Additional context parameter 1";
CM_ SG_ 1187 DegradedModeNumber "DATABASE_CANDIDATE: physical interpretation unverified; capture/layout evidence reported separately. PSA-RE bits 4.6-4.0. Degraded mode number";
CM_ SG_ 1187 ExtendedContextType "DATABASE_CANDIDATE: physical interpretation unverified; capture/layout evidence reported separately. PSA-RE bits 4.7. Type of extended context";
CM_ SG_ 1187 FaultCodeGeneric "DATABASE_CANDIDATE: physical interpretation unverified; capture/layout evidence reported separately. PSA-RE bits 2.7-3.0. Fault code";
CM_ SG_ 1187 HeaderBits2 "DATABASE_CANDIDATE: physical interpretation unverified; capture/layout evidence reported separately. PSA-RE bits 1.2-1.0. Last bits of the header";
CM_ SG_ 1187 EventType "DATABASE_CANDIDATE: physical interpretation unverified; capture/layout evidence reported separately. PSA-RE bits 1.3. Event type";
CM_ SG_ 1187 HeaderBits1 "DATABASE_CANDIDATE: physical interpretation unverified; capture/layout evidence reported separately. PSA-RE bits 1.7-1.4. First 4 header bits";
CM_ BO_ 1188 "DATABASE_CANDIDATE: physical interpretation unverified; capture/layout evidence reported separately. INFO-DIV CAN, 125000 bit/s; CAN ID 0x4A4. PSA-RE title: TELEMATICS_FAULT_EVENT. Telematics unit: fault event, logged in the BSI fault log. Source: https://github.com/prototux/PSA-RE/blob/67f7581e7622410efdbb29c7eda3b86982b9b450/buses/AEE2010.full/LS.INFO-DIV/4A4.yml. Source sender alternatives: ICSV,BTEL,OVIP,CMB; physical TX/gateway forwarding not verified. Observed 54 frames in info_buzeni_obc.csv,info_charging.csv; DLCs [8]. Unresolved alternative source layouts preserved in source JSON. ";
CM_ SG_ 1188 ContextParam4 "DATABASE_CANDIDATE: physical interpretation unverified; capture/layout evidence reported separately. PSA-RE bits 8.7-8.0. Additional context parameter 4";
CM_ SG_ 1188 ContextParam3 "DATABASE_CANDIDATE: physical interpretation unverified; capture/layout evidence reported separately. PSA-RE bits 7.7-7.0. Additional context parameter 3";
CM_ SG_ 1188 ContextParam2 "DATABASE_CANDIDATE: physical interpretation unverified; capture/layout evidence reported separately. PSA-RE bits 6.7-6.0. Additional context parameter 2";
CM_ SG_ 1188 ContextParam1 "DATABASE_CANDIDATE: physical interpretation unverified; capture/layout evidence reported separately. PSA-RE bits 5.7-5.0. Additional context parameter 1";
CM_ SG_ 1188 DegradedModeNumber "DATABASE_CANDIDATE: physical interpretation unverified; capture/layout evidence reported separately. PSA-RE bits 4.6-4.0. Degraded mode number";
CM_ SG_ 1188 ExtendedContextType "DATABASE_CANDIDATE: physical interpretation unverified; capture/layout evidence reported separately. PSA-RE bits 4.7. Type of extended context";
CM_ SG_ 1188 FaultCodeGeneric "DATABASE_CANDIDATE: physical interpretation unverified; capture/layout evidence reported separately. PSA-RE bits 2.7-3.0. Fault code";
CM_ SG_ 1188 HeaderBits2 "DATABASE_CANDIDATE: physical interpretation unverified; capture/layout evidence reported separately. PSA-RE bits 1.1-1.0. Last bits of the header";
CM_ SG_ 1188 BsiContextRelevance "DATABASE_CANDIDATE: physical interpretation unverified; capture/layout evidence reported separately. PSA-RE bits 1.2. BSI contexts relevance";
CM_ SG_ 1188 EventType "DATABASE_CANDIDATE: physical interpretation unverified; capture/layout evidence reported separately. PSA-RE bits 1.3. Event type";
CM_ SG_ 1188 HeaderBits1 "DATABASE_CANDIDATE: physical interpretation unverified; capture/layout evidence reported separately. PSA-RE bits 1.7-1.4. First 4 header bits";
CM_ BO_ 1189 "DATABASE_CANDIDATE: physical interpretation unverified; capture/layout evidence reported separately. INFO-DIV CAN, 125000 bit/s; CAN ID 0x4A5. PSA-RE title: DISPLAY_FAULT_EVENT. Multi-function display: fault event, logged in the BSI fault log. Source: https://github.com/prototux/PSA-RE/blob/67f7581e7622410efdbb29c7eda3b86982b9b450/buses/AEE2010.full/LS.INFO-DIV/4A5.yml. Source sender alternatives: EMF; physical TX/gateway forwarding not verified. ";
CM_ SG_ 1189 DiagBlock "DATABASE_CANDIDATE: physical interpretation unverified; capture/layout evidence reported separately. PSA-RE bits 1.3-8.0. Diagnostic block (fault log)";
CM_ SG_ 1189 FaultEventFrameNumber "DATABASE_CANDIDATE: physical interpretation unverified; capture/layout evidence reported separately. PSA-RE bits 1.5-1.4. Number of the fault event frame currently being transmitted";
CM_ SG_ 1189 FaultEventFrameCount "DATABASE_CANDIDATE: physical interpretation unverified; capture/layout evidence reported separately. PSA-RE bits 1.7-1.6. Number of fault event frames";
CM_ BO_ 1190 "DATABASE_CANDIDATE: physical interpretation unverified; capture/layout evidence reported separately. INFO-DIV CAN, 125000 bit/s; CAN ID 0x4A6. PSA-RE title: WIRELESS_CHARGER_FAULT_EVENT. Wireless phone charger: fault event, logged in the BSI fault log. Source: https://github.com/prototux/PSA-RE/blob/67f7581e7622410efdbb29c7eda3b86982b9b450/buses/AEE2010.full/LS.INFO-DIV/4A6.yml. Source sender alternatives: WLC; physical TX/gateway forwarding not verified. ";
CM_ SG_ 1190 DiagBlock "DATABASE_CANDIDATE: physical interpretation unverified; capture/layout evidence reported separately. PSA-RE bits 1.3-8.0. Diagnostic block (fault log)";
CM_ SG_ 1190 FaultEventFrameNumber "DATABASE_CANDIDATE: physical interpretation unverified; capture/layout evidence reported separately. PSA-RE bits 1.5-1.4. Number of the fault event frame currently being transmitted";
CM_ SG_ 1190 FaultEventFrameCount "DATABASE_CANDIDATE: physical interpretation unverified; capture/layout evidence reported separately. PSA-RE bits 1.7-1.6. Number of fault event frames";
CM_ BO_ 1200 "DATABASE_CANDIDATE: physical interpretation unverified; capture/layout evidence reported separately. INFO-DIV CAN, 125000 bit/s; CAN ID 0x4B0. PSA-RE title: VTH_FAULT_EVENT. HUD module: fault event, logged in the BSI fault log. Source: https://github.com/prototux/PSA-RE/blob/67f7581e7622410efdbb29c7eda3b86982b9b450/buses/AEE2010.full/LS.INFO-DIV/4B0.yml. Source sender alternatives: VTH; physical TX/gateway forwarding not verified. ";
CM_ SG_ 1200 DiagBlock "DATABASE_CANDIDATE: physical interpretation unverified; capture/layout evidence reported separately. PSA-RE bits 1.3-8.0. Diagnostic block (fault log)";
CM_ SG_ 1200 FaultEventFrameNumber "DATABASE_CANDIDATE: physical interpretation unverified; capture/layout evidence reported separately. PSA-RE bits 1.5-1.4. Number of the fault event frame currently being transmitted";
CM_ SG_ 1200 FaultEventFrameCount "DATABASE_CANDIDATE: physical interpretation unverified; capture/layout evidence reported separately. PSA-RE bits 1.7-1.6. Number of fault event frames";
CM_ BO_ 1201 "DATABASE_CANDIDATE: physical interpretation unverified; capture/layout evidence reported separately. INFO-DIV CAN, 125000 bit/s; CAN ID 0x4B1. PSA-RE title: FAULT_EVENT_CDC. CDC module: fault event, logged in the BSI fault log. Source: https://github.com/prototux/PSA-RE/blob/67f7581e7622410efdbb29c7eda3b86982b9b450/buses/AEE2010.full/LS.INFO-DIV/4B1.yml. Source sender alternatives: CDC; physical TX/gateway forwarding not verified. ";
CM_ SG_ 1201 DiagBlock "DATABASE_CANDIDATE: physical interpretation unverified; capture/layout evidence reported separately. PSA-RE bits 1.3-8.0. Diagnostic block (fault log)";
CM_ SG_ 1201 FaultEventFrameNumber "DATABASE_CANDIDATE: physical interpretation unverified; capture/layout evidence reported separately. PSA-RE bits 1.5-1.4. Number of the fault event frame currently being transmitted";
CM_ SG_ 1201 FaultEventFrameCount "DATABASE_CANDIDATE: physical interpretation unverified; capture/layout evidence reported separately. PSA-RE bits 1.7-1.6. Number of fault event frames";
CM_ BO_ 1202 "DATABASE_CANDIDATE: physical interpretation unverified; capture/layout evidence reported separately. INFO-DIV CAN, 125000 bit/s; CAN ID 0x4B2. PSA-RE title: VIN_VIS_DATA. MATT module: fault event, logged in the BSI fault log. Source: https://github.com/prototux/PSA-RE/blob/67f7581e7622410efdbb29c7eda3b86982b9b450/buses/AEE2010.full/LS.INFO-DIV/4B2.yml. Source sender alternatives: MATT; physical TX/gateway forwarding not verified. ";
CM_ SG_ 1202 DiagBlock "DATABASE_CANDIDATE: physical interpretation unverified; capture/layout evidence reported separately. PSA-RE bits 1.3-8.0. Diagnostic block (fault log)";
CM_ SG_ 1202 FaultEventFrameNumber "DATABASE_CANDIDATE: physical interpretation unverified; capture/layout evidence reported separately. PSA-RE bits 1.5-1.4. Number of the fault event frame currently being transmitted";
CM_ SG_ 1202 FaultEventFrameCount "DATABASE_CANDIDATE: physical interpretation unverified; capture/layout evidence reported separately. PSA-RE bits 1.7-1.6. Number of fault event frames";
CM_ BO_ 1203 "DATABASE_CANDIDATE: physical interpretation unverified; capture/layout evidence reported separately. INFO-DIV CAN, 125000 bit/s; CAN ID 0x4B3. PSA-RE title: FRONT_PARK_SENSOR_FAULT_EVENT. Front parking-assist sensor: fault event, logged in the BSI fault log. Source: https://github.com/prototux/PSA-RE/blob/67f7581e7622410efdbb29c7eda3b86982b9b450/buses/AEE2010.full/LS.INFO-DIV/4B3.yml. Source sender alternatives: AVP; physical TX/gateway forwarding not verified. ";
CM_ SG_ 1203 DiagBlock "DATABASE_CANDIDATE: physical interpretation unverified; capture/layout evidence reported separately. PSA-RE bits 1.3-8.0. Diagnostic block (fault log)";
CM_ SG_ 1203 FaultEventFrameNumber "DATABASE_CANDIDATE: physical interpretation unverified; capture/layout evidence reported separately. PSA-RE bits 1.5-1.4. Number of the fault event frame currently being transmitted";
CM_ SG_ 1203 FaultEventFrameCount "DATABASE_CANDIDATE: physical interpretation unverified; capture/layout evidence reported separately. PSA-RE bits 1.7-1.6. Number of fault event frames";
CM_ BO_ 1206 "DATABASE_CANDIDATE: physical interpretation unverified; capture/layout evidence reported separately. INFO-DIV CAN, 125000 bit/s; CAN ID 0x4B6. PSA-RE title: BTT_FAULT_EVENT. BTT module: fault event, logged in the BSI fault log. Source: https://github.com/prototux/PSA-RE/blob/67f7581e7622410efdbb29c7eda3b86982b9b450/buses/AEE2010.full/LS.INFO-DIV/4B6.yml. Source sender alternatives: BSG; physical TX/gateway forwarding not verified. ";
CM_ SG_ 1206 DiagBlock "DATABASE_CANDIDATE: physical interpretation unverified; capture/layout evidence reported separately. PSA-RE bits 1.3-8.0. Diagnostic block (fault log)";
CM_ SG_ 1206 FaultEventFrameNumber "DATABASE_CANDIDATE: physical interpretation unverified; capture/layout evidence reported separately. PSA-RE bits 1.5-1.4. Number of the fault event frame currently being transmitted";
CM_ SG_ 1206 FaultEventFrameCount "DATABASE_CANDIDATE: physical interpretation unverified; capture/layout evidence reported separately. PSA-RE bits 1.7-1.6. Number of fault event frames";
CM_ BO_ 1211 "DATABASE_CANDIDATE: physical interpretation unverified; capture/layout evidence reported separately. INFO-DIV CAN, 125000 bit/s; CAN ID 0x4BB. PSA-RE title: MULTIPLEXER_FAULT_EVENT. Multiplexing/gateway module: fault event, logged in the BSI fault log. Source: https://github.com/prototux/PSA-RE/blob/67f7581e7622410efdbb29c7eda3b86982b9b450/buses/AEE2010.full/LS.INFO-DIV/4BB.yml. Source sender alternatives: FMUX; physical TX/gateway forwarding not verified. ";
CM_ SG_ 1211 DiagBlock "DATABASE_CANDIDATE: physical interpretation unverified; capture/layout evidence reported separately. PSA-RE bits 1.3-8.0. Diagnostic block (fault log)";
CM_ SG_ 1211 FaultEventFrameNumber "DATABASE_CANDIDATE: physical interpretation unverified; capture/layout evidence reported separately. PSA-RE bits 1.5-1.4. Number of the fault event frame currently being transmitted";
CM_ SG_ 1211 FaultEventFrameCount "DATABASE_CANDIDATE: physical interpretation unverified; capture/layout evidence reported separately. PSA-RE bits 1.7-1.6. Number of fault event frames";
CM_ BO_ 1212 "DATABASE_CANDIDATE: physical interpretation unverified; capture/layout evidence reported separately. INFO-DIV CAN, 125000 bit/s; CAN ID 0x4BC. PSA-RE title: DIAGNOSTIC_SOCKET_FAULT_EVENT. Diagnostic socket interface module: fault event, logged in the BSI fault log. Source: https://github.com/prototux/PSA-RE/blob/67f7581e7622410efdbb29c7eda3b86982b9b450/buses/AEE2010.full/LS.INFO-DIV/4BC.yml. Source sender alternatives: MDS; physical TX/gateway forwarding not verified. Observed 2 frames in info_charging.csv; DLCs [8]. Unresolved alternative source layouts preserved in source JSON. ";
CM_ SG_ 1212 ContextParam4 "DATABASE_CANDIDATE: physical interpretation unverified; capture/layout evidence reported separately. PSA-RE bits 8.7-8.0. Additional context parameter 4";
CM_ SG_ 1212 ContextParam3 "DATABASE_CANDIDATE: physical interpretation unverified; capture/layout evidence reported separately. PSA-RE bits 7.7-7.0. Additional context parameter 3";
CM_ SG_ 1212 ContextParam2 "DATABASE_CANDIDATE: physical interpretation unverified; capture/layout evidence reported separately. PSA-RE bits 6.7-6.0. Additional context parameter 2";
CM_ SG_ 1212 ContextParam1 "DATABASE_CANDIDATE: physical interpretation unverified; capture/layout evidence reported separately. PSA-RE bits 5.7-5.0. Additional context parameter 1";
CM_ SG_ 1212 DegradedModeNumber "DATABASE_CANDIDATE: physical interpretation unverified; capture/layout evidence reported separately. PSA-RE bits 4.6-4.0. Degraded mode number";
CM_ SG_ 1212 ExtendedContextType "DATABASE_CANDIDATE: physical interpretation unverified; capture/layout evidence reported separately. PSA-RE bits 4.7. Type of extended context";
CM_ SG_ 1212 FaultCodeGeneric "DATABASE_CANDIDATE: physical interpretation unverified; capture/layout evidence reported separately. PSA-RE bits 2.7-3.0. Fault code";
CM_ SG_ 1212 HeaderBits2 "DATABASE_CANDIDATE: physical interpretation unverified; capture/layout evidence reported separately. PSA-RE bits 1.1-1.0. Last bits of the header";
CM_ SG_ 1212 BsiContextRelevance "DATABASE_CANDIDATE: physical interpretation unverified; capture/layout evidence reported separately. PSA-RE bits 1.2. BSI contexts relevance";
CM_ SG_ 1212 EventType "DATABASE_CANDIDATE: physical interpretation unverified; capture/layout evidence reported separately. PSA-RE bits 1.3. Event type";
CM_ SG_ 1212 HeaderBits1 "DATABASE_CANDIDATE: physical interpretation unverified; capture/layout evidence reported separately. PSA-RE bits 1.7-1.4. First 4 header bits";
CM_ BO_ 1213 "DATABASE_CANDIDATE: physical interpretation unverified; capture/layout evidence reported separately. INFO-DIV CAN, 125000 bit/s; CAN ID 0x4BD. PSA-RE title: AMPLIFIER_FAULT_EVENT. Audio amplifier: fault event, logged in the BSI fault log. Source: https://github.com/prototux/PSA-RE/blob/67f7581e7622410efdbb29c7eda3b86982b9b450/buses/AEE2010.full/LS.INFO-DIV/4BD.yml. Source sender alternatives: AMPLI; physical TX/gateway forwarding not verified. ";
CM_ SG_ 1213 ContextParam4 "DATABASE_CANDIDATE: physical interpretation unverified; capture/layout evidence reported separately. PSA-RE bits 8.7-8.0. Additional context parameter 4";
CM_ SG_ 1213 ContextParam3 "DATABASE_CANDIDATE: physical interpretation unverified; capture/layout evidence reported separately. PSA-RE bits 7.7-7.0. Additional context parameter 3";
CM_ SG_ 1213 ContextParam2 "DATABASE_CANDIDATE: physical interpretation unverified; capture/layout evidence reported separately. PSA-RE bits 6.7-6.0. Additional context parameter 2";
CM_ SG_ 1213 ContextParam1 "DATABASE_CANDIDATE: physical interpretation unverified; capture/layout evidence reported separately. PSA-RE bits 5.7-5.0. Additional context parameter 1";
CM_ SG_ 1213 DegradedModeNumber "DATABASE_CANDIDATE: physical interpretation unverified; capture/layout evidence reported separately. PSA-RE bits 4.6-4.0. Degraded mode number";
CM_ SG_ 1213 ExtendedContextType "DATABASE_CANDIDATE: physical interpretation unverified; capture/layout evidence reported separately. PSA-RE bits 4.7. Type of extended context";
CM_ SG_ 1213 FaultCodeGeneric "DATABASE_CANDIDATE: physical interpretation unverified; capture/layout evidence reported separately. PSA-RE bits 2.7-3.0. Fault code";
CM_ SG_ 1213 HeaderBits2 "DATABASE_CANDIDATE: physical interpretation unverified; capture/layout evidence reported separately. PSA-RE bits 1.2-1.0. Last bits of the header";
CM_ SG_ 1213 EventType "DATABASE_CANDIDATE: physical interpretation unverified; capture/layout evidence reported separately. PSA-RE bits 1.3. Event type";
CM_ SG_ 1213 HeaderBits1 "DATABASE_CANDIDATE: physical interpretation unverified; capture/layout evidence reported separately. PSA-RE bits 1.7-1.4. First 4 header bits";
CM_ BO_ 1281 "DATABASE_CANDIDATE: physical interpretation unverified; capture/layout evidence reported separately. INFO-DIV CAN, 125000 bit/s; CAN ID 0x501. PSA-RE title: BML_SUPERVISION. Network supervision: diagnostic session, network management state and communication fault counters Source: https://github.com/prototux/PSA-RE/blob/67f7581e7622410efdbb29c7eda3b86982b9b450/buses/AEE2010.full/LS.INFO-DIV/501.yml. Source sender alternatives: SDCM; physical TX/gateway forwarding not verified. Observed 590 frames in info_apka.csv,info_buzeni_obc.csv,info_charging.csv,info_standby.csv,info_start_jizda.csv,infocan.csv; DLCs [8]. ";
CM_ SG_ 1281 Unused4 "DATABASE_CANDIDATE: physical interpretation unverified; capture/layout evidence reported separately. PSA-RE bits 8.7-8.0. ";
CM_ SG_ 1281 Unused3 "DATABASE_CANDIDATE: physical interpretation unverified; capture/layout evidence reported separately. PSA-RE bits 7.7-7.0. ";
CM_ SG_ 1281 AbsentBml "DATABASE_CANDIDATE: physical interpretation unverified; capture/layout evidence reported separately. PSA-RE bits 6.7-6.0. Absent computer(s) supervised by BML. Upstream default raw=0 (not necessarily valid data).";
CM_ SG_ 1281 PfhmComLossCounter "DATABASE_CANDIDATE: physical interpretation unverified; capture/layout evidence reported separately. PSA-RE bits 5.7-5.0. Rolling counter incremented by 1 at each \"communication loss\" transition, reset to 0 at initialization. Upstream default raw=0 (not necessarily valid data).";
CM_ SG_ 1281 PfhmBusOffCounter "DATABASE_CANDIDATE: physical interpretation unverified; capture/layout evidence reported separately. PSA-RE bits 4.7-4.0. Rolling counter incremented by 1 at each \"bus-off\" fault, reset to 0 at initialization. Upstream default raw=0 (not necessarily valid data).";
CM_ SG_ 1281 PfhmNAsCounter "DATABASE_CANDIDATE: physical interpretation unverified; capture/layout evidence reported separately. PSA-RE bits 3.7-3.0. Rolling counter incremented at each \"message not sent\" detection, after 1 attempt on the N_As timeout; reset to 0 at initialization. Upstream default raw=0 (not necessarily valid data).";
CM_ SG_ 1281 NerrFaultCounterValue "DATABASE_CANDIDATE: physical interpretation unverified; capture/layout evidence reported separately. PSA-RE bits 2.7-2.0. Value of the NERR fault counter for the line diagnosis. Upstream default raw=0 (not necessarily valid data).";
CM_ SG_ 1281 Unused2 "DATABASE_CANDIDATE: physical interpretation unverified; capture/layout evidence reported separately. PSA-RE bits 1.2-1.0. ";
CM_ SG_ 1281 SupervisionTaskState "DATABASE_CANDIDATE: physical interpretation unverified; capture/layout evidence reported separately. PSA-RE bits 1.3. Network supervision task state. Upstream default raw=0 (not necessarily valid data).";
CM_ SG_ 1281 NerrBitStatus "DATABASE_CANDIDATE: physical interpretation unverified; capture/layout evidence reported separately. PSA-RE bits 1.4. NERR (network error) bit status. Upstream default raw=0 (not necessarily valid data).";
CM_ SG_ 1281 ComLossFault "DATABASE_CANDIDATE: physical interpretation unverified; capture/layout evidence reported separately. PSA-RE bits 1.5. Communication loss fault. Upstream default raw=0 (not necessarily valid data).";
CM_ SG_ 1281 Unused1 "DATABASE_CANDIDATE: physical interpretation unverified; capture/layout evidence reported separately. PSA-RE bits 1.7-1.6. ";
CM_ BO_ 1292 "DATABASE_CANDIDATE: physical interpretation unverified; capture/layout evidence reported separately. INFO-DIV CAN, 125000 bit/s; CAN ID 0x50C. PSA-RE title: CRT_SUPERVISION. Network supervision: diagnostic session, network management state and communication fault counters Source: https://github.com/prototux/PSA-RE/blob/67f7581e7622410efdbb29c7eda3b86982b9b450/buses/AEE2010.full/LS.INFO-DIV/50C.yml. Source sender alternatives: CRT; physical TX/gateway forwarding not verified. ";
CM_ SG_ 1292 Unused4 "DATABASE_CANDIDATE: physical interpretation unverified; capture/layout evidence reported separately. PSA-RE bits 8.7-8.0. ";
CM_ SG_ 1292 Unused3 "DATABASE_CANDIDATE: physical interpretation unverified; capture/layout evidence reported separately. PSA-RE bits 7.7-7.0. ";
CM_ SG_ 1292 AbsentFmux1 "DATABASE_CANDIDATE: physical interpretation unverified; capture/layout evidence reported separately. PSA-RE bits 6.7-6.0. Absent computer(s) supervised by the MUX front panel. Upstream default raw=0 (not necessarily valid data).";
CM_ SG_ 1292 PfhmComLossCounter "DATABASE_CANDIDATE: physical interpretation unverified; capture/layout evidence reported separately. PSA-RE bits 5.7-5.0. Rolling counter incremented by 1 at each \"communication loss\" transition, reset to 0 at initialization. Upstream default raw=0 (not necessarily valid data).";
CM_ SG_ 1292 PfhmBusOffCounter "DATABASE_CANDIDATE: physical interpretation unverified; capture/layout evidence reported separately. PSA-RE bits 4.7-4.0. Rolling counter incremented by 1 at each \"bus-off\" fault, reset to 0 at initialization. Upstream default raw=0 (not necessarily valid data).";
CM_ SG_ 1292 PfhmNAsCounter "DATABASE_CANDIDATE: physical interpretation unverified; capture/layout evidence reported separately. PSA-RE bits 3.7-3.0. Rolling counter incremented at each \"message not sent\" detection, after 1 attempt on the N_As timeout; reset to 0 at initialization. Upstream default raw=0 (not necessarily valid data).";
CM_ SG_ 1292 NerrFaultCounterValue "DATABASE_CANDIDATE: physical interpretation unverified; capture/layout evidence reported separately. PSA-RE bits 2.7-2.0. Value of the NERR fault counter for the line diagnosis. Upstream default raw=0 (not necessarily valid data).";
CM_ SG_ 1292 Unused2 "DATABASE_CANDIDATE: physical interpretation unverified; capture/layout evidence reported separately. PSA-RE bits 1.2-1.0. ";
CM_ SG_ 1292 SupervisionTaskState "DATABASE_CANDIDATE: physical interpretation unverified; capture/layout evidence reported separately. PSA-RE bits 1.3. Network supervision task state. Upstream default raw=0 (not necessarily valid data).";
CM_ SG_ 1292 NerrBitStatus "DATABASE_CANDIDATE: physical interpretation unverified; capture/layout evidence reported separately. PSA-RE bits 1.4. NERR (network error) bit status. Upstream default raw=0 (not necessarily valid data).";
CM_ SG_ 1292 ComLossFault "DATABASE_CANDIDATE: physical interpretation unverified; capture/layout evidence reported separately. PSA-RE bits 1.5. Communication loss fault. Upstream default raw=0 (not necessarily valid data).";
CM_ SG_ 1292 Unused1 "DATABASE_CANDIDATE: physical interpretation unverified; capture/layout evidence reported separately. PSA-RE bits 1.7-1.6. ";
CM_ BO_ 1298 "DATABASE_CANDIDATE: physical interpretation unverified; capture/layout evidence reported separately. INFO-DIV CAN, 125000 bit/s; CAN ID 0x512. PSA-RE title: BSI_DRIVE_MODE_REQUESTS. Network supervision: diagnostic session, network management state and communication fault counters Source: https://github.com/prototux/PSA-RE/blob/67f7581e7622410efdbb29c7eda3b86982b9b450/buses/AEE2010.full/LS.INFO-DIV/512.yml. Source sender alternatives: BSI; physical TX/gateway forwarding not verified. Observed 586 frames in info_apka.csv,info_buzeni_obc.csv,info_charging.csv,info_standby.csv,info_start_jizda.csv,infocan.csv; DLCs [8]. ";
CM_ SG_ 1298 AbsentBsi3 "DATABASE_CANDIDATE: physical interpretation unverified; capture/layout evidence reported separately. PSA-RE bits 8.7-8.0. Absent computer(s) supervised by BSI. Upstream default raw=0 (not necessarily valid data).";
CM_ SG_ 1298 AbsentBsi2 "DATABASE_CANDIDATE: physical interpretation unverified; capture/layout evidence reported separately. PSA-RE bits 7.7-7.0. Absent computer(s) supervised by BSI. Upstream default raw=0 (not necessarily valid data).";
CM_ SG_ 1298 AbsentBsi1 "DATABASE_CANDIDATE: physical interpretation unverified; capture/layout evidence reported separately. PSA-RE bits 6.7-6.0. Absent computer(s) supervised by BSI. Upstream default raw=0 (not necessarily valid data).";
CM_ SG_ 1298 PfhmComLossCounter "DATABASE_CANDIDATE: physical interpretation unverified; capture/layout evidence reported separately. PSA-RE bits 5.7-5.0. Rolling counter incremented by 1 at each \"communication loss\" transition, reset to 0 at initialization. Upstream default raw=0 (not necessarily valid data).";
CM_ SG_ 1298 PfhmBusOffCounter "DATABASE_CANDIDATE: physical interpretation unverified; capture/layout evidence reported separately. PSA-RE bits 4.7-4.0. Rolling counter incremented by 1 at each \"bus-off\" fault, reset to 0 at initialization. Upstream default raw=0 (not necessarily valid data).";
CM_ SG_ 1298 PfhmNAsCounter "DATABASE_CANDIDATE: physical interpretation unverified; capture/layout evidence reported separately. PSA-RE bits 3.7-3.0. Rolling counter incremented at each \"message not sent\" detection, after 1 attempt on the N_As timeout; reset to 0 at initialization. Upstream default raw=0 (not necessarily valid data).";
CM_ SG_ 1298 NerrFaultCounterValue "DATABASE_CANDIDATE: physical interpretation unverified; capture/layout evidence reported separately. PSA-RE bits 2.7-2.0. Value of the NERR fault counter for the line diagnosis. Upstream default raw=0 (not necessarily valid data).";
CM_ SG_ 1298 Unused2 "DATABASE_CANDIDATE: physical interpretation unverified; capture/layout evidence reported separately. PSA-RE bits 1.2-1.0. ";
CM_ SG_ 1298 SupervisionTaskState "DATABASE_CANDIDATE: physical interpretation unverified; capture/layout evidence reported separately. PSA-RE bits 1.3. Network supervision task state. Upstream default raw=0 (not necessarily valid data).";
CM_ SG_ 1298 NerrBitStatus "DATABASE_CANDIDATE: physical interpretation unverified; capture/layout evidence reported separately. PSA-RE bits 1.4. NERR (network error) bit status. Upstream default raw=0 (not necessarily valid data).";
CM_ SG_ 1298 ComLossFault "DATABASE_CANDIDATE: physical interpretation unverified; capture/layout evidence reported separately. PSA-RE bits 1.5. Communication loss fault. Upstream default raw=0 (not necessarily valid data).";
CM_ SG_ 1298 Unused1 "DATABASE_CANDIDATE: physical interpretation unverified; capture/layout evidence reported separately. PSA-RE bits 1.7-1.6. ";
CM_ BO_ 1309 "DATABASE_CANDIDATE: physical interpretation unverified; capture/layout evidence reported separately. INFO-DIV CAN, 125000 bit/s; CAN ID 0x51D. PSA-RE title: AAS_SUPERVISION. Network supervision: diagnostic session, network management state and communication fault counters Source: https://github.com/prototux/PSA-RE/blob/67f7581e7622410efdbb29c7eda3b86982b9b450/buses/AEE2010.full/LS.INFO-DIV/51D.yml. Source sender alternatives: AAS; physical TX/gateway forwarding not verified. ";
CM_ SG_ 1309 Unused4 "DATABASE_CANDIDATE: physical interpretation unverified; capture/layout evidence reported separately. PSA-RE bits 8.7-8.0. ";
CM_ SG_ 1309 Unused3 "DATABASE_CANDIDATE: physical interpretation unverified; capture/layout evidence reported separately. PSA-RE bits 7.7-7.0. ";
CM_ SG_ 1309 AbsentAas "DATABASE_CANDIDATE: physical interpretation unverified; capture/layout evidence reported separately. PSA-RE bits 6.7-6.0. Absent computer(s) supervised by AAS. Upstream default raw=0 (not necessarily valid data).";
CM_ SG_ 1309 PfhmComLossCounter "DATABASE_CANDIDATE: physical interpretation unverified; capture/layout evidence reported separately. PSA-RE bits 5.7-5.0. Rolling counter incremented by 1 at each \"communication loss\" transition, reset to 0 at initialization. Upstream default raw=0 (not necessarily valid data).";
CM_ SG_ 1309 PfhmBusOffCounter "DATABASE_CANDIDATE: physical interpretation unverified; capture/layout evidence reported separately. PSA-RE bits 4.7-4.0. Rolling counter incremented by 1 at each \"bus-off\" fault, reset to 0 at initialization. Upstream default raw=0 (not necessarily valid data).";
CM_ SG_ 1309 PfhmNAsCounter "DATABASE_CANDIDATE: physical interpretation unverified; capture/layout evidence reported separately. PSA-RE bits 3.7-3.0. Rolling counter incremented at each \"message not sent\" detection, after 1 attempt on the N_As timeout; reset to 0 at initialization. Upstream default raw=0 (not necessarily valid data).";
CM_ SG_ 1309 NerrFaultCounterValue "DATABASE_CANDIDATE: physical interpretation unverified; capture/layout evidence reported separately. PSA-RE bits 2.7-2.0. Value of the NERR fault counter for the line diagnosis. Upstream default raw=0 (not necessarily valid data).";
CM_ SG_ 1309 Unused2 "DATABASE_CANDIDATE: physical interpretation unverified; capture/layout evidence reported separately. PSA-RE bits 1.2-1.0. ";
CM_ SG_ 1309 SupervisionTaskState "DATABASE_CANDIDATE: physical interpretation unverified; capture/layout evidence reported separately. PSA-RE bits 1.3. Network supervision task state. Upstream default raw=0 (not necessarily valid data).";
CM_ SG_ 1309 NerrBitStatus "DATABASE_CANDIDATE: physical interpretation unverified; capture/layout evidence reported separately. PSA-RE bits 1.4. NERR (network error) bit status. Upstream default raw=0 (not necessarily valid data).";
CM_ SG_ 1309 ComLossFault "DATABASE_CANDIDATE: physical interpretation unverified; capture/layout evidence reported separately. PSA-RE bits 1.5. Communication loss fault. Upstream default raw=0 (not necessarily valid data).";
CM_ SG_ 1309 Unused1 "DATABASE_CANDIDATE: physical interpretation unverified; capture/layout evidence reported separately. PSA-RE bits 1.7-1.6. ";
CM_ BO_ 1311 "DATABASE_CANDIDATE: physical interpretation unverified; capture/layout evidence reported separately. INFO-DIV CAN, 125000 bit/s; CAN ID 0x51F. PSA-RE title: LANE_DEPARTURE_WARNING_LEFT_STATUS. Network supervision: diagnostic session, network management state and communication fault counters Source: https://github.com/prototux/PSA-RE/blob/67f7581e7622410efdbb29c7eda3b86982b9b450/buses/AEE2010.full/LS.INFO-DIV/51F.yml. Source sender alternatives: CMB; physical TX/gateway forwarding not verified. VEHICLE_SOURCE_REVIEW: Owner reports original instrument cluster unit004 connected for info_buzeni_obc.csv and absent in earlier captures. This ID is absent in info_standby.csv and fully operational info_start_jizda.csv; upstream lists CMB among possible senders. Owner approved limiting IC attribution to these nine messages. Scope: Vehicle-specific sender attribution from installation report/capture comparison and compatible source alias; does not validate signal meanings or exclude gateway forwarding. Observed 410 frames in info_buzeni_obc.csv,info_charging.csv; DLCs [8]. Unresolved alternative source layouts preserved in source JSON. ";
CM_ SG_ 1311 AbsentCmb3 "DATABASE_CANDIDATE: physical interpretation unverified; capture/layout evidence reported separately. PSA-RE bits 8.7-8.0. Absent computer(s) supervised by CMB. Upstream default raw=0 (not necessarily valid data).";
CM_ SG_ 1311 AbsentCmb2 "DATABASE_CANDIDATE: physical interpretation unverified; capture/layout evidence reported separately. PSA-RE bits 7.7-7.0. Absent computer(s) supervised by CMB. Upstream default raw=0 (not necessarily valid data).";
CM_ SG_ 1311 AbsentCmb1 "DATABASE_CANDIDATE: physical interpretation unverified; capture/layout evidence reported separately. PSA-RE bits 6.7-6.0. Absent computer(s) supervised by CMB. Upstream default raw=0 (not necessarily valid data).";
CM_ SG_ 1311 PfhmComLossCounter "DATABASE_CANDIDATE: physical interpretation unverified; capture/layout evidence reported separately. PSA-RE bits 5.7-5.0. Rolling counter incremented by 1 at each \"communication loss\" transition, reset to 0 at initialization. Upstream default raw=0 (not necessarily valid data).";
CM_ SG_ 1311 PfhmBusOffCounter "DATABASE_CANDIDATE: physical interpretation unverified; capture/layout evidence reported separately. PSA-RE bits 4.7-4.0. Rolling counter incremented by 1 at each \"bus-off\" fault, reset to 0 at initialization. Upstream default raw=0 (not necessarily valid data).";
CM_ SG_ 1311 PfhmNAsCounter "DATABASE_CANDIDATE: physical interpretation unverified; capture/layout evidence reported separately. PSA-RE bits 3.7-3.0. Rolling counter incremented at each \"message not sent\" detection, after 1 attempt on the N_As timeout; reset to 0 at initialization. Upstream default raw=0 (not necessarily valid data).";
CM_ SG_ 1311 NerrFaultCounterValue "DATABASE_CANDIDATE: physical interpretation unverified; capture/layout evidence reported separately. PSA-RE bits 2.7-2.0. Value of the NERR fault counter for the line diagnosis. Upstream default raw=0 (not necessarily valid data).";
CM_ SG_ 1311 DiagnosticSessionActive "DATABASE_CANDIDATE: physical interpretation unverified; capture/layout evidence reported separately. PSA-RE bits 1.0. System currently performing a diagnostic activity. Upstream default raw=0 (not necessarily valid data).";
CM_ SG_ 1311 UnderDiagnosisSession "DATABASE_CANDIDATE: physical interpretation unverified; capture/layout evidence reported separately. PSA-RE bits 1.1. System currently under a diagnostic session. Upstream default raw=0 (not necessarily valid data).";
CM_ SG_ 1311 FunctionalDegradedMode "DATABASE_CANDIDATE: physical interpretation unverified; capture/layout evidence reported separately. PSA-RE bits 1.2. System operating in functional degraded mode. Upstream default raw=0 (not necessarily valid data).";
CM_ SG_ 1311 SupervisionTaskState "DATABASE_CANDIDATE: physical interpretation unverified; capture/layout evidence reported separately. PSA-RE bits 1.3. Network supervision task state. Upstream default raw=0 (not necessarily valid data).";
CM_ SG_ 1311 NerrBitStatus "DATABASE_CANDIDATE: physical interpretation unverified; capture/layout evidence reported separately. PSA-RE bits 1.4. NERR (network error) bit status. Upstream default raw=0 (not necessarily valid data).";
CM_ SG_ 1311 ComLossFault "DATABASE_CANDIDATE: physical interpretation unverified; capture/layout evidence reported separately. PSA-RE bits 1.5. Communication loss fault. Upstream default raw=0 (not necessarily valid data).";
CM_ SG_ 1311 Unused1 "DATABASE_CANDIDATE: physical interpretation unverified; capture/layout evidence reported separately. PSA-RE bits 1.7-1.6. ";
CM_ BO_ 1312 "DATABASE_CANDIDATE: physical interpretation unverified; capture/layout evidence reported separately. INFO-DIV CAN, 125000 bit/s; CAN ID 0x520. PSA-RE title: RAD_SUPERVISION. Network supervision: diagnostic session, network management state and communication fault counters Source: https://github.com/prototux/PSA-RE/blob/67f7581e7622410efdbb29c7eda3b86982b9b450/buses/AEE2010.full/LS.INFO-DIV/520.yml. Source sender alternatives: RAD,ICSV,BTEL; physical TX/gateway forwarding not verified. ";
CM_ SG_ 1312 AbsentRad3 "DATABASE_CANDIDATE: physical interpretation unverified; capture/layout evidence reported separately. PSA-RE bits 8.7-8.0. Absent computer(s) supervised by RAD. Upstream default raw=0 (not necessarily valid data).";
CM_ SG_ 1312 AbsentRad2 "DATABASE_CANDIDATE: physical interpretation unverified; capture/layout evidence reported separately. PSA-RE bits 7.7-7.0. Absent computer(s) supervised by RAD. Upstream default raw=0 (not necessarily valid data).";
CM_ SG_ 1312 AbsentRad1 "DATABASE_CANDIDATE: physical interpretation unverified; capture/layout evidence reported separately. PSA-RE bits 6.7-6.0. Absent computer(s) supervised by RAD. Upstream default raw=0 (not necessarily valid data).";
CM_ SG_ 1312 PfhmComLossCounter "DATABASE_CANDIDATE: physical interpretation unverified; capture/layout evidence reported separately. PSA-RE bits 5.7-5.0. Rolling counter incremented by 1 at each \"communication loss\" transition, reset to 0 at initialization. Upstream default raw=0 (not necessarily valid data).";
CM_ SG_ 1312 PfhmBusOffCounter "DATABASE_CANDIDATE: physical interpretation unverified; capture/layout evidence reported separately. PSA-RE bits 4.7-4.0. Rolling counter incremented by 1 at each \"bus-off\" fault, reset to 0 at initialization. Upstream default raw=0 (not necessarily valid data).";
CM_ SG_ 1312 PfhmNAsCounter "DATABASE_CANDIDATE: physical interpretation unverified; capture/layout evidence reported separately. PSA-RE bits 3.7-3.0. Rolling counter incremented at each \"message not sent\" detection, after 1 attempt on the N_As timeout; reset to 0 at initialization. Upstream default raw=0 (not necessarily valid data).";
CM_ SG_ 1312 NerrFaultCounterValue "DATABASE_CANDIDATE: physical interpretation unverified; capture/layout evidence reported separately. PSA-RE bits 2.7-2.0. Value of the NERR fault counter for the line diagnosis. Upstream default raw=0 (not necessarily valid data).";
CM_ SG_ 1312 Unused2 "DATABASE_CANDIDATE: physical interpretation unverified; capture/layout evidence reported separately. PSA-RE bits 1.2-1.0. ";
CM_ SG_ 1312 SupervisionTaskState "DATABASE_CANDIDATE: physical interpretation unverified; capture/layout evidence reported separately. PSA-RE bits 1.3. Network supervision task state. Upstream default raw=0 (not necessarily valid data).";
CM_ SG_ 1312 NerrBitStatus "DATABASE_CANDIDATE: physical interpretation unverified; capture/layout evidence reported separately. PSA-RE bits 1.4. NERR (network error) bit status. Upstream default raw=0 (not necessarily valid data).";
CM_ SG_ 1312 ComLossFault "DATABASE_CANDIDATE: physical interpretation unverified; capture/layout evidence reported separately. PSA-RE bits 1.5. Communication loss fault. Upstream default raw=0 (not necessarily valid data).";
CM_ SG_ 1312 Unused1 "DATABASE_CANDIDATE: physical interpretation unverified; capture/layout evidence reported separately. PSA-RE bits 1.7-1.6. ";
CM_ BO_ 1315 "DATABASE_CANDIDATE: physical interpretation unverified; capture/layout evidence reported separately. INFO-DIV CAN, 125000 bit/s; CAN ID 0x523. PSA-RE title: IDVR_SUPERVISION. Network supervision: diagnostic session, network management state and communication fault counters Source: https://github.com/prototux/PSA-RE/blob/67f7581e7622410efdbb29c7eda3b86982b9b450/buses/AEE2010.full/LS.INFO-DIV/523.yml. Source sender alternatives: IDVR; physical TX/gateway forwarding not verified. ";
CM_ SG_ 1315 Unused4 "DATABASE_CANDIDATE: physical interpretation unverified; capture/layout evidence reported separately. PSA-RE bits 8.7-8.0. ";
CM_ SG_ 1315 Unused3 "DATABASE_CANDIDATE: physical interpretation unverified; capture/layout evidence reported separately. PSA-RE bits 7.7-7.0. ";
CM_ SG_ 1315 AbsentIdvr "DATABASE_CANDIDATE: physical interpretation unverified; capture/layout evidence reported separately. PSA-RE bits 6.7-6.0. Absent computer(s) supervised by IDVR. Upstream default raw=0 (not necessarily valid data).";
CM_ SG_ 1315 PfhmComLossCounter "DATABASE_CANDIDATE: physical interpretation unverified; capture/layout evidence reported separately. PSA-RE bits 5.7-5.0. Rolling counter incremented by 1 at each \"communication loss\" transition, reset to 0 at initialization. Upstream default raw=0 (not necessarily valid data).";
CM_ SG_ 1315 PfhmBusOffCounter "DATABASE_CANDIDATE: physical interpretation unverified; capture/layout evidence reported separately. PSA-RE bits 4.7-4.0. Rolling counter incremented by 1 at each \"bus-off\" fault, reset to 0 at initialization. Upstream default raw=0 (not necessarily valid data).";
CM_ SG_ 1315 PfhmNAsCounter "DATABASE_CANDIDATE: physical interpretation unverified; capture/layout evidence reported separately. PSA-RE bits 3.7-3.0. Rolling counter incremented at each \"message not sent\" detection, after 1 attempt on the N_As timeout; reset to 0 at initialization. Upstream default raw=0 (not necessarily valid data).";
CM_ SG_ 1315 NerrFaultCounterValue "DATABASE_CANDIDATE: physical interpretation unverified; capture/layout evidence reported separately. PSA-RE bits 2.7-2.0. Value of the NERR fault counter for the line diagnosis. Upstream default raw=0 (not necessarily valid data).";
CM_ SG_ 1315 Unused2 "DATABASE_CANDIDATE: physical interpretation unverified; capture/layout evidence reported separately. PSA-RE bits 1.2-1.0. ";
CM_ SG_ 1315 SupervisionTaskState "DATABASE_CANDIDATE: physical interpretation unverified; capture/layout evidence reported separately. PSA-RE bits 1.3. Network supervision task state. Upstream default raw=0 (not necessarily valid data).";
CM_ SG_ 1315 NerrBitStatus "DATABASE_CANDIDATE: physical interpretation unverified; capture/layout evidence reported separately. PSA-RE bits 1.4. NERR (network error) bit status. Upstream default raw=0 (not necessarily valid data).";
CM_ SG_ 1315 ComLossFault "DATABASE_CANDIDATE: physical interpretation unverified; capture/layout evidence reported separately. PSA-RE bits 1.5. Communication loss fault. Upstream default raw=0 (not necessarily valid data).";
CM_ SG_ 1315 Unused1 "DATABASE_CANDIDATE: physical interpretation unverified; capture/layout evidence reported separately. PSA-RE bits 1.7-1.6. ";
CM_ BO_ 1316 "DATABASE_CANDIDATE: physical interpretation unverified; capture/layout evidence reported separately. INFO-DIV CAN, 125000 bit/s; CAN ID 0x524. PSA-RE title: BTEL_SUPERVISION. Network supervision: diagnostic session, network management state and communication fault counters Source: https://github.com/prototux/PSA-RE/blob/67f7581e7622410efdbb29c7eda3b86982b9b450/buses/AEE2010.full/LS.INFO-DIV/524.yml. Source sender alternatives: ICSV,BTEL,OVIP; physical TX/gateway forwarding not verified. Observed 587 frames in info_apka.csv,info_buzeni_obc.csv,info_charging.csv,info_standby.csv,info_start_jizda.csv,infocan.csv; DLCs [8]. Unresolved alternative source layouts preserved in source JSON. ";
CM_ SG_ 1316 AbsentBtel3 "DATABASE_CANDIDATE: physical interpretation unverified; capture/layout evidence reported separately. PSA-RE bits 8.7-8.0. Absent computer(s) supervised by BTEL. Upstream default raw=0 (not necessarily valid data).";
CM_ SG_ 1316 AbsentBtel2 "DATABASE_CANDIDATE: physical interpretation unverified; capture/layout evidence reported separately. PSA-RE bits 7.7-7.0. Absent computer(s) supervised by BTEL. Upstream default raw=0 (not necessarily valid data).";
CM_ SG_ 1316 AbsentBtel1 "DATABASE_CANDIDATE: physical interpretation unverified; capture/layout evidence reported separately. PSA-RE bits 6.7-6.0. Absent computer(s) supervised by BTEL. Upstream default raw=0 (not necessarily valid data).";
CM_ SG_ 1316 PfhmComLossCounter "DATABASE_CANDIDATE: physical interpretation unverified; capture/layout evidence reported separately. PSA-RE bits 5.7-5.0. Rolling counter incremented by 1 at each \"communication loss\" transition, reset to 0 at initialization. Upstream default raw=0 (not necessarily valid data).";
CM_ SG_ 1316 PfhmBusOffCounter "DATABASE_CANDIDATE: physical interpretation unverified; capture/layout evidence reported separately. PSA-RE bits 4.7-4.0. Rolling counter incremented by 1 at each \"bus-off\" fault, reset to 0 at initialization. Upstream default raw=0 (not necessarily valid data).";
CM_ SG_ 1316 PfhmNAsCounter "DATABASE_CANDIDATE: physical interpretation unverified; capture/layout evidence reported separately. PSA-RE bits 3.7-3.0. Rolling counter incremented at each \"message not sent\" detection, after 1 attempt on the N_As timeout; reset to 0 at initialization. Upstream default raw=0 (not necessarily valid data).";
CM_ SG_ 1316 NerrFaultCounterValue "DATABASE_CANDIDATE: physical interpretation unverified; capture/layout evidence reported separately. PSA-RE bits 2.7-2.0. Value of the NERR fault counter for the line diagnosis. Upstream default raw=0 (not necessarily valid data).";
CM_ SG_ 1316 Unused2 "DATABASE_CANDIDATE: physical interpretation unverified; capture/layout evidence reported separately. PSA-RE bits 1.2-1.0. ";
CM_ SG_ 1316 SupervisionTaskState "DATABASE_CANDIDATE: physical interpretation unverified; capture/layout evidence reported separately. PSA-RE bits 1.3. Network supervision task state. Upstream default raw=0 (not necessarily valid data).";
CM_ SG_ 1316 NerrBitStatus "DATABASE_CANDIDATE: physical interpretation unverified; capture/layout evidence reported separately. PSA-RE bits 1.4. NERR (network error) bit status. Upstream default raw=0 (not necessarily valid data).";
CM_ SG_ 1316 ComLossFault "DATABASE_CANDIDATE: physical interpretation unverified; capture/layout evidence reported separately. PSA-RE bits 1.5. Communication loss fault. Upstream default raw=0 (not necessarily valid data).";
CM_ SG_ 1316 Unused1 "DATABASE_CANDIDATE: physical interpretation unverified; capture/layout evidence reported separately. PSA-RE bits 1.7-1.6. ";
CM_ BO_ 1317 "DATABASE_CANDIDATE: physical interpretation unverified; capture/layout evidence reported separately. INFO-DIV CAN, 125000 bit/s; CAN ID 0x525. PSA-RE title: EMF_SUPERVISION. Network supervision: diagnostic session, network management state and communication fault counters Source: https://github.com/prototux/PSA-RE/blob/67f7581e7622410efdbb29c7eda3b86982b9b450/buses/AEE2010.full/LS.INFO-DIV/525.yml. Source sender alternatives: EMF; physical TX/gateway forwarding not verified. Unresolved alternative source layouts preserved in source JSON. ";
CM_ SG_ 1317 AbsentEmf3 "DATABASE_CANDIDATE: physical interpretation unverified; capture/layout evidence reported separately. PSA-RE bits 8.7-8.0. Absent computer(s) supervised by EMF. Upstream default raw=0 (not necessarily valid data).";
CM_ SG_ 1317 AbsentEmf2 "DATABASE_CANDIDATE: physical interpretation unverified; capture/layout evidence reported separately. PSA-RE bits 7.7-7.0. Absent computer(s) supervised by EMF. Upstream default raw=0 (not necessarily valid data).";
CM_ SG_ 1317 AbsentEmf1 "DATABASE_CANDIDATE: physical interpretation unverified; capture/layout evidence reported separately. PSA-RE bits 6.7-6.0. Absent computer(s) supervised by EMF. Upstream default raw=0 (not necessarily valid data).";
CM_ SG_ 1317 PfhmComLossCounter "DATABASE_CANDIDATE: physical interpretation unverified; capture/layout evidence reported separately. PSA-RE bits 5.7-5.0. Rolling counter incremented by 1 at each \"communication loss\" transition, reset to 0 at initialization. Upstream default raw=0 (not necessarily valid data).";
CM_ SG_ 1317 PfhmBusOffCounter "DATABASE_CANDIDATE: physical interpretation unverified; capture/layout evidence reported separately. PSA-RE bits 4.7-4.0. Rolling counter incremented by 1 at each \"bus-off\" fault, reset to 0 at initialization. Upstream default raw=0 (not necessarily valid data).";
CM_ SG_ 1317 PfhmNAsCounter "DATABASE_CANDIDATE: physical interpretation unverified; capture/layout evidence reported separately. PSA-RE bits 3.7-3.0. Rolling counter incremented at each \"message not sent\" detection, after 1 attempt on the N_As timeout; reset to 0 at initialization. Upstream default raw=0 (not necessarily valid data).";
CM_ SG_ 1317 NerrFaultCounterValue "DATABASE_CANDIDATE: physical interpretation unverified; capture/layout evidence reported separately. PSA-RE bits 2.7-2.0. Value of the NERR fault counter for the line diagnosis. Upstream default raw=0 (not necessarily valid data).";
CM_ SG_ 1317 Unused2 "DATABASE_CANDIDATE: physical interpretation unverified; capture/layout evidence reported separately. PSA-RE bits 1.2-1.0. ";
CM_ SG_ 1317 SupervisionTaskState "DATABASE_CANDIDATE: physical interpretation unverified; capture/layout evidence reported separately. PSA-RE bits 1.3. Network supervision task state. Upstream default raw=0 (not necessarily valid data).";
CM_ SG_ 1317 NerrBitStatus "DATABASE_CANDIDATE: physical interpretation unverified; capture/layout evidence reported separately. PSA-RE bits 1.4. NERR (network error) bit status. Upstream default raw=0 (not necessarily valid data).";
CM_ SG_ 1317 ComLossFault "DATABASE_CANDIDATE: physical interpretation unverified; capture/layout evidence reported separately. PSA-RE bits 1.5. Communication loss fault. Upstream default raw=0 (not necessarily valid data).";
CM_ SG_ 1317 Unused1 "DATABASE_CANDIDATE: physical interpretation unverified; capture/layout evidence reported separately. PSA-RE bits 1.7-1.6. ";
CM_ BO_ 1318 "DATABASE_CANDIDATE: physical interpretation unverified; capture/layout evidence reported separately. INFO-DIV CAN, 125000 bit/s; CAN ID 0x526. PSA-RE title: WLC_SUPERVISION. Network supervision: diagnostic session, network management state and communication fault counters Source: https://github.com/prototux/PSA-RE/blob/67f7581e7622410efdbb29c7eda3b86982b9b450/buses/AEE2010.full/LS.INFO-DIV/526.yml. Source sender alternatives: WLC; physical TX/gateway forwarding not verified. ";
CM_ SG_ 1318 AbsentBtel3 "DATABASE_CANDIDATE: physical interpretation unverified; capture/layout evidence reported separately. PSA-RE bits 8.7-8.0. Absent computer(s) supervised by BTEL. Upstream default raw=0 (not necessarily valid data).";
CM_ SG_ 1318 AbsentBtel2 "DATABASE_CANDIDATE: physical interpretation unverified; capture/layout evidence reported separately. PSA-RE bits 7.7-7.0. Absent computer(s) supervised by BTEL. Upstream default raw=0 (not necessarily valid data).";
CM_ SG_ 1318 AbsentBtel1 "DATABASE_CANDIDATE: physical interpretation unverified; capture/layout evidence reported separately. PSA-RE bits 6.7-6.0. Absent computer(s) supervised by BTEL. Upstream default raw=0 (not necessarily valid data).";
CM_ SG_ 1318 PfhmComLossCounter "DATABASE_CANDIDATE: physical interpretation unverified; capture/layout evidence reported separately. PSA-RE bits 5.7-5.0. Rolling counter incremented by 1 at each \"communication loss\" transition, reset to 0 at initialization. Upstream default raw=0 (not necessarily valid data).";
CM_ SG_ 1318 PfhmBusOffCounter "DATABASE_CANDIDATE: physical interpretation unverified; capture/layout evidence reported separately. PSA-RE bits 4.7-4.0. Rolling counter incremented by 1 at each \"bus-off\" fault, reset to 0 at initialization. Upstream default raw=0 (not necessarily valid data).";
CM_ SG_ 1318 PfhmNAsCounter "DATABASE_CANDIDATE: physical interpretation unverified; capture/layout evidence reported separately. PSA-RE bits 3.7-3.0. Rolling counter incremented at each \"message not sent\" detection, after 1 attempt on the N_As timeout; reset to 0 at initialization. Upstream default raw=0 (not necessarily valid data).";
CM_ SG_ 1318 NerrFaultCounterValue "DATABASE_CANDIDATE: physical interpretation unverified; capture/layout evidence reported separately. PSA-RE bits 2.7-2.0. Value of the NERR fault counter for the line diagnosis. Upstream default raw=0 (not necessarily valid data).";
CM_ SG_ 1318 Unused2 "DATABASE_CANDIDATE: physical interpretation unverified; capture/layout evidence reported separately. PSA-RE bits 1.2-1.0. ";
CM_ SG_ 1318 SupervisionTaskState "DATABASE_CANDIDATE: physical interpretation unverified; capture/layout evidence reported separately. PSA-RE bits 1.3. Network supervision task state. Upstream default raw=0 (not necessarily valid data).";
CM_ SG_ 1318 NerrBitStatus "DATABASE_CANDIDATE: physical interpretation unverified; capture/layout evidence reported separately. PSA-RE bits 1.4. NERR (network error) bit status. Upstream default raw=0 (not necessarily valid data).";
CM_ SG_ 1318 ComLossFault "DATABASE_CANDIDATE: physical interpretation unverified; capture/layout evidence reported separately. PSA-RE bits 1.5. Communication loss fault. Upstream default raw=0 (not necessarily valid data).";
CM_ SG_ 1318 Unused1 "DATABASE_CANDIDATE: physical interpretation unverified; capture/layout evidence reported separately. PSA-RE bits 1.7-1.6. ";
CM_ BO_ 1328 "DATABASE_CANDIDATE: physical interpretation unverified; capture/layout evidence reported separately. INFO-DIV CAN, 125000 bit/s; CAN ID 0x530. PSA-RE title: VTH_SUPERVISION. Network supervision: diagnostic session, network management state and communication fault counters Source: https://github.com/prototux/PSA-RE/blob/67f7581e7622410efdbb29c7eda3b86982b9b450/buses/AEE2010.full/LS.INFO-DIV/530.yml. Source sender alternatives: VTH; physical TX/gateway forwarding not verified. ";
CM_ SG_ 1328 Unused4 "DATABASE_CANDIDATE: physical interpretation unverified; capture/layout evidence reported separately. PSA-RE bits 8.7-8.0. ";
CM_ SG_ 1328 Unused3 "DATABASE_CANDIDATE: physical interpretation unverified; capture/layout evidence reported separately. PSA-RE bits 7.7-7.0. ";
CM_ SG_ 1328 AbsentVth "DATABASE_CANDIDATE: physical interpretation unverified; capture/layout evidence reported separately. PSA-RE bits 6.7-6.0. Absent computer(s) supervised by HUD. Upstream default raw=0 (not necessarily valid data).";
CM_ SG_ 1328 PfhmComLossCounter "DATABASE_CANDIDATE: physical interpretation unverified; capture/layout evidence reported separately. PSA-RE bits 5.7-5.0. Rolling counter incremented by 1 at each \"communication loss\" transition, reset to 0 at initialization. Upstream default raw=0 (not necessarily valid data).";
CM_ SG_ 1328 PfhmBusOffCounter "DATABASE_CANDIDATE: physical interpretation unverified; capture/layout evidence reported separately. PSA-RE bits 4.7-4.0. Rolling counter incremented by 1 at each \"bus-off\" fault, reset to 0 at initialization. Upstream default raw=0 (not necessarily valid data).";
CM_ SG_ 1328 PfhmNAsCounter "DATABASE_CANDIDATE: physical interpretation unverified; capture/layout evidence reported separately. PSA-RE bits 3.7-3.0. Rolling counter incremented at each \"message not sent\" detection, after 1 attempt on the N_As timeout; reset to 0 at initialization. Upstream default raw=0 (not necessarily valid data).";
CM_ SG_ 1328 NerrFaultCounterValue "DATABASE_CANDIDATE: physical interpretation unverified; capture/layout evidence reported separately. PSA-RE bits 2.7-2.0. Value of the NERR fault counter for the line diagnosis. Upstream default raw=0 (not necessarily valid data).";
CM_ SG_ 1328 Unused2 "DATABASE_CANDIDATE: physical interpretation unverified; capture/layout evidence reported separately. PSA-RE bits 1.2-1.0. ";
CM_ SG_ 1328 SupervisionTaskState "DATABASE_CANDIDATE: physical interpretation unverified; capture/layout evidence reported separately. PSA-RE bits 1.3. Network supervision task state. Upstream default raw=0 (not necessarily valid data).";
CM_ SG_ 1328 NerrBitStatus "DATABASE_CANDIDATE: physical interpretation unverified; capture/layout evidence reported separately. PSA-RE bits 1.4. NERR (network error) bit status. Upstream default raw=0 (not necessarily valid data).";
CM_ SG_ 1328 ComLossFault "DATABASE_CANDIDATE: physical interpretation unverified; capture/layout evidence reported separately. PSA-RE bits 1.5. Communication loss fault. Upstream default raw=0 (not necessarily valid data).";
CM_ SG_ 1328 Unused1 "DATABASE_CANDIDATE: physical interpretation unverified; capture/layout evidence reported separately. PSA-RE bits 1.7-1.6. ";
CM_ BO_ 1329 "DATABASE_CANDIDATE: physical interpretation unverified; capture/layout evidence reported separately. INFO-DIV CAN, 125000 bit/s; CAN ID 0x531. PSA-RE title: SUPERVISION. Network supervision: diagnostic session, network management state and communication fault counters Source: https://github.com/prototux/PSA-RE/blob/67f7581e7622410efdbb29c7eda3b86982b9b450/buses/AEE2010.full/LS.INFO-DIV/531.yml. Source sender alternatives: CDC; physical TX/gateway forwarding not verified. ";
CM_ SG_ 1329 AbsentCdc3 "DATABASE_CANDIDATE: physical interpretation unverified; capture/layout evidence reported separately. PSA-RE bits 8.7-8.0. Absent computer(s) supervised by CDC. Upstream default raw=0 (not necessarily valid data).";
CM_ SG_ 1329 AbsentCdc2 "DATABASE_CANDIDATE: physical interpretation unverified; capture/layout evidence reported separately. PSA-RE bits 7.7-7.0. Absent computer(s) supervised by CDC. Upstream default raw=0 (not necessarily valid data).";
CM_ SG_ 1329 AbsentCdc1 "DATABASE_CANDIDATE: physical interpretation unverified; capture/layout evidence reported separately. PSA-RE bits 6.7-6.0. Absent computer(s) supervised by CDC. Upstream default raw=0 (not necessarily valid data).";
CM_ SG_ 1329 PfhmComLossCounter "DATABASE_CANDIDATE: physical interpretation unverified; capture/layout evidence reported separately. PSA-RE bits 5.7-5.0. Rolling counter incremented by 1 at each \"communication loss\" transition, reset to 0 at initialization. Upstream default raw=0 (not necessarily valid data).";
CM_ SG_ 1329 PfhmBusOffCounter "DATABASE_CANDIDATE: physical interpretation unverified; capture/layout evidence reported separately. PSA-RE bits 4.7-4.0. Rolling counter incremented by 1 at each \"bus-off\" fault, reset to 0 at initialization. Upstream default raw=0 (not necessarily valid data).";
CM_ SG_ 1329 PfhmNAsCounter "DATABASE_CANDIDATE: physical interpretation unverified; capture/layout evidence reported separately. PSA-RE bits 3.7-3.0. Rolling counter incremented at each \"message not sent\" detection, after 1 attempt on the N_As timeout; reset to 0 at initialization. Upstream default raw=0 (not necessarily valid data).";
CM_ SG_ 1329 NerrFaultCounterValue "DATABASE_CANDIDATE: physical interpretation unverified; capture/layout evidence reported separately. PSA-RE bits 2.7-2.0. Value of the NERR fault counter for the line diagnosis. Upstream default raw=0 (not necessarily valid data).";
CM_ SG_ 1329 Unused2 "DATABASE_CANDIDATE: physical interpretation unverified; capture/layout evidence reported separately. PSA-RE bits 1.2-1.0. ";
CM_ SG_ 1329 SupervisionTaskState "DATABASE_CANDIDATE: physical interpretation unverified; capture/layout evidence reported separately. PSA-RE bits 1.3. Network supervision task state. Upstream default raw=0 (not necessarily valid data).";
CM_ SG_ 1329 NerrBitStatus "DATABASE_CANDIDATE: physical interpretation unverified; capture/layout evidence reported separately. PSA-RE bits 1.4. NERR (network error) bit status. Upstream default raw=0 (not necessarily valid data).";
CM_ SG_ 1329 ComLossFault "DATABASE_CANDIDATE: physical interpretation unverified; capture/layout evidence reported separately. PSA-RE bits 1.5. Communication loss fault. Upstream default raw=0 (not necessarily valid data).";
CM_ SG_ 1329 Unused1 "DATABASE_CANDIDATE: physical interpretation unverified; capture/layout evidence reported separately. PSA-RE bits 1.7-1.6. ";
VAL_ 933 CdPlaybackModeStatus 0 "Normal mode" 1 "Random track playback" 2 "Random playback of all tracks" ;
VAL_ 933 RepeatModeStatus 0 "Normal mode" 2 "Disc repeat" ;
VAL_ 933 TrackCount 65535 "Not_available" ;
VAL_ 933 TextDataAvailable 0 "No data available" 1 "Data available" 2 "Decoding in progress" ;
VAL_ 933 SelectedListType 0 "Directory" 1 "Artist" 2 "Genre" 3 "Playlist" 6 "Unavailable" 7 "Invalid" ;
VAL_ 933 Source 0 "None (no longitudinal control)" 1 "Internal CD" 2 "USB" 3 "Streaming" ;
VAL_ 933 FileElapsedSeconds 63 "Not_available" ;
VAL_ 933 TrackChangeOrigin 0 "No track change" 1 "Automatic change" 2 "Manual change" 3 "Invalid" ;
VAL_ 933 FileElapsedMinutes 255 "Not_available" ;
VAL_ 933 CurrentTrackNumber 65535 "Not_available" ;
VAL_ 935 StoredAppearanceId16 0 "Not_available" ;
VAL_ 935 StoredAppearanceId15 0 "Not_available" ;
VAL_ 935 StoredAppearanceId14 0 "Not_available" ;
VAL_ 935 StoredAppearanceId13 0 "Not_available" ;
VAL_ 935 StoredAppearanceId12 0 "Not_available" ;
VAL_ 935 StoredAppearanceId11 0 "Not_available" ;
VAL_ 935 StoredAppearanceId10 0 "Not_available" ;
VAL_ 935 StoredAppearanceId9 0 "Not_available" ;
VAL_ 936 ZevDurationPercentCurrent_6cc313 127 "Not_available" ;
VAL_ 936 ZevDurationPercentCurrentTrip 127 "Not_available" ;
VAL_ 936 ZevDurationSecondsCurrentTrip 63 "Not_available" ;
VAL_ 936 ZevDurationMinutesCurrentTrip 63 "Not_available" ;
VAL_ 936 ZevDurationHoursCurrentTrip 2047 "Not_available" ;
VAL_ 936 TripDurationSecondsCurrent 63 "Not_available" ;
VAL_ 936 TripDurationMinutesCurrent 63 "Not_available" ;
VAL_ 936 TripDurationHoursCurrent 63 "Not_available" ;
VAL_ 937 EmergencyCallInProgress 0 "No emergency call" 1 "Emergency call in progress" ;
VAL_ 937 BreakdownCallInProgress 0 "No breakdown call" 1 "Breakdown assistance call in progress" ;
VAL_ 937 NetworkMaintainRequestMdc 0 "No hold request" 1 "Hold request" ;
VAL_ 937 SualMuteRequest 0 "No request" 1 "Requested" ;
VAL_ 961 FlowStatus 0 "ContinueToSend" 1 "Wait" 2 "Overflow" ;
VAL_ 961 IsoTpFrameType 0 "SingleFrame" 1 "FirstFrame" 2 "ConsecutiveFrame" 3 "FlowControl" ;
VAL_ 965 IdvrListAvailability 0 "Not available" 1 "Available" ;
VAL_ 965 IdvrListAcceptanceState 0 "Idle" 1 "List closing request" 2 "List mode refused" 3 "List mode accepted" ;
VAL_ 965 AutoAccidentRecordingState 0 "Not active" 1 "Active" ;
VAL_ 965 DrivingRecordingMenuState 0 "Not active" 1 "Active" ;
VAL_ 965 AccidentRecordingInProgress 0 "No video recording" 1 "Video recording" ;
VAL_ 965 AccidentMemoryUsagePercent 127 "Not_available" ;
VAL_ 965 IdvrPlaybackState 0 "No action" 1 "Play" 2 "Paused" 3 "Stopped" 4 "Reward" 5 "Forward" 6 "Previous" 7 "Next" 8 "File not readable" ;
VAL_ 965 IdvrState 0 "None" 1 "Live" 2 "Record file" 3 "ADAS camera" ;
VAL_ 965 IdvrRecording 0 "Not active" 1 "Active" ;
VAL_ 976 RearLeftSeatVentilationRequest 0 "No request" 1 "Level 1" 2 "Level 2" 3 "Level 3" ;
VAL_ 976 RearRightSeatVentilationRequest 0 "No request" 1 "Level 1" 2 "Level 2" 3 "Level 3" ;
VAL_ 976 RearLeftSeatHeatingRequest 0 "No request" 1 "Level 1" 2 "Level 2" 3 "Level 3" ;
VAL_ 976 RearRightSeatHeatingRequest 0 "No request" 1 "Level 1" 2 "Level 2" 3 "Level 3" ;
VAL_ 976 RearRightDistribution 0 "Auto comfort" 1 "Auto visibility" 2 "Feet" 3 "Ventilation" 4 "Defrosting" 5 "Foot vents" 6 "Foot vent defrosting" 7 "Ventilation defrosting" 8 "Foot/windscreen air distribution" ;
VAL_ 976 RearLeftDistribution 0 "Auto comfort" 1 "Auto visibility" 2 "Feet" 3 "Ventilation" 4 "Defrosting" 5 "Foot vents" 6 "Foot vent defrosting" 7 "Ventilation defrosting" 8 "Foot/windscreen air distribution" ;
VAL_ 976 RearClimateFunctionStatus 0 "On" 1 "On, locked" 2 "Off" 3 "Off, locked" ;
VAL_ 976 RearLeftUpdateBit 0 "Info not refreshed" 1 "Information refreshed" ;
VAL_ 976 RearRightUpdateBit 0 "Info not refreshed" 1 "Information refreshed" ;
VAL_ 976 RearRightTempSetpoint 0 "Local" 1 "X-7 °C or Y-14 °F" 2 "X-6 °C or Y-12 °F" 3 "X-5 °C or Y-10 °F" 4 "X-4 °C or Y-8 °F" 5 "X-3 °C or Y-6 °F" 6 "X-2.5 °C or Y-5 °F" 7 "X-2 °C or Y-4 °F" 8 "X-1.5 °C or Y-3 °F" 9 "X-1 °C or Y-2 °F" 10 "X-0.5 °C or Y-1 °F" 11 "Centred value X°C or Y°F" 12 "X+0.5 °C or Y+1 °F" 13 "X+1 °C or Y+2 °F" 14 "X+1.5 °C or Y+3 °F" 15 "X+2°C or Y+4°F" 16 "X+2.5°C or Y+5°F" 17 "X+3 °C or Y+6°F" 18 "X+4 °C or Y+8 °F" 19 "X+5 °C or Y+10°F" 20 "X+6 °C or Y+12 °F" 21 "X+7 °C or Y+14 °F" 22 "HI" ;
VAL_ 976 RearLeftTempSetpoint 0 "Local" 1 "X-7 °C or Y-14 °F" 2 "X-6 °C or Y-12 °F" 3 "X-5 °C or Y-10 °F" 4 "X-4 °C or Y-8 °F" 5 "X-3 °C or Y-6 °F" 6 "X-2.5 °C or Y-5 °F" 7 "X-2 °C or Y-4 °F" 8 "X-1.5 °C or Y-3 °F" 9 "X-1 °C or Y-2 °F" 10 "X-0.5 °C or Y-1 °F" 11 "Centred value X°C or Y°F" 12 "X+0.5 °C or Y+1 °F" 13 "X+1 °C or Y+2 °F" 14 "X+1.5 °C or Y+3 °F" 15 "X+2°C or Y+4°F" 16 "X+2.5°C or Y+5°F" 17 "X+3 °C or Y+6°F" 18 "X+4 °C or Y+8 °F" 19 "X+5 °C or Y+10°F" 20 "X+6 °C or Y+12 °F" 21 "X+7 °C or Y+14 °F" 22 "HI" ;
VAL_ 976 RearRightBlowerSpeed 0 "Automatic" 1 "Speed 0" 2 "Speed 1" 3 "Speed 2" 4 "Speed 3" 5 "Speed 4" 6 "Speed5" 7 "Speed 6" 8 "Speed 7" 9 "Speed 8" ;
VAL_ 976 RearLeftBlowerSpeed 0 "Automatic" 1 "Speed 0" 2 "Speed 1" 3 "Speed 2" 4 "Speed 3" 5 "Speed 4" 6 "Speed5" 7 "Speed 6" 8 "Speed 7" 9 "Speed 8" ;
VAL_ 982 TldiagFunctionRequest 0 "No request" 1 "Requested" 3 "Failure detected" ;
VAL_ 986 TripDistanceCounter 8191 "Not_available" ;
VAL_ 992 EcoTime 127 "Not_available" ;
VAL_ 992 AverageFuelConsumption6 255 "Not_available" ;
VAL_ 992 AverageFuelConsumption5 255 "Not_available" ;
VAL_ 992 AverageFuelConsumption4 255 "Not_available" ;
VAL_ 992 AverageFuelConsumption3 255 "Not_available" ;
VAL_ 992 AverageFuelConsumption2 255 "Not_available" ;
VAL_ 992 AverageFuelConsumption1 255 "Not_available" ;
VAL_ 992 BatterySocCandidate 127 "Not_available" ;
VAL_ 994 AudioDynamicModeStatus 0 "Normal mode" 1 "Dynamic mode" 3 "Invalid" ;
VAL_ 996 FlowStatus 0 "ContinueToSend" 1 "Wait" 2 "Overflow" ;
VAL_ 996 IsoTpFrameType 0 "SingleFrame" 1 "FirstFrame" 2 "ConsecutiveFrame" 3 "FlowControl" ;
VAL_ 997 Knob2SyncRequest 0 "Synchronization requested" 1 "No synchronization requested" ;
VAL_ 997 ListOpenRequest 0 "No request" 1 "Opening requested" ;
VAL_ 997 List 0 "LIST key deactivated" 1 "LIST key activated" ;
VAL_ 997 Dark 0 "Dark key deactivated" 1 "Dark key activated" ;
VAL_ 997 PhoneMenuOpenRequest 0 "No request" 1 "Requested" ;
VAL_ 997 Escape 0 "Escape key deactivated" 1 "Escape key activated" ;
VAL_ 997 Ok 0 "Validation key deactivated" 1 "Validation key activated" ;
VAL_ 997 Left 0 "Key not activated" 1 "Key activated" ;
VAL_ 997 Right 0 "Key not activated" 1 "Key activated" ;
VAL_ 997 Down 0 "Key not activated" 1 "Key activated" ;
VAL_ 997 Up 0 "Key not activated" 1 "Key activated" ;
VAL_ 997 ModeDark 0 "Key deactivated" 1 "Key activated" ;
VAL_ 997 Mode 0 "Key not activated" 1 "Key activated" ;
VAL_ 997 Menu 0 "Menu key deactivated" 1 "Menu key activated" ;
VAL_ 997 NewsMenuOpenRequest 0 "No Menu opening request" 1 "Menu opening request" ;
VAL_ 999 Distance 65535 "Not_available" ;
VAL_ 999 Time 4095 "Not_available" ;
VAL_ 999 TimeSymbol 0 "Normal (+)" 1 "Maintenance overdue (-)" ;
VAL_ 999 DistanceSymbol 0 "Normal (+)" 1 "Maintenance overdue (-)" ;
VAL_ 999 DistanceBlinking 0 "Fixed display" 1 "Blinking display" ;
VAL_ 999 MaintenanceWrenchIconDisplay 0 "Off/steady" 1 "Steady/blinking" ;
VAL_ 999 MaintenanceType2 0 "Distance-based (km)" 1 "Distance + time" ;
VAL_ 999 MaintenanceType 0 "Distance-based (km)" 1 "Time-based" ;
VAL_ 1000 ZevDistanceTrip2 65535 "Not_available" ;
VAL_ 1000 ZevDistanceTrip1 65535 "Not_available" ;
VAL_ 1000 ZevDistanceCurrentTrip 65535 "Not_available" ;
VAL_ 1000 TripDistanceCurrent 65535 "Not_available" ;
VAL_ 1014 AmbientLightTransitionSyncBit 0 "Value 1" 1 "Value 2" ;
VAL_ 1014 AmbientLightTransitionType 0 "Linear" 1 "Half sine wave" 2 "Logarithmic" 3 "Exponential" ;
VAL_ 1025 WakeupCause8 0 "Cause that did not trigger wake-up" 1 "Wake-up cause" ;
VAL_ 1025 WakeupCauseInternal 0 "Cause that did not trigger wake-up" 1 "Wake-up cause" ;
VAL_ 1025 WakeupCauseBluetooth 0 "Cause that did not trigger wake-up" 1 "Wake-up cause" ;
VAL_ 1025 WakeupCauseNfc 0 "Cause that did not trigger wake-up" 1 "Wake-up cause" ;
VAL_ 1025 WakeupCauseMlKeyPresence 0 "Cause that did not trigger wake-up" 1 "Wake-up cause" ;
VAL_ 1025 WakeupCauseMlLockButton 0 "Cause that did not trigger wake-up" 1 "Wake-up cause" ;
VAL_ 1025 WakeupCauseCoe 0 "Cause that did not trigger wake-up" 1 "Wake-up cause" ;
VAL_ 1025 WakeupCauseRfRemote 0 "Cause that did not trigger wake-up" 1 "Wake-up cause" ;
VAL_ 1042 BsiWakeupInfo0 32 "OBC cause (AC cable insertion)" ;
VAL_ 1056 WakeupCause8 0 "Cause that did not trigger wake-up" 1 "Wake-up cause" ;
VAL_ 1056 WakeupCause7 0 "Cause that did not trigger wake-up" 1 "Wake-up cause" ;
VAL_ 1056 WakeupCause6 0 "Cause that did not trigger wake-up" 1 "Wake-up cause" ;
VAL_ 1056 WakeupCause5 0 "Cause that did not trigger wake-up" 1 "Wake-up cause" ;
VAL_ 1056 WakeupCause4 0 "Cause that did not trigger wake-up" 1 "Wake-up cause" ;
VAL_ 1056 WakeupCause3 0 "Cause that did not trigger wake-up" 1 "Wake-up cause" ;
VAL_ 1056 WakeupCauseOnOffButton 0 "Cause that did not trigger wake-up" 1 "Wake-up cause" ;
VAL_ 1056 WakeupCause1 0 "Cause that did not trigger wake-up" 1 "Wake-up cause" ;
VAL_ 1060 WakeupCause8 0 "Cause that did not trigger wake-up" 1 "Wake-up cause" ;
VAL_ 1060 WakeupCause7 0 "Cause that did not trigger wake-up" 1 "Wake-up cause" ;
VAL_ 1060 WakeupCause6 0 "Cause that did not trigger wake-up" 1 "Wake-up cause" ;
VAL_ 1060 WakeupCause5 0 "Cause that did not trigger wake-up" 1 "Wake-up cause" ;
VAL_ 1060 WakeupCause4 0 "Cause that did not trigger wake-up" 1 "Wake-up cause" ;
VAL_ 1060 WakeupCause3 0 "Cause that did not trigger wake-up" 1 "Wake-up cause" ;
VAL_ 1060 WakeupCauseOnOffButton 0 "Cause that did not trigger wake-up" 1 "Wake-up cause" ;
VAL_ 1060 WakeupCauseThermalPrecond_836499 0 "Cause that did not trigger wake-up" 1 "Wake-up cause" ;
VAL_ 1084 WakeupCause8 0 "Cause that did not trigger wake-up" 1 "Wake-up cause" ;
VAL_ 1084 WakeupCause7 0 "Cause that did not trigger wake-up" 1 "Wake-up cause" ;
VAL_ 1084 WakeupCause6 0 "Cause that did not trigger wake-up" 1 "Wake-up cause" ;
VAL_ 1084 WakeupCause5 0 "Cause that did not trigger wake-up" 1 "Wake-up cause" ;
VAL_ 1084 WakeupCause4 0 "Cause that did not trigger wake-up" 1 "Wake-up cause" ;
VAL_ 1084 WakeupCause3 0 "Cause that did not trigger wake-up" 1 "Wake-up cause" ;
VAL_ 1084 WakeupCause2 0 "Cause that did not trigger wake-up" 1 "Wake-up cause" ;
VAL_ 1084 WakeupCause1 0 "Cause that did not trigger wake-up" 1 "Wake-up cause" ;
VAL_ 1153 FaultEventFrameNumber 0 "Invalid" 1 "First frame" 2 "Second frame" 3 "Third frame" ;
VAL_ 1153 FaultEventFrameCount 0 "Invalid" 1 "1 frame" 2 "2 frames" 3 "3 frames" ;
VAL_ 1164 FaultEventFrameNumber 0 "Invalid" 1 "First frame" 2 "Second frame" 3 "Third frame" ;
VAL_ 1164 FaultEventFrameCount 0 "Invalid" 1 "1 frame" 2 "2 frames" 3 "3 frames" ;
VAL_ 1181 FaultEventFrameNumber 0 "Invalid" 1 "First frame" 2 "Second frame" 3 "Third frame" ;
VAL_ 1181 FaultEventFrameCount 0 "Invalid" 1 "1 frame" 2 "2 frames" 3 "3 frames" ;
VAL_ 1183 FaultEventFrameNumber 0 "Invalid" 1 "First frame" 2 "Second frame" 3 "Third frame" ;
VAL_ 1183 FaultEventFrameCount 0 "Invalid" 1 "1 frame" 2 "2 frames" 3 "3 frames" ;
VAL_ 1184 FaultEventFrameNumber 0 "Invalid" 1 "First frame" 2 "Second frame" 3 "Third frame" ;
VAL_ 1184 FaultEventFrameCount 0 "Invalid" 1 "1 frame" 2 "2 frames" 3 "3 frames" ;
VAL_ 1187 ContextParam4 255 "Invalid" ;
VAL_ 1187 ContextParam3 255 "Invalid" ;
VAL_ 1187 ContextParam2 255 "Invalid" ;
VAL_ 1187 ContextParam1 255 "Invalid" ;
VAL_ 1187 ExtendedContextType 0 "Local contexts" 1 "BSI context" ;
VAL_ 1187 EventType 0 "Disappearance" 1 "Appearance" ;
VAL_ 1188 ContextParam4 255 "Invalid" ;
VAL_ 1188 ContextParam3 255 "Invalid" ;
VAL_ 1188 ContextParam2 255 "Invalid" ;
VAL_ 1188 ContextParam1 255 "Invalid" ;
VAL_ 1188 ExtendedContextType 0 "Local contexts" 1 "BSI context" ;
VAL_ 1188 BsiContextRelevance 0 "BSI context matching ensured" 1 "Matching of BSI contexts not ensured" ;
VAL_ 1188 EventType 0 "Disappearance" 1 "Appearance" ;
VAL_ 1189 FaultEventFrameNumber 0 "Invalid" 1 "First frame" 2 "Second frame" 3 "Third frame" ;
VAL_ 1189 FaultEventFrameCount 0 "Invalid" 1 "1 frame" 2 "2 frames" 3 "3 frames" ;
VAL_ 1190 FaultEventFrameNumber 0 "Invalid" 1 "First frame" 2 "Second frame" 3 "Third frame" ;
VAL_ 1190 FaultEventFrameCount 0 "Invalid" 1 "1 frame" 2 "2 frames" 3 "3 frames" ;
VAL_ 1200 FaultEventFrameNumber 0 "Invalid" 1 "First frame" 2 "Second frame" 3 "Third frame" ;
VAL_ 1200 FaultEventFrameCount 0 "Invalid" 1 "1 frame" 2 "2 frames" 3 "3 frames" ;
VAL_ 1201 FaultEventFrameNumber 0 "Invalid" 1 "First frame" 2 "Second frame" 3 "Third frame" ;
VAL_ 1201 FaultEventFrameCount 0 "Invalid" 1 "1 frame" 2 "2 frames" 3 "3 frames" ;
VAL_ 1202 FaultEventFrameNumber 0 "Invalid" 1 "First frame" 2 "Second frame" 3 "Third frame" ;
VAL_ 1202 FaultEventFrameCount 0 "Invalid" 1 "1 frame" 2 "2 frames" 3 "3 frames" ;
VAL_ 1203 FaultEventFrameNumber 0 "Invalid" 1 "First frame" 2 "Second frame" 3 "Third frame" ;
VAL_ 1203 FaultEventFrameCount 0 "Invalid" 1 "1 frame" 2 "2 frames" 3 "3 frames" ;
VAL_ 1206 FaultEventFrameNumber 0 "Invalid" 1 "First frame" 2 "Second frame" 3 "Third frame" ;
VAL_ 1206 FaultEventFrameCount 0 "Invalid" 1 "1 frame" 2 "2 frames" 3 "3 frames" ;
VAL_ 1211 FaultEventFrameNumber 0 "Invalid" 1 "First frame" 2 "Second frame" 3 "Third frame" ;
VAL_ 1211 FaultEventFrameCount 0 "Invalid" 1 "1 frame" 2 "2 frames" 3 "3 frames" ;
VAL_ 1212 ContextParam4 255 "Invalid" ;
VAL_ 1212 ContextParam3 255 "Invalid" ;
VAL_ 1212 ContextParam2 255 "Invalid" ;
VAL_ 1212 ContextParam1 255 "Invalid" ;
VAL_ 1212 ExtendedContextType 0 "Local contexts" 1 "BSI context" ;
VAL_ 1212 BsiContextRelevance 0 "BSI context matching ensured" 1 "Matching of BSI contexts not ensured" ;
VAL_ 1212 EventType 0 "Disappearance" 1 "Appearance" ;
VAL_ 1213 ContextParam4 255 "Invalid" ;
VAL_ 1213 ContextParam3 255 "Invalid" ;
VAL_ 1213 ContextParam2 255 "Invalid" ;
VAL_ 1213 ContextParam1 255 "Invalid" ;
VAL_ 1213 ExtendedContextType 0 "Local contexts" 1 "BSI context" ;
VAL_ 1213 EventType 0 "Disappearance" 1 "Appearance" ;
VAL_ 1281 AbsentBml 0 "No control unit absent" 18 "BSI absent" ;
VAL_ 1281 SupervisionTaskState 0 "NM disabled" 1 "NM enabled" ;
VAL_ 1281 NerrBitStatus 0 "No fault detected" 1 "Fault present" ;
VAL_ 1281 ComLossFault 0 "No fault detected" 1 "Fault present" ;
VAL_ 1292 AbsentFmux1 0 "No control unit absent" 18 "BSI absent" ;
VAL_ 1292 SupervisionTaskState 0 "NM disabled" 1 "NM enabled" ;
VAL_ 1292 NerrBitStatus 0 "No fault detected" 1 "Fault present" ;
VAL_ 1292 ComLossFault 0 "No fault detected" 1 "Fault present" ;
VAL_ 1298 SupervisionTaskState 0 "NM disabled" 1 "NM enabled" ;
VAL_ 1298 NerrBitStatus 0 "No fault detected" 1 "Fault present" ;
VAL_ 1298 ComLossFault 0 "No fault detected" 1 "Fault present" ;
VAL_ 1309 AbsentAas 0 "No control unit absent" 18 "BSI absent" ;
VAL_ 1309 SupervisionTaskState 0 "NM disabled" 1 "NM enabled" ;
VAL_ 1309 NerrBitStatus 0 "No fault detected" 1 "Fault present" ;
VAL_ 1309 ComLossFault 0 "No fault detected" 1 "Fault present" ;
VAL_ 1311 AbsentCmb3 0 "No control unit absent" 18 "Body computer absent" 32 "Radio absent" 36 "BTEL absent" 51 "KML absent" ;
VAL_ 1311 AbsentCmb2 0 "No control unit absent" 18 "Body computer absent" 32 "Radio absent" 36 "BTEL absent" 51 "KML absent" ;
VAL_ 1311 AbsentCmb1 0 "No control unit absent" 18 "Body computer absent" 32 "Radio absent" 36 "BTEL absent" 51 "KML absent" ;
VAL_ 1311 DiagnosticSessionActive 0 "Excluding diagnostic activity" 1 "Diagnostic activity in progress" ;
VAL_ 1311 UnderDiagnosisSession 0 "Outside diagnostic mode" 1 "Under diagnostic" ;
VAL_ 1311 FunctionalDegradedMode 0 "Normal mode" 1 "Degraded mode" ;
VAL_ 1311 SupervisionTaskState 0 "NM disabled" 1 "NM enabled" ;
VAL_ 1311 NerrBitStatus 0 "No fault detected" 1 "Fault present" ;
VAL_ 1311 ComLossFault 0 "No fault detected" 1 "Fault present" ;
VAL_ 1312 AbsentRad3 0 "No ECU absent" 18 "Body computer absent" 29 "AAS absent" 37 "EMF absent" 49 "CDC absent" ;
VAL_ 1312 AbsentRad2 0 "No ECU absent" 18 "Body computer absent" 29 "AAS absent" 37 "EMF absent" 49 "CDC absent" ;
VAL_ 1312 AbsentRad1 0 "No ECU absent" 18 "Body computer absent" 29 "AAS absent" 37 "EMF absent" 49 "CDC absent" ;
VAL_ 1312 SupervisionTaskState 0 "NM disabled" 1 "NM enabled" ;
VAL_ 1312 NerrBitStatus 0 "No fault detected" 1 "Fault present" ;
VAL_ 1312 ComLossFault 0 "No fault detected" 1 "Fault present" ;
VAL_ 1315 AbsentIdvr 0 "No control unit absent" 18 "BSI absent" ;
VAL_ 1315 SupervisionTaskState 0 "NM disabled" 1 "NM enabled" ;
VAL_ 1315 NerrBitStatus 0 "No fault detected" 1 "Fault present" ;
VAL_ 1315 ComLossFault 0 "No fault detected" 1 "Fault present" ;
VAL_ 1316 AbsentBtel3 0 "No control unit absent" 18 "BSI absent" 29 "AAS absent" 45 "CLIMAV absent" 49 "CDC absent" 51 "KML absent" 55 "CRT absent" ;
VAL_ 1316 AbsentBtel2 0 "No control unit absent" 18 "BSI absent" 29 "AAS absent" 45 "CLIMAV absent" 49 "CDC absent" 51 "KML absent" 55 "CRT absent" ;
VAL_ 1316 AbsentBtel1 0 "No control unit absent" 18 "BSI absent" 29 "AAS absent" 45 "CLIMAV absent" 49 "CDC absent" 51 "KML absent" 55 "CRT absent" ;
VAL_ 1316 SupervisionTaskState 0 "NM disabled" 1 "NM enabled" ;
VAL_ 1316 NerrBitStatus 0 "No fault detected" 1 "Fault present" ;
VAL_ 1316 ComLossFault 0 "No fault detected" 1 "Fault present" ;
VAL_ 1317 AbsentEmf3 0 "No control unit absent" 18 "Body computer absent" 29 "AAS absent" 32 "RADIO absent" 45 "CLIMAV absent" 51 "KML absent" ;
VAL_ 1317 AbsentEmf2 0 "No control unit absent" 18 "Body computer absent" 29 "AAS absent" 32 "RADIO absent" 45 "CLIMAV absent" 51 "KML absent" ;
VAL_ 1317 AbsentEmf1 0 "No control unit absent" 18 "Body computer absent" 29 "AAS absent" 32 "RADIO absent" 45 "CLIMAV absent" 51 "KML absent" ;
VAL_ 1317 SupervisionTaskState 0 "NM disabled" 1 "NM enabled" ;
VAL_ 1317 NerrBitStatus 0 "No fault detected" 1 "Fault present" ;
VAL_ 1317 ComLossFault 0 "No fault detected" 1 "Fault present" ;
VAL_ 1318 AbsentBtel3 0 "No control unit absent" 18 "BSI absent" 29 "AAS absent" 45 "CLIMAV absent" 49 "CDC absent" 51 "KML absent" 55 "CRT absent" ;
VAL_ 1318 AbsentBtel2 0 "No control unit absent" 18 "BSI absent" 29 "AAS absent" 45 "CLIMAV absent" 49 "CDC absent" 51 "KML absent" 55 "CRT absent" ;
VAL_ 1318 AbsentBtel1 0 "No control unit absent" 18 "BSI absent" 29 "AAS absent" 45 "CLIMAV absent" 49 "CDC absent" 51 "KML absent" 55 "CRT absent" ;
VAL_ 1318 SupervisionTaskState 0 "NM disabled" 1 "NM enabled" ;
VAL_ 1318 NerrBitStatus 0 "No fault detected" 1 "Fault present" ;
VAL_ 1318 ComLossFault 0 "No fault detected" 1 "Fault present" ;
VAL_ 1328 AbsentVth 0 "No control unit absent" 18 "BSI absent" ;
VAL_ 1328 SupervisionTaskState 0 "NM disabled" 1 "NM enabled" ;
VAL_ 1328 NerrBitStatus 0 "No fault detected" 1 "Fault present" ;
VAL_ 1328 ComLossFault 0 "No fault detected" 1 "Fault present" ;
VAL_ 1329 AbsentCdc3 0 "No control unit absent" 18 "Body computer absent" 32 "RADIO absent" ;
VAL_ 1329 AbsentCdc2 0 "No control unit absent" 18 "Body computer absent" 32 "RADIO absent" ;
VAL_ 1329 AbsentCdc1 0 "No control unit absent" 18 "Body computer absent" 32 "RADIO absent" ;
VAL_ 1329 SupervisionTaskState 0 "NM disabled" 1 "NM enabled" ;
VAL_ 1329 NerrBitStatus 0 "No fault detected" 1 "Fault present" ;
VAL_ 1329 ComLossFault 0 "No fault detected" 1 "Fault present" ;
SG_MUL_VAL_ 961 SingleFrameLength IsoTpFrameType 0-0;
SG_MUL_VAL_ 961 FirstFrameLength IsoTpFrameType 1-1;
SG_MUL_VAL_ 961 ConsecutiveSequence IsoTpFrameType 2-2;
SG_MUL_VAL_ 961 FlowStatus IsoTpFrameType 3-3;
SG_MUL_VAL_ 961 UnknownPciLow IsoTpFrameType 4-15;
SG_MUL_VAL_ 961 BlockSize IsoTpFrameType 3-3;
SG_MUL_VAL_ 961 SingleData1 IsoTpFrameType 0-0;
SG_MUL_VAL_ 961 ConsecutiveData1 IsoTpFrameType 2-2;
SG_MUL_VAL_ 961 UnknownData1 IsoTpFrameType 4-15;
SG_MUL_VAL_ 961 SeparationTimeRaw IsoTpFrameType 3-3;
SG_MUL_VAL_ 961 SingleData2 IsoTpFrameType 0-0;
SG_MUL_VAL_ 961 ConsecutiveData2 IsoTpFrameType 2-2;
SG_MUL_VAL_ 961 UnknownData2 IsoTpFrameType 4-15;
SG_MUL_VAL_ 961 FirstData1 IsoTpFrameType 1-1;
SG_MUL_VAL_ 961 SingleData3 IsoTpFrameType 0-0;
SG_MUL_VAL_ 961 ConsecutiveData3 IsoTpFrameType 2-2;
SG_MUL_VAL_ 961 UnknownData3 IsoTpFrameType 4-15;
SG_MUL_VAL_ 961 FirstData2 IsoTpFrameType 1-1;
SG_MUL_VAL_ 961 FlowPadding1 IsoTpFrameType 3-3;
SG_MUL_VAL_ 961 SingleData4 IsoTpFrameType 0-0;
SG_MUL_VAL_ 961 ConsecutiveData4 IsoTpFrameType 2-2;
SG_MUL_VAL_ 961 UnknownData4 IsoTpFrameType 4-15;
SG_MUL_VAL_ 961 FirstData3 IsoTpFrameType 1-1;
SG_MUL_VAL_ 961 FlowPadding2 IsoTpFrameType 3-3;
SG_MUL_VAL_ 961 SingleData5 IsoTpFrameType 0-0;
SG_MUL_VAL_ 961 ConsecutiveData5 IsoTpFrameType 2-2;
SG_MUL_VAL_ 961 UnknownData5 IsoTpFrameType 4-15;
SG_MUL_VAL_ 961 FirstData4 IsoTpFrameType 1-1;
SG_MUL_VAL_ 961 FlowPadding3 IsoTpFrameType 3-3;
SG_MUL_VAL_ 961 SingleData6 IsoTpFrameType 0-0;
SG_MUL_VAL_ 961 ConsecutiveData6 IsoTpFrameType 2-2;
SG_MUL_VAL_ 961 UnknownData6 IsoTpFrameType 4-15;
SG_MUL_VAL_ 961 FirstData5 IsoTpFrameType 1-1;
SG_MUL_VAL_ 961 FlowPadding4 IsoTpFrameType 3-3;
SG_MUL_VAL_ 961 SingleData7 IsoTpFrameType 0-0;
SG_MUL_VAL_ 961 ConsecutiveData7 IsoTpFrameType 2-2;
SG_MUL_VAL_ 961 UnknownData7 IsoTpFrameType 4-15;
SG_MUL_VAL_ 961 FirstData6 IsoTpFrameType 1-1;
SG_MUL_VAL_ 961 FlowPadding5 IsoTpFrameType 3-3;
SG_MUL_VAL_ 996 SingleFrameLength IsoTpFrameType 0-0;
SG_MUL_VAL_ 996 FirstFrameLength IsoTpFrameType 1-1;
SG_MUL_VAL_ 996 ConsecutiveSequence IsoTpFrameType 2-2;
SG_MUL_VAL_ 996 FlowStatus IsoTpFrameType 3-3;
SG_MUL_VAL_ 996 UnknownPciLow IsoTpFrameType 4-15;
SG_MUL_VAL_ 996 BlockSize IsoTpFrameType 3-3;
SG_MUL_VAL_ 996 SingleData1 IsoTpFrameType 0-0;
SG_MUL_VAL_ 996 ConsecutiveData1 IsoTpFrameType 2-2;
SG_MUL_VAL_ 996 UnknownData1 IsoTpFrameType 4-15;
SG_MUL_VAL_ 996 SeparationTimeRaw IsoTpFrameType 3-3;
SG_MUL_VAL_ 996 SingleData2 IsoTpFrameType 0-0;
SG_MUL_VAL_ 996 ConsecutiveData2 IsoTpFrameType 2-2;
SG_MUL_VAL_ 996 UnknownData2 IsoTpFrameType 4-15;
SG_MUL_VAL_ 996 FirstData1 IsoTpFrameType 1-1;
SG_MUL_VAL_ 996 SingleData3 IsoTpFrameType 0-0;
SG_MUL_VAL_ 996 ConsecutiveData3 IsoTpFrameType 2-2;
SG_MUL_VAL_ 996 UnknownData3 IsoTpFrameType 4-15;
SG_MUL_VAL_ 996 FirstData2 IsoTpFrameType 1-1;
SG_MUL_VAL_ 996 FlowPadding1 IsoTpFrameType 3-3;
SG_MUL_VAL_ 996 SingleData4 IsoTpFrameType 0-0;
SG_MUL_VAL_ 996 ConsecutiveData4 IsoTpFrameType 2-2;
SG_MUL_VAL_ 996 UnknownData4 IsoTpFrameType 4-15;
SG_MUL_VAL_ 996 FirstData3 IsoTpFrameType 1-1;
SG_MUL_VAL_ 996 FlowPadding2 IsoTpFrameType 3-3;
SG_MUL_VAL_ 996 SingleData5 IsoTpFrameType 0-0;
SG_MUL_VAL_ 996 ConsecutiveData5 IsoTpFrameType 2-2;
SG_MUL_VAL_ 996 UnknownData5 IsoTpFrameType 4-15;
SG_MUL_VAL_ 996 FirstData4 IsoTpFrameType 1-1;
SG_MUL_VAL_ 996 FlowPadding3 IsoTpFrameType 3-3;
SG_MUL_VAL_ 996 SingleData6 IsoTpFrameType 0-0;
SG_MUL_VAL_ 996 ConsecutiveData6 IsoTpFrameType 2-2;
SG_MUL_VAL_ 996 UnknownData6 IsoTpFrameType 4-15;
SG_MUL_VAL_ 996 FirstData5 IsoTpFrameType 1-1;
SG_MUL_VAL_ 996 FlowPadding4 IsoTpFrameType 3-3;
SG_MUL_VAL_ 996 SingleData7 IsoTpFrameType 0-0;
SG_MUL_VAL_ 996 ConsecutiveData7 IsoTpFrameType 2-2;
SG_MUL_VAL_ 996 UnknownData7 IsoTpFrameType 4-15;
SG_MUL_VAL_ 996 FirstData6 IsoTpFrameType 1-1;
SG_MUL_VAL_ 996 FlowPadding5 IsoTpFrameType 3-3;
